VERSION ""

NS_ :

BS_:

BU_: DCM CCU C_ECU C_ECU_GW

BO_ 552 RDR228: 8 C_ECU_GW
 SG_ RDR228_7_0_EYE_TIMEOUT_ERROR_FLG : 56|1@1+ (1,0) [0|1] "" Vector__XXX
 SG_ RDR228_7_1_BLOCKAGE_FORMING_2 : 57|1@1+ (1,0) [0|1] "" Vector__XXX
 SG_ RDR228_7_2_WARN_LCA_R_1ST : 58|1@1+ (1,0) [0|1] "" Vector__XXX
 SG_ RDR228_7_3_WARN_LCA_L_1ST : 59|1@1+ (1,0) [0|1] "" Vector__XXX
 SG_ RDR228_7_4_WARN_LCA_R_2ND : 60|1@1+ (1,0) [0|1] "" Vector__XXX
 SG_ RDR228_7_5_WARN_LCA_L_2ND : 61|1@1+ (1,0) [0|1] "" Vector__XXX
 SG_ RDR228_7_6_WARN_RCTA_R : 62|1@1+ (1,0) [0|1] ""  CCU
 SG_ RDR228_7_7_WARN_RCTA_L : 63|1@1+ (1,0) [0|1] ""  CCU
 SG_ RDR228_6_0_WARN_BSD_R_1ST : 48|1@1+ (1,0) [0|1] "" Vector__XXX
 SG_ RDR228_6_1_WARN_BSD_L_1ST : 49|1@1+ (1,0) [0|1] "" Vector__XXX
 SG_ RDR228_6_2_WARN_BSD_R_2ND : 50|1@1+ (1,0) [0|1] "" Vector__XXX
 SG_ RDR228_6_3_WARN_BSD_L_2ND : 51|1@1+ (1,0) [0|1] "" Vector__XXX
 SG_ RDR228_6_5_BLOCKAGE_STS : 53|3@1+ (1,0) [0|5] "" Vector__XXX
 SG_ RDR228_5_0_BSD_R_E : 40|1@1+ (1,0) [0|1] "" Vector__XXX
 SG_ RDR228_5_1_BSD_L_E : 41|1@1+ (1,0) [0|1] "" Vector__XXX
 SG_ RDR228_5_2_LCA_R_E : 42|1@1+ (1,0) [0|1] "" Vector__XXX
 SG_ RDR228_5_3_LCA_L_E : 43|1@1+ (1,0) [0|1] "" Vector__XXX
 SG_ RDR228_5_4_BSD_R_A : 44|1@1+ (1,0) [0|1] "" Vector__XXX
 SG_ RDR228_5_5_BSD_L_A : 45|1@1+ (1,0) [0|1] "" Vector__XXX
 SG_ RDR228_5_6_LCA_R_A : 46|1@1+ (1,0) [0|1] "" Vector__XXX
 SG_ RDR228_5_7_LCA_L_A : 47|1@1+ (1,0) [0|1] "" Vector__XXX
 SG_ RDR228_4_0_DOW_ACTIVELAMP : 32|1@1+ (1,0) [0|1] "" Vector__XXX
 SG_ RDR228_4_1_WARN_DOW_1ST_R : 33|1@1+ (1,0) [0|1] "" Vector__XXX
 SG_ RDR228_4_2_WARN_DOW_1ST_L : 34|1@1+ (1,0) [0|1] "" Vector__XXX
 SG_ RDR228_4_3_WARN_DOW_2ST_R : 35|1@1+ (1,0) [0|1] "" Vector__XXX
 SG_ RDR228_4_4_WARN_DOW_2ST_L : 36|1@1+ (1,0) [0|1] "" Vector__XXX
 SG_ RDR228_4_5_CSTM_STS_SRVD : 37|1@1+ (1,0) [0|1] ""  CCU
 SG_ RDR228_4_6_CSTM_STS_BSD_LCA_2ND : 38|1@1+ (1,0) [0|1] ""  CCU
 SG_ RDR228_4_7_CSTM_STS_RCTA : 39|1@1+ (1,0) [0|1] ""  CCU
 SG_ RDR228_3_0_WARN_BSD_LCA_R_2ND : 24|1@1+ (1,0) [0|1] ""  CCU
 SG_ RDR228_3_1_WARN_BSD_LCA_L_2ND : 25|1@1+ (1,0) [0|1] ""  CCU
 SG_ RDR228_3_2_CSTM_STS_DOW : 26|1@1+ (1,0) [0|1] ""  CCU
 SG_ RDR228_3_3_CSTM_STS_DOW_SFT_POS : 27|1@1+ (1,0) [0|1] ""  CCU
 SG_ RDR228_3_5_CSTM_DSP_BSD_LCA : 29|1@1+ (1,0) [0|1] ""  CCU
 SG_ RDR228_3_6_CSTM_DSP_BSD_LCA_2ND : 30|1@1+ (1,0) [0|1] ""  CCU
 SG_ RDR228_3_7_CSTM_DSP_RCTA : 31|1@1+ (1,0) [0|1] ""  CCU
 SG_ RDR228_2_0_CSTM_DSP_DOW : 16|1@1+ (1,0) [0|1] ""  CCU
 SG_ RDR228_2_1_EYE_LOCAL_BUS1_FAIL : 17|1@1+ (1,0) [0|1] "" Vector__XXX
 SG_ RDR228_2_2_CSTM_DSP_DOW_SFT_POS : 18|1@1+ (1,0) [0|1] ""  CCU
 SG_ RDR228_2_3_ELK_STOP_REQ_FLG : 19|1@1+ (1,0) [0|1] "" Vector__XXX
 SG_ RDR228_2_4_FAIL_RDRSYS : 20|1@1+ (1,0) [0|1] "" Vector__XXX
 SG_ RDR228_2_5_STOP_RDRSYS : 21|1@1+ (1,0) [0|1] "" Vector__XXX
 SG_ RDR228_2_6_ON_OFF_RDRSYS : 22|1@1+ (1,0) [0|1] ""  CCU
 SG_ RDR228_2_7_BLOCKAGE_FORMING : 23|1@1+ (1,0) [0|1] "" Vector__XXX
 SG_ RDR228_1_0_MSG_COUNTER : 8|4@1+ (1,0) [0|15] ""  CCU
 SG_ RDR228_1_4_BATT_OFF_CAUSE : 12|1@1+ (1,0) [0|1] "" Vector__XXX
 SG_ RDR228_1_5_CSTM_GLO_1 : 13|1@1+ (1,0) [0|1] ""  CCU
 SG_ RDR228_1_6_CSTM_GLO_3 : 14|1@1+ (1,0) [0|1] ""  CCU
 SG_ RDR228_1_7_CSTM_GLO_2 : 15|1@1+ (1,0) [0|1] ""  CCU
 SG_ RDR228_0_0_CHECK_SUM : 0|8@1+ (1,0) [0|255] ""  CCU

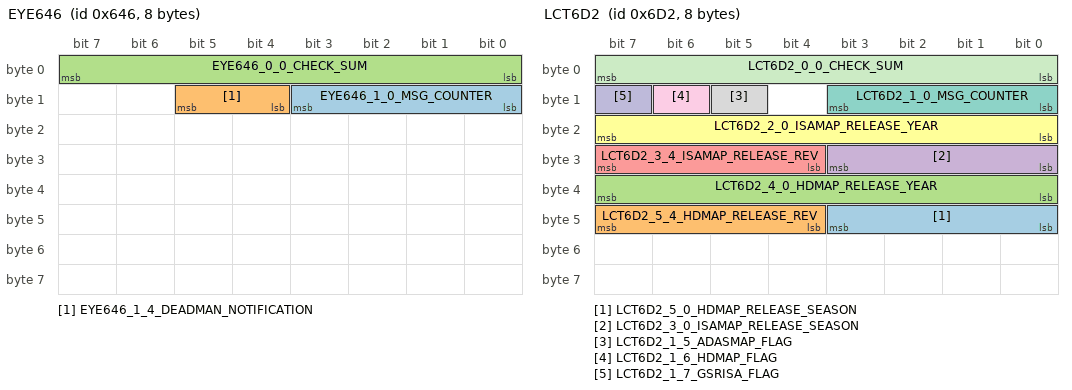
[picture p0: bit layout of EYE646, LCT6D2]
BO_ 1606 EYE646: 8 C_ECU_GW
 SG_ EYE646_1_0_MSG_COUNTER : 8|4@1+ (1,0) [0|15] ""  DCM
 SG_ EYE646_1_4_DEADMAN_NOTIFICATION : 12|2@1+ (1,0) [0|3] ""  DCM
 SG_ EYE646_0_0_CHECK_SUM : 0|8@1+ (1,0) [0|255] ""  DCM

BO_ 965 EYE3C5: 8 C_ECU_GW
 SG_ EYE3C5_7_0_GSR_AEBS_FUNC_INFO : 56|1@1+ (1,0) [0|1] ""  CCU
 SG_ EYE3C5_7_1_CSTM_CRV_ADJUST : 57|2@1+ (1,0) [0|3] ""  CCU
 SG_ EYE3C5_7_3_BRAKE_HAPTIC_CURR : 59|2@1+ (1,0) [0|3] ""  CCU
 SG_ EYE3C5_7_5_SAFETY_MODE_FUNC_INFO : 61|1@1+ (1,0) [0|1] ""  CCU
 SG_ EYE3C5_7_6_SAFETY_MODE_CURR : 62|1@1+ (1,0) [0|1] ""  CCU
 SG_ EYE3C5_7_7_GSR_DDAW_FUNC_INFO : 63|1@1+ (1,0) [0|1] ""  CCU
 SG_ EYE3C5_6_0_IND_SAFETY_MODE : 48|1@1+ (1,0) [0|1] "" Vector__XXX
 SG_ EYE3C5_6_1_ALC_ACTIVE_L : 49|1@1+ (1,0) [0|1] "" Vector__XXX
 SG_ EYE3C5_6_2_FLASHING_IND_SAFETY : 50|1@1+ (1,0) [0|1] "" Vector__XXX
 SG_ EYE3C5_6_3_OVERTAKE_FUNC_INFO : 51|1@1+ (1,0) [0|1] ""  CCU
 SG_ EYE3C5_6_4_CRV_ADJUST_FUNC_INFO : 52|1@1+ (1,0) [0|1] ""  CCU
 SG_ EYE3C5_6_5_STRG_TOUCHSENSOR_WRNG : 53|1@1+ (1,0) [0|1] "" Vector__XXX
 SG_ EYE3C5_6_6_ALC_ACTIVE_R : 54|1@1+ (1,0) [0|1] "" Vector__XXX
 SG_ EYE3C5_6_7_CSTM_GSR_ISA : 55|1@1+ (1,0) [0|1] ""  CCU
 SG_ EYE3C5_5_0_LANE_COLOR_R : 40|2@1+ (1,0) [0|3] "" Vector__XXX
 SG_ EYE3C5_5_2_LINE_LANE_R : 42|2@1+ (1,0) [0|3] "" Vector__XXX
 SG_ EYE3C5_5_4_LANE_COLOR_L : 44|2@1+ (1,0) [0|3] "" Vector__XXX
 SG_ EYE3C5_5_6_LINE_LANE_L : 46|2@1+ (1,0) [0|3] "" Vector__XXX
 SG_ EYE3C5_4_0_ROAD_SHAPE_CURVE : 32|4@1+ (1,0) [0|15] "" Vector__XXX
 SG_ EYE3C5_4_4_ROAD_SHAPE_DIRECTION : 36|1@1+ (1,0) [0|1] "" Vector__XXX
 SG_ EYE3C5_4_5_CSTM_GSR_ELKS : 37|1@1+ (1,0) [0|1] ""  CCU
 SG_ EYE3C5_4_6_MY_WAY_COLOR : 38|2@1+ (1,0) [0|3] "" Vector__XXX
 SG_ EYE3C5_3_0_AD_DRV_ICON : 24|2@1+ (1,0) [0|3] "" Vector__XXX
 SG_ EYE3C5_3_2_AUTO_HANDLE_ICON : 26|2@1+ (1,0) [0|3] "" Vector__XXX
 SG_ EYE3C5_3_4_WITH_HANDS_ICON : 28|1@1+ (1,0) [0|1] ""  CCU
 SG_ EYE3C5_3_5_STRG_HAPTIC_WRNG : 29|1@1+ (1,0) [0|1] "" Vector__XXX
 SG_ EYE3C5_3_6_BRK_HPTC_FUNC_INFO : 30|1@1+ (1,0) [0|1] ""  CCU
 SG_ EYE3C5_3_7_SPECIAL_DISP_INFO : 31|1@1+ (1,0) [0|1] ""  CCU
 SG_ EYE3C5_2_0_SLOWDWN_CURVE_ICON : 16|3@1+ (1,0) [0|7] "" Vector__XXX
 SG_ EYE3C5_2_3_FLASHING_IND : 19|1@1+ (1,0) [0|1] "" Vector__XXX
 SG_ EYE3C5_2_4_ATTENTION_TOLLGATE : 20|2@1+ (1,0) [0|3] "" Vector__XXX
 SG_ EYE3C5_2_6_MAPLOCATOR_IND : 22|2@1+ (1,0) [0|3] "" Vector__XXX
 SG_ EYE3C5_1_0_MSG_COUNTER : 8|4@1+ (1,0) [0|15] "" Vector__XXX
 SG_ EYE3C5_1_4_ISA_FAIL_IND : 12|1@1+ (1,0) [0|1] "" Vector__XXX
 SG_ EYE3C5_1_5_SLWF_OFF_IND : 13|1@1+ (1,0) [0|1] "" Vector__XXX
 SG_ EYE3C5_1_6_CSTM_SLWF_SET : 14|1@1+ (1,0) [0|1] ""  CCU
 SG_ EYE3C5_1_7_CSTM_TSR_SOUND_SET : 15|1@1+ (1,0) [0|1] ""  CCU
 SG_ EYE3C5_0_0_CHECK_SUM : 0|8@1+ (1,0) [0|255] "" Vector__XXX

BO_ 964 EYE3C4: 8 C_ECU_GW
 SG_ EYE3C4_7_0_PCR_FAIL_OFF_IND : 56|2@1+ (1,0) [0|3] "" Vector__XXX
 SG_ EYE3C4_7_2_AES_FAIL_OFF_IND : 58|2@1+ (1,0) [0|3] "" Vector__XXX
 SG_ EYE3C4_7_4_LDP_FAIL_OFF_IND : 60|2@1+ (1,0) [0|3] "" Vector__XXX
 SG_ EYE3C4_7_6_ELK_FAIL_OFF_IND : 62|2@1+ (1,0) [0|3] "" Vector__XXX
 SG_ EYE3C4_6_0_MCAM_SYS_FAIL_HALT : 48|2@1+ (1,0) [0|3] "" Vector__XXX
 SG_ EYE3C4_6_2_MCAM_FUNC_INFO : 50|1@1+ (1,0) [0|1] "" Vector__XXX
 SG_ EYE3C4_6_3_EYE_DRV_ACTION_REQ : 51|3@1+ (1,0) [0|7] "" Vector__XXX
 SG_ EYE3C4_6_6_LDW_SND_OFF_FAIL_IND : 54|2@1+ (1,0) [0|3] "" Vector__XXX
 SG_ EYE3C4_5_0_EAM_GREEN : 40|2@1+ (1,0) [0|3] "" Vector__XXX
 SG_ EYE3C4_5_2_EAM_BLUE : 42|2@1+ (1,0) [0|3] "" Vector__XXX
 SG_ EYE3C4_5_4_EAM_GREEN_2 : 44|2@1+ (1,0) [0|3] "" Vector__XXX
 SG_ EYE3C4_5_6_FCW_SND_OFF_FAIL_IND : 46|2@1+ (1,0) [0|3] "" Vector__XXX
 SG_ EYE3C4_4_0_EAM_YELLOW : 32|4@1+ (1,0) [0|15] "" Vector__XXX
 SG_ EYE3C4_4_4_EAM_RED : 36|4@1+ (1,0) [0|15] "" Vector__XXX
 SG_ EYE3C4_3_0_CODE_NO_BUZZER : 24|8@1+ (1,0) [0|255] "" Vector__XXX
 SG_ EYE3C4_2_0_CODE_WARN : 16|8@1+ (1,0) [0|255] ""  CCU
 SG_ EYE3C4_1_0_MSG_COUNTER : 8|4@1+ (1,0) [0|15] "" Vector__XXX
 SG_ EYE3C4_1_5_SNR_DRV_ACTION_REQ : 13|3@1+ (1,0) [0|7] "" Vector__XXX
 SG_ EYE3C4_0_0_CHECK_SUM : 0|8@1+ (1,0) [0|255] "" Vector__XXX

BO_ 805 EYE325: 8 C_ECU_GW
 SG_ EYE325_6_5_SONAR_DISP_INT : 53|1@1+ (1,0) [0|1] "" Vector__XXX
 SG_ EYE325_5_0_SONAR_R_L_CORNER_4LVL : 40|3@1+ (1,0) [0|7] ""  CCU
 SG_ EYE325_5_3_SONAR_R_R_CORNER_4LVL : 43|3@1+ (1,0) [0|7] ""  CCU
 SG_ EYE325_4_0_SONAR_R_CENTER : 32|3@1+ (1,0) [0|7] ""  CCU
 SG_ EYE325_4_3_SONAR_LEVEL : 35|3@1+ (1,0) [0|7] "" Vector__XXX
 SG_ EYE325_4_6_RAB_WARNING : 38|2@1+ (1,0) [0|3] ""  CCU
 SG_ EYE325_3_0_SONAR_R_L_CORNER : 24|2@1+ (1,0) [0|3] "" Vector__XXX
 SG_ EYE325_3_2_SONAR_R_R_CORNER : 26|2@1+ (1,0) [0|3] "" Vector__XXX
 SG_ EYE325_3_4_SONAR_R_L_SIDE : 28|2@1+ (1,0) [0|3] "" Vector__XXX
 SG_ EYE325_3_6_SONAR_R_R_SIDE : 30|2@1+ (1,0) [0|3] "" Vector__XXX
 SG_ EYE325_2_0_RAB_OFF : 16|1@1+ (1,0) [0|1] ""  CCU
 SG_ EYE325_2_1_SONAR_OFF : 17|1@1+ (1,0) [0|1] ""  CCU
 SG_ EYE325_2_2_SONAR_SYS_HALT : 18|2@1+ (1,0) [0|3] ""  CCU
 SG_ EYE325_2_4_SONAR_SYS_FAIL : 20|2@1+ (1,0) [0|3] ""  CCU
 SG_ EYE325_2_6_RAB_DISABLE : 22|1@1+ (1,0) [0|1] ""  CCU
 SG_ EYE325_2_7_SONAR_DISABLE : 23|1@1+ (1,0) [0|1] ""  CCU
 SG_ EYE325_1_0_MSG_COUNTER : 8|4@1+ (1,0) [0|15] ""  CCU
 SG_ EYE325_1_4_CSTM_RAB_SET : 12|1@1+ (1,0) [0|1] ""  CCU
 SG_ EYE325_1_5_CSTM_CLR_SNR_SET : 13|1@1+ (1,0) [0|1] ""  CCU
 SG_ EYE325_1_6_RAB : 14|1@1+ (1,0) [0|1] ""  CCU
 SG_ EYE325_1_7_SONAR_NO_DISP : 15|1@1+ (1,0) [0|1] "" Vector__XXX
 SG_ EYE325_0_0_CHECK_SUM : 0|8@1+ (1,0) [0|255] ""  CCU

BO_ 803 EYE323: 8 C_ECU_GW
 SG_ EYE323_7_0_ISA_OFFSET_CURR : 56|5@1+ (1,-10) [-10|10] ""  CCU
 SG_ EYE323_7_5_SLIF_FUNC_INFO : 61|1@1+ (1,0) [0|1] ""  CCU
 SG_ EYE323_7_6_ISA_FUNC_INFO : 62|1@1+ (1,0) [0|1] ""  CCU
 SG_ EYE323_7_7_ISA_CUSTOMIZE_CURR : 63|1@1+ (1,0) [0|1] ""  CCU
 SG_ EYE323_6_0_LDW_OFFSW_INFO : 48|1@1+ (1,0) [0|1] "" Vector__XXX
 SG_ EYE323_6_1_LDW_ON_OFF_SET : 49|1@1+ (1,0) [0|1] ""  CCU
 SG_ EYE323_6_2_CSTM_DDAW_WARN_SET : 50|1@1+ (1,0) [0|1] ""  CCU
 SG_ EYE323_6_3_IACC_FUNC_INFO : 51|1@1+ (1,0) [0|1] ""  CCU
 SG_ EYE323_6_5_CSTM_LDW_TIMING_SET : 53|1@1+ (1,0) [0|1] ""  CCU
 SG_ EYE323_6_6_CSTM_LDW_TIMING : 54|1@1+ (1,0) [0|1] ""  CCU
 SG_ EYE323_6_7_SLOWDOWNL_FUNC_INFO : 55|1@1+ (1,0) [0|1] ""  CCU
 SG_ EYE323_5_0_CNG_GRN_CONT_CURR : 40|1@1+ (1,0) [0|1] ""  CCU
 SG_ EYE323_5_1_TRAFFIC_FUNC_INFO : 41|1@1+ (1,0) [0|1] ""  CCU
 SG_ EYE323_5_2_FCW_OFFSW_INFO : 42|1@1+ (1,0) [0|1] "" Vector__XXX
 SG_ EYE323_5_3_FCW_ON_OFF_SET : 43|1@1+ (1,0) [0|1] ""  CCU
 SG_ EYE323_5_4_WARNING_SEL_CURR : 44|1@1+ (1,0) [0|1] ""  CCU
 SG_ EYE323_5_5_HAPT_FUNC_INFO : 45|1@1+ (1,0) [0|1] ""  CCU
 SG_ EYE323_5_6_TOLLGATE_CONT_CURR : 46|1@1+ (1,0) [0|1] ""  CCU
 SG_ EYE323_5_7_CURVE_CONT_CURR : 47|1@1+ (1,0) [0|1] ""  CCU
 SG_ EYE323_4_0_FCTB_ICON_L : 32|2@1+ (1,0) [0|3] "" Vector__XXX
 SG_ EYE323_4_2_FCTB_ICON_R : 34|2@1+ (1,0) [0|3] "" Vector__XXX
 SG_ EYE323_4_4_FCW_CONT_CURR : 36|2@1+ (1,0) [0|3] ""  CCU
 SG_ EYE323_4_6_FCW_DISPLAY_SEL : 38|2@1+ (1,0) [0|3] ""  CCU
 SG_ EYE323_3_0_AES_FUNC_INFO : 24|1@1+ (1,0) [0|1] "" Vector__XXX
 SG_ EYE323_3_1_CSTM_TSR_NO_ENTRY_SET : 25|1@1+ (1,0) [0|1] ""  CCU
 SG_ EYE323_3_2_CSTM_TSR_STOP_SET : 26|1@1+ (1,0) [0|1] ""  CCU
 SG_ EYE323_3_3_CSTM_TSR_GIVE_WAY_SET : 27|1@1+ (1,0) [0|1] ""  CCU
 SG_ EYE323_3_4_WILDERNESS : 28|1@1+ (1,0) [0|1] "" Vector__XXX
 SG_ EYE323_3_5_AES_OFF : 29|1@1+ (1,0) [0|1] "" Vector__XXX
 SG_ EYE323_3_6_FCTB_IND : 30|2@1+ (1,0) [0|3] "" Vector__XXX
 SG_ EYE323_2_0_CSTM_LDW_ALK_B : 16|2@1+ (1,0) [0|3] ""  CCU
 SG_ EYE323_2_2_CSTM_P_CR : 18|1@1+ (1,0) [0|1] ""  CCU
 SG_ EYE323_2_3_SLOWDOWN_FUNC_INFO2 : 19|1@1+ (1,0) [0|1] ""  CCU
 SG_ EYE323_2_4_CID_CODE_WARN : 20|4@1+ (1,0) [0|15] ""  CCU
 SG_ EYE323_1_0_MSG_COUNTER : 8|4@1+ (1,0) [0|15] ""  CCU
 SG_ EYE323_1_4_DISP_FOLLOW_FORWARD : 12|1@1+ (1,0) [0|1] "" Vector__XXX
 SG_ EYE323_1_5_KEEP_LINE_SENTER_ACT : 13|1@1+ (1,0) [0|1] ""  CCU
 SG_ EYE323_1_6_DDAW_FAIL_OFF : 14|2@1+ (1,0) [0|3] "" Vector__XXX
 SG_ EYE323_0_0_CHECK_SUM : 0|8@1+ (1,0) [0|255] ""  CCU

BO_ 802 EYE322: 8 C_ECU_GW
 SG_ EYE322_7_0_CSTM_ACC_CONT_SET : 56|2@1+ (1,0) [0|3] ""  CCU
 SG_ EYE322_7_2_ELK_OFF_IND : 58|1@1+ (1,0) [0|1] ""  CCU
 SG_ EYE322_7_3_LIGHT_EAM_YELLOW : 59|2@1+ (1,0) [0|3] "" Vector__XXX
 SG_ EYE322_7_5_BROKEN_LINE_L : 61|1@1+ (1,0) [0|1] "" Vector__XXX
 SG_ EYE322_7_6_TJA_ACTIVE : 62|1@1+ (1,0) [0|1] "" Vector__XXX
 SG_ EYE322_7_7_BROKEN_LINE_R : 63|1@1+ (1,0) [0|1] "" Vector__XXX
 SG_ EYE322_6_0_CSTM_MIS_AT_START : 48|2@1+ (1,0) [0|3] ""  CCU
 SG_ EYE322_6_2_CSTM_ALK_TJA_SET : 50|1@1+ (1,0) [0|1] ""  CCU
 SG_ EYE322_6_3_CSTM_LANE_SET : 51|1@1+ (1,0) [0|1] ""  CCU
 SG_ EYE322_6_4_LDP_OFF_IND : 52|1@1+ (1,0) [0|1] "" Vector__XXX
 SG_ EYE322_6_5_INDICATOR_MODE_L : 53|2@1+ (1,0) [0|3] "" Vector__XXX
 SG_ EYE322_6_7_CSTM_ELK_SET : 55|1@1+ (1,0) [0|1] ""  CCU
 SG_ EYE322_5_0_CSTM_MIS_AT_BACK : 40|1@1+ (1,0) [0|1] ""  CCU
 SG_ EYE322_5_1_CSTM_ALK_TJA : 41|1@1+ (1,0) [0|1] "" Vector__XXX
 SG_ EYE322_5_2_CSTM_SAS : 42|1@1+ (1,0) [0|1] ""  CCU
 SG_ EYE322_5_3_CSTM_HBA : 43|1@1+ (1,0) [0|1] "" Vector__XXX
 SG_ EYE322_5_4_CSTM_ACC_CONT : 44|1@1+ (1,0) [0|1] ""  CCU
 SG_ EYE322_5_5_CSTM_LANE : 45|1@1+ (1,0) [0|1] ""  CCU
 SG_ EYE322_5_6_LDW_SOUND_OFF_IND : 46|1@1+ (1,0) [0|1] "" Vector__XXX
 SG_ EYE322_5_7_CSTM_ELK_SET : 47|1@1+ (1,0) [0|1] ""  CCU
 SG_ EYE322_4_0_CODE_WARN : 32|5@1+ (1,0) [0|31] ""  CCU
 SG_ EYE322_4_5_CSTM_GSR : 37|1@1+ (1,0) [0|1] "" Vector__XXX
 SG_ EYE322_3_0_LANE_L : 24|2@1+ (1,0) [0|3] "" Vector__XXX
 SG_ EYE322_3_2_LANE_R : 26|2@1+ (1,0) [0|3] "" Vector__XXX
 SG_ EYE322_3_4_LANE_L_COLOR : 28|2@1+ (1,0) [0|3] "" Vector__XXX
 SG_ EYE322_3_6_LANE_R_COLOR : 30|2@1+ (1,0) [0|3] "" Vector__XXX
 SG_ EYE322_2_0_FCW_OFF_IND : 16|1@1+ (1,0) [0|1] ""  CCU
 SG_ EYE322_2_1_MOV_EYESIGHT_SCREEN : 17|1@1+ (1,0) [0|1] "" Vector__XXX
 SG_ EYE322_2_2_ALK_ICON : 18|2@1+ (1,0) [0|3] ""  CCU
 SG_ EYE322_2_4_INDICATOR_CTRL_REQ : 20|1@1+ (1,0) [0|1] "" Vector__XXX
 SG_ EYE322_2_5_INDICATOR_MODE_R : 21|2@1+ (1,0) [0|3] "" Vector__XXX
 SG_ EYE322_2_7_LIMITER_BACK_SPEED : 23|1@1+ (1,0) [0|1] "" Vector__XXX
 SG_ EYE322_1_0_MSG_COUNTER : 8|4@1+ (1,0) [0|15] ""  CCU
 SG_ EYE322_1_4_CODE_NO_BUZZER : 12|3@1+ (1,0) [0|7] ""  CCU
 SG_ EYE322_1_7_DISTWARN_DMS : 15|1@1+ (1,0) [0|1] "" Vector__XXX
 SG_ EYE322_0_0_CHECK_SUM : 0|8@1+ (1,0) [0|255] ""  CCU

BO_ 801 EYE321: 8 C_ECU_GW
 SG_ EYE321_7_0_INFO_DIST_FORWARD : 56|4@1+ (1,0) [0|15] ""  CCU
 SG_ EYE321_7_4_INFO_KEEP_STOP : 60|1@1+ (1,0) [0|1] "" Vector__XXX
 SG_ EYE321_7_5_INFO_READY : 61|1@1+ (1,0) [0|1] "" Vector__XXX
 SG_ EYE321_7_6_INFO_SET_CC : 62|1@1+ (1,0) [0|1] ""  CCU
 SG_ EYE321_7_7_INFO_OFF : 63|1@1+ (1,0) [0|1] "" Vector__XXX
 SG_ EYE321_6_0_FAIL_EYESIGHT : 48|1@1+ (1,0) [0|1] ""  DCM,CCU
 SG_ EYE321_6_1_MOV_EYESIGHT_SCREEN : 49|1@1+ (1,0) [0|1] "" Vector__XXX
 SG_ EYE321_6_2_IND_VEHICLE : 50|1@1+ (1,0) [0|1] "" Vector__XXX
 SG_ EYE321_6_3_BRAKELAMP_VEHICLE : 51|1@1+ (1,0) [0|1] "" Vector__XXX
 SG_ EYE321_6_4_IND_FORWARD_VECL : 52|1@1+ (1,0) [0|1] "" Vector__XXX
 SG_ EYE321_6_5_BRAKELAMP_FORWARD : 53|1@1+ (1,0) [0|1] "" Vector__XXX
 SG_ EYE321_6_6_CC_OR_LIM_SON : 54|1@1+ (1,0) [0|1] "" Vector__XXX
 SG_ EYE321_6_7_TEMP_OFF_STATE : 55|1@1+ (1,0) [0|1] "" Vector__XXX
 SG_ EYE321_5_0_INFO_SET_SPD : 40|8@1+ (1,0) [0|255] "km/h or MPH"  CCU
 SG_ EYE321_4_0_ACC_MODE : 32|2@1+ (1,0) [0|3] ""  CCU
 SG_ EYE321_4_2_SRVD_LASTMEM_ST_REQ : 34|1@1+ (1,0) [0|1] "" Vector__XXX
 SG_ EYE321_4_3_INFO_MAIN_CC : 35|2@1+ (1,0) [0|3] "" Vector__XXX
 SG_ EYE321_4_5_TRAFFIC_LIGHT : 37|3@1+ (1,0) [0|7] "" Vector__XXX
 SG_ EYE321_3_0_CODE_HALT : 24|3@1+ (1,0) [0|7] ""  CCU
 SG_ EYE321_3_3_ELK_EQUIP : 27|1@1+ (1,0) [0|1] ""  CCU
 SG_ EYE321_3_4_SET_DIST : 28|3@1+ (1,0) [0|7] "" Vector__XXX
 SG_ EYE321_3_7_TJA : 31|1@1+ (1,0) [0|1] ""  CCU
 SG_ EYE321_2_0_ACC_CANCEL_OR_CSTM : 16|4@1+ (1,0) [0|15] "" Vector__XXX
 SG_ EYE321_2_4_ALK_CANCEL_OR_CSTM : 20|3@1+ (1,0) [0|7] "" Vector__XXX
 SG_ EYE321_2_7_ALK_CANCEL_DISP_TYPE : 23|1@1+ (1,0) [0|1] "" Vector__XXX
 SG_ EYE321_1_0_MSG_COUNTER : 8|4@1+ (1,0) [0|15] ""  DCM,CCU
 SG_ EYE321_1_4_PRECRASH_BRAKE_OFF : 12|1@1+ (1,0) [0|1] ""  CCU
 SG_ EYE321_1_5_LANE_DEPARTURE_OFF : 13|1@1+ (1,0) [0|1] ""  CCU
 SG_ EYE321_1_6_MET_AD_DRV_ASS : 14|1@1+ (1,0) [0|1] "" Vector__XXX
 SG_ EYE321_1_7_ALC_EQUIP : 15|1@1+ (1,0) [0|1] "" Vector__XXX
 SG_ EYE321_0_0_CHECK_SUM : 0|8@1+ (1,0) [0|255] ""  DCM,CCU

BO_ 1746 LCT6D2: 8 C_ECU_GW
 SG_ LCT6D2_5_0_HDMAP_RELEASE_SEASON : 40|4@1+ (1,0) [0|4] ""  CCU
 SG_ LCT6D2_5_4_HDMAP_RELEASE_REV : 44|4@1+ (1,0) [1|14] ""  CCU
 SG_ LCT6D2_4_0_HDMAP_RELEASE_YEAR : 32|8@1+ (1,2000) [2000|2099] "年"  CCU
 SG_ LCT6D2_3_0_ISAMAP_RELEASE_SEASON : 24|4@1+ (1,0) [1|4] ""  CCU
 SG_ LCT6D2_3_4_ISAMAP_RELEASE_REV : 28|4@1+ (1,0) [1|14] ""  CCU
 SG_ LCT6D2_2_0_ISAMAP_RELEASE_YEAR : 16|8@1+ (1,2000) [0|99] "年"  CCU
 SG_ LCT6D2_1_0_MSG_COUNTER : 8|4@1+ (1,0) [0|15] ""  CCU
 SG_ LCT6D2_1_5_ADASMAP_FLAG : 13|1@1+ (1,0) [0|1] ""  CCU
 SG_ LCT6D2_1_6_HDMAP_FLAG : 14|1@1+ (1,0) [0|1] ""  CCU
 SG_ LCT6D2_1_7_GSRISA_FLAG : 15|1@1+ (1,0) [0|1] ""  CCU
 SG_ LCT6D2_0_0_CHECK_SUM : 0|8@1+ (1,0) [0|255] ""  CCU

BO_ 845 ADAS34D: 32 C_ECU_GW
 SG_ ADAS34D_16_0_CSTM_SNR_DSPREEQ : 128|2@1+ (1,0) [0|3] ""  CCU
 SG_ ADAS34D_16_2_CSTM_RAB_DSPREQ : 130|2@1+ (1,0) [0|3] ""  CCU
 SG_ ADAS34D_16_4_CSTM_PED_DSPREQ : 132|2@1+ (1,0) [0|3] ""  CCU
 SG_ ADAS34D_16_6_CSTM_PEDTIM_DSPREQ : 134|2@1+ (1,0) [0|3] ""  CCU
 SG_ ADAS34D_15_0_CSTM_SNR_CLEAR : 120|1@1+ (1,0) [0|1] ""  CCU
 SG_ ADAS34D_15_1_CSTM_RAB : 121|1@1+ (1,0) [0|1] ""  CCU
 SG_ ADAS34D_15_2_CSTM_RAB_PED : 122|1@1+ (1,0) [0|1] ""  CCU
 SG_ ADAS34D_15_3_CSTM_RAB_PED_TIMING : 123|2@1+ (1,0) [0|3] ""  CCU
 SG_ ADAS34D_15_5_CSTM_TEMP_OFF : 125|2@1+ (1,0) [0|3] ""  CCU
 SG_ ADAS34D_15_7_TEMP_OFF_STATE : 127|1@1+ (1,0) [0|1] "" Vector__XXX
 SG_ ADAS34D_14_0_RAB_WARNING : 112|3@1+ (1,0) [0|7] ""  CCU
 SG_ ADAS34D_14_3_SONAR_LEVEL : 115|5@1+ (1,0) [0|8] "" Vector__XXX
 SG_ ADAS34D_13_0_PED_WARN_CENTER : 104|1@1+ (1,0) [0|1] "" Vector__XXX
 SG_ ADAS34D_13_1_PED_WARN_LEFT : 105|1@1+ (1,0) [0|1] "" Vector__XXX
 SG_ ADAS34D_13_2_PED_WARN_RIGHT : 106|1@1+ (1,0) [0|1] "" Vector__XXX
 SG_ ADAS34D_13_3_RAB_TRIG_TYPE : 107|2@1+ (1,0) [0|3] "" Vector__XXX
 SG_ ADAS34D_9_0_SONAR_R_R_CORNER_4LV : 72|3@1+ (1,0) [0|7] ""  CCU
 SG_ ADAS34D_8_0_SONAR_DISP_INT : 64|1@1+ (1,0) [0|1] "" Vector__XXX
 SG_ ADAS34D_8_1_SONAR_R_CENTER : 65|3@1+ (1,0) [0|7] ""  CCU
 SG_ ADAS34D_8_4_SONAR_R_L_CORNER_4LV : 68|3@1+ (1,0) [0|7] ""  CCU
 SG_ ADAS34D_7_0_SONAR_SYS_FAIL : 56|2@1+ (1,0) [0|3] "" Vector__XXX
 SG_ ADAS34D_7_2_RAB_HALT : 58|2@1+ (1,0) [0|3] "" Vector__XXX
 SG_ ADAS34D_7_4_CAMERA_FAIL : 60|2@1+ (1,0) [0|3] "" Vector__XXX
 SG_ ADAS34D_7_6_RAB_PED_HALT : 62|2@1+ (1,0) [0|3] "" Vector__XXX
 SG_ ADAS34D_6_0_REQ_ACT_EPB : 48|1@1+ (1,0) [0|1] "" Vector__XXX
 SG_ ADAS34D_6_1_STOP_HOJI_BUZ_ACT : 49|1@1+ (1,0) [0|1] "" Vector__XXX
 SG_ ADAS34D_6_2_RAB_OFF : 50|1@1+ (1,0) [0|1] "" Vector__XXX
 SG_ ADAS34D_6_3_SONAR_OFF : 51|1@1+ (1,0) [0|1] "" Vector__XXX
 SG_ ADAS34D_6_4_RAB_PED_OFF : 52|1@1+ (1,0) [0|1] "" Vector__XXX
 SG_ ADAS34D_6_5_SONAR_HALT : 53|2@1+ (1,0) [0|3] "" Vector__XXX
 SG_ ADAS34D_5_0_YOATSU_ACT : 40|1@1+ (1,0) [0|1] "" Vector__XXX
 SG_ ADAS34D_5_1_TORQUE_LIM_ACT : 41|1@1+ (1,0) [0|1] "" Vector__XXX
 SG_ ADAS34D_5_2_TORQUE_LIM_VAL : 42|6@1+ (0.01,0) [0|0.63] "G" Vector__XXX
 SG_ ADAS34D_4_0_RAB_ACT : 32|1@1+ (1,0) [0|1] "" Vector__XXX
 SG_ ADAS34D_4_1_RAB_VAL : 33|7@1+ (0.01,0) [0|1.27] "G" Vector__XXX
 SG_ ADAS34D_3_0_RAB : 24|1@1+ (1,0) [0|1] ""  CCU
 SG_ ADAS34D_3_1_RAB_PED : 25|1@1+ (1,0) [0|1] "" Vector__XXX
 SG_ ADAS34D_2_0_E2E_COUNTER : 16|8@1+ (1,0) [0|255] ""  CCU
 SG_ ADAS34D_0_0_E2E_CRC : 0|16@1+ (1,0) [0|65535] ""  CCU

BO_ 844 ADAS34C: 32 C_ECU_GW
 SG_ ADAS34C_25_0_CSTM_ADDON_DISP_CNT : 200|1@1+ (1,0) [0|1] ""  CCU
 SG_ ADAS34C_25_1_CSTM_LANE_SET_CONT : 201|1@1+ (1,0) [0|1] ""  CCU
 SG_ ADAS34C_24_0_CSTM_LSW : 192|1@1+ (1,0) [0|1] ""  CCU
 SG_ ADAS34C_24_1_CSTM_GREEN_LIGHT : 193|1@1+ (1,0) [0|1] ""  CCU
 SG_ ADAS34C_24_2_CSTM_LANE_SET : 194|1@1+ (1,0) [0|1] ""  CCU
 SG_ ADAS34C_24_3_CSTM_PROPOSAL_HMI : 195|1@1+ (1,0) [0|1] ""  CCU
 SG_ ADAS34C_24_4_CSTM_V2N : 196|1@1+ (1,0) [0|1] ""  CCU
 SG_ ADAS34C_24_5_CSTM_DATA_COLLECT : 197|1@1+ (1,0) [0|1] ""  CCU
 SG_ ADAS34C_24_6_CSTM_COLLECT_IMAGE : 198|1@1+ (1,0) [0|1] ""  CCU
 SG_ ADAS34C_24_7_CSTM_COLLECT_LOC : 199|1@1+ (1,0) [0|1] ""  CCU
 SG_ ADAS34C_22_0_DATA_COLLECT_DISP : 176|2@1+ (1,0) [0|3] ""  CCU
 SG_ ADAS34C_22_2_COLLECT_IMAGE_DISP : 178|2@1+ (1,0) [0|3] ""  CCU
 SG_ ADAS34C_22_4_COLLECT_LOC_DISP : 180|2@1+ (1,0) [0|3] ""  CCU
 SG_ ADAS34C_21_0_LSW_DISP_CONT : 168|2@1+ (1,0) [0|3] ""  CCU
 SG_ ADAS34C_21_2_GREEN_LIGHT_DISP : 170|2@1+ (1,0) [0|3] ""  CCU
 SG_ ADAS34C_21_4_LANE_SET_DISP_CONT : 172|2@1+ (1,0) [0|3] ""  CCU
 SG_ ADAS34C_21_6_PROPOSAL_HMI_DISP : 174|2@1+ (1,0) [0|3] ""  CCU
 SG_ ADAS34C_20_0_ADD_ON_DISP_CONT : 160|2@1+ (1,0) [0|3] ""  CCU
 SG_ ADAS34C_20_2_V2N_DISP_CONT : 162|2@1+ (1,0) [0|3] ""  CCU
 SG_ ADAS34C_20_4_LANE_SET_PTN_DISP : 164|2@1+ (1,0) [0|3] ""  CCU
 SG_ ADAS34C_18_0_CSTM_SUPPRESS_SPEED : 144|1@1+ (1,0) [0|1] ""  CCU
 SG_ ADAS34C_18_1_SUPPRESS_SPD_LEVEL : 145|2@1+ (1,0) [0|3] ""  CCU
 SG_ ADAS34C_18_3_ACTIVE_AVOIDANCE : 147|1@1+ (1,0) [0|1] ""  CCU
 SG_ ADAS34C_18_4_ACTIVE_AVOIDANCE_LV : 148|2@1+ (1,0) [0|3] ""  CCU
 SG_ ADAS34C_17_0_CSTM_PDA_CURR : 136|1@1+ (1,0) [0|1] ""  CCU
 SG_ ADAS34C_17_1_TARGET_VEHICLE : 137|1@1+ (1,0) [0|1] ""  CCU
 SG_ ADAS34C_17_2_TARGET_SURROUNDING : 138|1@1+ (1,0) [0|1] ""  CCU
 SG_ ADAS34C_17_3_TARGET_SLOPE_DOWN : 139|1@1+ (1,0) [0|1] ""  CCU
 SG_ ADAS34C_17_4_CUS_SUPPRESS_SPDTGT : 140|1@1+ (1,0) [0|1] ""  CCU
 SG_ ADAS34C_15_0_A_AVOIDANCE_DISP : 120|2@1+ (1,0) [0|3] ""  CCU
 SG_ ADAS34C_15_2_A_AVOIDANCE_LV_DISP : 122|2@1+ (1,0) [0|3] ""  CCU
 SG_ ADAS34C_15_4_A_AVOIDANCE_LV_PTN : 124|2@1+ (1,0) [0|3] ""  CCU
 SG_ ADAS34C_14_0_SUPPRESS_SPDTGT_DSP : 112|2@1+ (1,0) [0|3] ""  CCU
 SG_ ADAS34C_14_2_TARGET_VEHICLE_DISP : 114|2@1+ (1,0) [0|3] ""  CCU
 SG_ ADAS34C_14_4_TARGET_SURROUND_DSP : 116|2@1+ (1,0) [0|3] ""  CCU
 SG_ ADAS34C_14_6_TGT_SLOPE_DOWN_DSP : 118|2@1+ (1,0) [0|3] ""  CCU
 SG_ ADAS34C_13_0_PDA_DISP_CONT : 104|2@1+ (1,0) [0|3] ""  CCU
 SG_ ADAS34C_13_2_SUPPRESS_SPD_DISP : 106|2@1+ (1,0) [0|3] ""  CCU
 SG_ ADAS34C_13_4_SUPPRESS_SPDLV_DISP : 108|2@1+ (1,0) [0|3] ""  CCU
 SG_ ADAS34C_13_6_SUPPRESS_SPD_LV_PTN : 110|2@1+ (1,0) [0|3] ""  CCU
 SG_ ADAS34C_11_0_ISA_OFS_U50_DISP : 88|2@1+ (1,0) [0|3] ""  CCU
 SG_ ADAS34C_11_2_ISA_OFS_OV50_DISP : 90|2@1+ (1,0) [0|3] ""  CCU
 SG_ ADAS34C_10_0_SLWF_OFFSET_OV50 : 80|5@1+ (1,0) [0|31] ""  CCU
 SG_ ADAS34C_9_0_SLWF_OFFSET_U50 : 72|5@1+ (1,0) [0|31] ""  CCU
 SG_ ADAS34C_9_5_CSTM_SLWF : 77|1@1+ (1,0) [0|1] ""  CCU
 SG_ ADAS34C_9_6_CSTM_SLWF_OFS_CONT : 78|1@1+ (1,0) [0|1] ""  CCU
 SG_ ADAS34C_9_7_ISA_IACC_OFS_CONT : 79|1@1+ (1,0) [0|1] ""  CCU
 SG_ ADAS34C_8_0_ISA_IACC_OFFSET_OV50 : 64|5@1+ (1,0) [0|31] ""  CCU
 SG_ ADAS34C_8_5_SIGN_SWITCH_SOUND : 69|1@1+ (1,0) [0|1] ""  CCU
 SG_ ADAS34C_8_6_CSTM_LOADSIGNS_SYS : 70|1@1+ (1,0) [0|1] ""  CCU
 SG_ ADAS34C_8_7_CSTM_ISA_IACC_CONT : 71|1@1+ (1,0) [0|1] ""  CCU
 SG_ ADAS34C_7_0_ISA_IACC_OFFSET_U50 : 56|5@1+ (1,0) [0|31] ""  CCU
 SG_ ADAS34C_7_5_CSTM_LOADSIGNS_ADD : 61|1@1+ (1,0) [0|1] ""  CCU
 SG_ ADAS34C_7_6_CSTM_ISA_IACC_ACCEPT : 62|2@1+ (1,0) [0|3] ""  CCU
 SG_ ADAS34C_6_0_ISA_IACC_PTN_DISP : 48|2@1+ (1,0) [0|3] ""  CCU
 SG_ ADAS34C_6_2_SLWF_OFS_U50_DISP : 50|2@1+ (1,0) [0|3] ""  CCU
 SG_ ADAS34C_6_4_SLWF_OFS_OV50_DISP : 52|2@1+ (1,0) [0|3] ""  CCU
 SG_ ADAS34C_5_0_SLWF_DISP_CONT : 40|2@1+ (1,0) [0|3] ""  CCU
 SG_ ADAS34C_5_2_ISA_IACC_OFSET_DISP : 42|2@1+ (1,0) [0|3] ""  CCU
 SG_ ADAS34C_5_4_SLWF_OFSET_DISP : 44|2@1+ (1,0) [0|3] ""  CCU
 SG_ ADAS34C_5_6_SIGNSWITCH_SND_DISP : 46|2@1+ (1,0) [0|3] ""  CCU
 SG_ ADAS34C_4_0_LOADSIGN_DISP_CONT : 32|2@1+ (1,0) [0|3] ""  CCU
 SG_ ADAS34C_4_2_LOADSIGN_ADD_DISP : 34|2@1+ (1,0) [0|3] ""  CCU
 SG_ ADAS34C_4_4_ISA_IACC_ACCEPT_DISP : 36|2@1+ (1,0) [0|3] ""  CCU
 SG_ ADAS34C_4_6_ISA_IACC_ACCEPT_PTN : 38|2@1+ (1,0) [0|3] ""  CCU
 SG_ ADAS34C_3_0_EYE_VALID : 24|1@1+ (1,0) [0|1] ""  CCU
 SG_ ADAS34C_2_0_E2E_COUNTER : 16|8@1+ (1,0) [0|255] ""  CCU
 SG_ ADAS34C_0_0_E2E_CRC : 0|16@1+ (1,0) [0|65535] ""  CCU

BO_ 843 ADAS34B: 32 C_ECU_GW
 SG_ ADAS34B_31_0_CSTM_ACC_FUNC_CONT : 248|1@1+ (1,0) [0|1] ""  CCU
 SG_ ADAS34B_30_0_CSTM_ACC_CONT_SET : 240|2@1+ (1,0) [0|3] ""  CCU
 SG_ ADAS34B_30_2_CSTM_ACC_OVERTAKE : 242|1@1+ (1,0) [0|1] ""  CCU
 SG_ ADAS34B_30_3_CSTM_ACC_TARGET_OPT : 243|1@1+ (1,0) [0|1] ""  CCU
 SG_ ADAS34B_30_4_CSTM_ACC_STOP_CONT : 244|1@1+ (1,0) [0|1] ""  CCU
 SG_ ADAS34B_30_5_CSTM_ACC_SLOWDOWN : 245|1@1+ (1,0) [0|1] ""  CCU
 SG_ ADAS34B_30_6_CSTM_ACC_HIGHWAY : 246|1@1+ (1,0) [0|1] ""  CCU
 SG_ ADAS34B_30_7_CSTM_ACC_SYS : 247|1@1+ (1,0) [0|1] ""  CCU
 SG_ ADAS34B_28_0_ACC_TARGET_OPT_DISP : 224|2@1+ (1,0) [0|3] ""  CCU
 SG_ ADAS34B_28_2_ACC_STOP_DISP : 226|2@1+ (1,0) [0|3] ""  CCU
 SG_ ADAS34B_28_4_ACC_SLOWDOWN_DISP : 228|2@1+ (1,0) [0|3] ""  CCU
 SG_ ADAS34B_28_6_ACC_HIGHWAY_DISP : 230|2@1+ (1,0) [0|3] ""  CCU
 SG_ ADAS34B_27_0_ACC_DISP_CONT : 216|2@1+ (1,0) [0|3] ""  CCU
 SG_ ADAS34B_27_2_ACC_LEVEL_DISP_CONT : 218|2@1+ (1,0) [0|3] ""  CCU
 SG_ ADAS34B_27_4_ACC_OVERTAKE_DISP : 220|2@1+ (1,0) [0|3] ""  CCU
 SG_ ADAS34B_27_6_ACC_LEVEL_PTN_DISP : 222|2@1+ (1,0) [0|3] ""  CCU
 SG_ ADAS34B_25_0_CSTM_ACTIVE_LKS : 200|1@1+ (1,0) [0|1] ""  CCU
 SG_ ADAS34B_25_1_CSTM_A_LKS_AUTOPASS : 201|1@1+ (1,0) [0|1] ""  CCU
 SG_ ADAS34B_25_2_CSTM_A_LKS_NAVI : 202|1@1+ (1,0) [0|1] ""  CCU
 SG_ ADAS34B_25_3_CSTM_A_LKS_OFFSET : 203|1@1+ (1,0) [0|1] ""  CCU
 SG_ ADAS34B_25_4_CSTM_A_LKS_OPT_CONT : 204|1@1+ (1,0) [0|1] ""  CCU
 SG_ ADAS34B_23_0_A_LKS_OPTION_DISP : 184|2@1+ (1,0) [0|3] ""  CCU
 SG_ ADAS34B_23_2_A_LKS_AUTOPASS_DISP : 186|2@1+ (1,0) [0|3] ""  CCU
 SG_ ADAS34B_23_4_A_LKS_NAVI_DISP : 188|2@1+ (1,0) [0|3] ""  CCU
 SG_ ADAS34B_23_6_A_LKS_OFFSET_DISP : 190|2@1+ (1,0) [0|3] ""  CCU
 SG_ ADAS34B_22_0_ACTIVE_LKS_DISP : 176|2@1+ (1,0) [0|3] ""  CCU
 SG_ ADAS34B_21_0_CSTM_LDW_TMG_CNT : 168|1@1+ (1,0) [0|1] ""  CCU
 SG_ ADAS34B_21_1_CSTM_LDPTARGET_CONT : 169|1@1+ (1,0) [0|1] ""  CCU
 SG_ ADAS34B_21_2_ELK_ASSISTTYPE_CONT : 170|1@1+ (1,0) [0|1] ""  CCU
 SG_ ADAS34B_20_0_CSTM_ELK : 160|1@1+ (1,0) [0|1] ""  CCU
 SG_ ADAS34B_20_1_CSTM_ELK_SOUND : 161|1@1+ (1,0) [0|1] ""  CCU
 SG_ ADAS34B_20_2_CSTM_ELK_VIB : 162|1@1+ (1,0) [0|1] ""  CCU
 SG_ ADAS34B_20_3_CSTM_ELK_CTRL : 163|1@1+ (1,0) [0|1] ""  CCU
 SG_ ADAS34B_20_4_CSTM_LDW_TIMING : 164|2@1+ (1,0) [0|3] ""  CCU
 SG_ ADAS34B_20_6_LDW_SOUND_ON_OFF_SW : 166|1@1+ (1,0) [0|1] ""  CCU
 SG_ ADAS34B_20_7_CSTM_LD_ASSISTTYPE : 167|1@1+ (1,0) [0|1] ""  CCU
 SG_ ADAS34B_19_0_CSTM_LANE_DEPARTURE : 152|1@1+ (1,0) [0|1] ""  CCU
 SG_ ADAS34B_19_1_CSTM_LDW_SOUND : 153|1@1+ (1,0) [0|1] ""  CCU
 SG_ ADAS34B_19_2_CSTM_LDW_VIB : 154|1@1+ (1,0) [0|1] ""  CCU
 SG_ ADAS34B_19_3_CSTM_LDP : 155|1@1+ (1,0) [0|1] ""  CCU
 SG_ ADAS34B_19_4_LDP_TGT_SOLIDLINE : 156|1@1+ (1,0) [0|1] ""  CCU
 SG_ ADAS34B_19_5_LDP_TGT_DASHLINE : 157|1@1+ (1,0) [0|1] ""  CCU
 SG_ ADAS34B_19_6_LDP_TGT_SIDE_OBJ : 158|1@1+ (1,0) [0|1] ""  CCU
 SG_ ADAS34B_19_7_LDP_TGT_SIDE_VHCL : 159|1@1+ (1,0) [0|1] ""  CCU
 SG_ ADAS34B_17_0_ELK_ASSISTTYPE_DISP : 136|2@1+ (1,0) [0|3] ""  CCU
 SG_ ADAS34B_17_2_ELK_SOUND_DISP_CONT : 138|2@1+ (1,0) [0|3] ""  CCU
 SG_ ADAS34B_17_4_ELK_VIB_DISP_CONT : 140|2@1+ (1,0) [0|3] ""  CCU
 SG_ ADAS34B_17_6_ELK_CTRL_DISP_CONT : 142|2@1+ (1,0) [0|3] ""  CCU
 SG_ ADAS34B_16_0_LDW_TIMING_DISP : 128|2@1+ (1,0) [0|3] ""  CCU
 SG_ ADAS34B_16_2_LDW_TIMING_PTN : 130|3@1+ (1,0) [0|7] ""  CCU
 SG_ ADAS34B_16_6_LDW_TIMING_PTN_DISP : 134|2@1+ (1,0) [0|3] ""  CCU
 SG_ ADAS34B_15_0_TGT_SOLIDLINE_DISP : 120|2@1+ (1,0) [0|3] ""  CCU
 SG_ ADAS34B_15_2_TGT_DASHLINE_DISP : 122|2@1+ (1,0) [0|3] ""  CCU
 SG_ ADAS34B_15_4_TGT_SIDE_OBJ_DISP : 124|2@1+ (1,0) [0|3] ""  CCU
 SG_ ADAS34B_15_6_TGT_SIDE_VHCL_DISP : 126|2@1+ (1,0) [0|3] ""  CCU
 SG_ ADAS34B_14_0_LD_ASSISTTYPE_DISP : 112|2@1+ (1,0) [0|3] ""  CCU
 SG_ ADAS34B_14_2_LDW_SOUND_DISP_CONT : 114|2@1+ (1,0) [0|3] ""  CCU
 SG_ ADAS34B_14_4_LDW_VIB_DISP_CONT : 116|2@1+ (1,0) [0|3] ""  CCU
 SG_ ADAS34B_14_6_LDP_DISP_CONT : 118|2@1+ (1,0) [0|3] ""  CCU
 SG_ ADAS34B_13_0_LANE_DEPARTURE_DISP : 104|2@1+ (1,0) [0|3] ""  CCU
 SG_ ADAS34B_13_2_LDPTARGET_DISP_CONT : 106|2@1+ (1,0) [0|3] ""  CCU
 SG_ ADAS34B_13_4_LDW_SOUND_SW_DISP : 108|2@1+ (1,0) [0|3] ""  CCU
 SG_ ADAS34B_13_6_ELK_DISP_CONT : 110|2@1+ (1,0) [0|3] ""  CCU
 SG_ ADAS34B_11_0_CSTM_MIS_AT_BACK : 88|1@1+ (1,0) [0|1] ""  CCU
 SG_ ADAS34B_11_1_MIS_AT_BACK_SPD_LIM : 89|2@1+ (1,0) [0|3] ""  CCU
 SG_ ADAS34B_11_3_CSTM_FCW_TYPE_CONT : 91|1@1+ (1,0) [0|1] ""  CCU
 SG_ ADAS34B_11_4_FCTI_NOTICE_CONT : 92|1@1+ (1,0) [0|1] ""  CCU
 SG_ ADAS34B_11_5_CSTM_SAFTY_MOD_SENS : 93|1@1+ (1,0) [0|1] ""  CCU
 SG_ ADAS34B_11_6_MIS_AT_BACK_CONT : 94|1@1+ (1,0) [0|1] ""  CCU
 SG_ ADAS34B_10_0_CSTM_FCTI_CONT : 80|1@1+ (1,0) [0|1] ""  CCU
 SG_ ADAS34B_10_1_CSTM_FCTI_SOUND : 81|1@1+ (1,0) [0|1] ""  CCU
 SG_ ADAS34B_10_2_CSTM_FCTI_PULSE : 82|1@1+ (1,0) [0|1] ""  CCU
 SG_ ADAS34B_10_3_CSTM_SAFTY_MODE : 83|1@1+ (1,0) [0|1] ""  CCU
 SG_ ADAS34B_10_4_CSTM_SAFTY_MODE_LV : 84|2@1+ (1,0) [0|3] ""  CCU
 SG_ ADAS34B_10_6_CSTM_BRK_TIMING_CUR : 86|1@1+ (1,0) [0|1] ""  CCU
 SG_ ADAS34B_10_7_CSTM_FCW_CONT_CUR : 87|1@1+ (1,0) [0|1] ""  CCU
 SG_ ADAS34B_9_0_CSTM_P_CR : 72|1@1+ (1,0) [0|1] ""  CCU
 SG_ ADAS34B_9_1_FCW_SOUND_ON_OFF_SW : 73|1@1+ (1,0) [0|1] ""  CCU
 SG_ ADAS34B_9_2_CSTM_FCW_TIMING : 74|2@1+ (1,0) [0|3] ""  CCU
 SG_ ADAS34B_9_4_CSTM_FCW_TYPE_SOUND : 76|1@1+ (1,0) [0|1] ""  CCU
 SG_ ADAS34B_9_5_CSTM_FCW_TYPE_PULSE : 77|1@1+ (1,0) [0|1] ""  CCU
 SG_ ADAS34B_9_6_CSTM_BRAKE_TIMING : 78|2@1+ (1,0) [0|3] ""  CCU
 SG_ ADAS34B_8_0_SAFTY_MODE_SENS_DISP : 64|2@1+ (1,0) [0|3] ""  CCU
 SG_ ADAS34B_8_2_MIS_AT_BACK_PTN_DISP : 66|2@1+ (1,0) [0|3] ""  CCU
 SG_ ADAS34B_7_0_MIS_AT_BACK_DISP : 56|2@1+ (1,0) [0|3] ""  CCU
 SG_ ADAS34B_7_2_MIS_AT_BACK_LIM_DISP : 58|2@1+ (1,0) [0|3] ""  CCU
 SG_ ADAS34B_7_4_BRK_TIMING_PTN_DISP : 60|2@1+ (1,0) [0|3] ""  CCU
 SG_ ADAS34B_7_6_FCW_TIMING_PTN_DISP : 62|2@1+ (1,0) [0|3] ""  CCU
 SG_ ADAS34B_6_0_SAFTY_MODE_DISP_CONT : 48|2@1+ (1,0) [0|3] ""  CCU
 SG_ ADAS34B_6_2_SAFTY_MODE_LV_DISP : 50|2@1+ (1,0) [0|3] ""  CCU
 SG_ ADAS34B_6_4_SAFTY_MODE_LV_PTN : 52|3@1+ (1,0) [0|7] ""  CCU
 SG_ ADAS34B_5_0_FCTI_DISP_CONT : 40|2@1+ (1,0) [0|3] ""  CCU
 SG_ ADAS34B_5_2_FCTI_NOTICE_DISP : 42|2@1+ (1,0) [0|3] ""  CCU
 SG_ ADAS34B_5_4_FCTI_SOUND_DISP_CONT : 44|2@1+ (1,0) [0|3] ""  CCU
 SG_ ADAS34B_5_6_FCTI_PULSE_DISP_CONT : 46|2@1+ (1,0) [0|3] ""  CCU
 SG_ ADAS34B_4_0_FCW_TYPE_DISP_CONT : 32|2@1+ (1,0) [0|3] ""  CCU
 SG_ ADAS34B_4_2_FCW_TYPE_SOUND_DISP : 34|2@1+ (1,0) [0|3] ""  CCU
 SG_ ADAS34B_4_4_FCW_TYPE_PULSE_DISP : 36|2@1+ (1,0) [0|3] ""  CCU
 SG_ ADAS34B_4_6_FCW_SOUND_SW_DISP : 38|2@1+ (1,0) [0|3] ""  CCU
 SG_ ADAS34B_3_0_P_CR_DISP_CONT : 24|2@1+ (1,0) [0|3] ""  CCU
 SG_ ADAS34B_3_2_BRAKE_TIMING_DISP : 26|2@1+ (1,0) [0|3] ""  CCU
 SG_ ADAS34B_3_4_FCW_DISP_CONT : 28|2@1+ (1,0) [0|3] ""  CCU
 SG_ ADAS34B_3_6_FCW_TIMING_DISP_PTN : 30|2@1+ (1,0) [0|3] ""  CCU
 SG_ ADAS34B_2_0_E2E_COUNTER : 16|8@1+ (1,0) [0|255] ""  CCU
 SG_ ADAS34B_0_0_E2E_CRC : 0|16@1+ (1,0) [0|65535] ""  CCU

BO_ 841 ADAS349: 32 C_ECU_GW
 SG_ ADAS349_4_0_AAOS_AEB_STATE : 32|2@1+ (1,0) [0|4] ""  CCU
 SG_ ADAS349_3_0_CID_MRM_DISP : 24|4@1+ (1,0) [0|9] ""  CCU
 SG_ ADAS349_2_0_E2E_COUNTER : 16|8@1+ (1,0) [0|255] ""  CCU
 SG_ ADAS349_0_0_E2E_CRC : 0|16@1+ (1,0) [0|65535] ""  CCU

BO_ 1100 EVCC44C: 8 C_ECU_GW
 SG_ EVCC44C_2_0_E2E_COUNTER : 16|8@1+ (1,0) [0|255] ""  CCU
 SG_ EVCC44C_0_0_E2E_CRC : 0|16@1+ (1,0) [0|65535] ""  CCU

BO_ 1099 EVCC44B: 32 C_ECU_GW
 SG_ EVCC44B_27_0_EVSE_ID_7_EVCC : 216|32@1+ (1,0) [0|31] ""  CCU
 SG_ EVCC44B_23_0_EVSE_ID_6_EVCC : 184|32@1+ (1,0) [0|31] ""  CCU
 SG_ EVCC44B_19_0_EVSE_ID_5_EVCC : 152|32@1+ (1,0) [0|31] ""  CCU
 SG_ EVCC44B_15_0_EVSE_ID_4_EVCC : 120|32@1+ (1,0) [0|31] ""  CCU
 SG_ EVCC44B_11_0_EVSE_ID_3_EVCC : 88|32@1+ (1,0) [0|31] ""  CCU
 SG_ EVCC44B_7_0_EVSE_ID_2_EVCC : 56|32@1+ (1,0) [0|31] ""  CCU
 SG_ EVCC44B_3_0_EVSE_ID_1_EVCC : 24|32@1+ (1,0) [0|31] ""  CCU
 SG_ EVCC44B_2_0_E2E_COUNTER : 16|8@1+ (1,0) [0|255] ""  CCU
 SG_ EVCC44B_0_0_E2E_CRC : 0|16@1+ (1,0) [0|65535] ""  CCU

BO_ 1098 EVCC44A: 32 C_ECU_GW
 SG_ EVCC44A_3_0_PNC_CC_SAVE_RES_RSLT : 24|8@1+ (1,0) [0|5] "" Vector__XXX
 SG_ EVCC44A_2_0_E2E_COUNTER : 16|8@1+ (1,0) [0|255] ""  CCU
 SG_ EVCC44A_0_0_E2E_CRC : 0|16@1+ (1,0) [0|65535] ""  CCU

BO_ 1097 EVCC449: 8 C_ECU_GW
 SG_ EVCC449_2_0_E2E_COUNTER : 16|8@1+ (1,0) [0|255] ""  CCU
 SG_ EVCC449_0_0_E2E_CRC : 0|16@1+ (1,0) [0|65535] ""  CCU

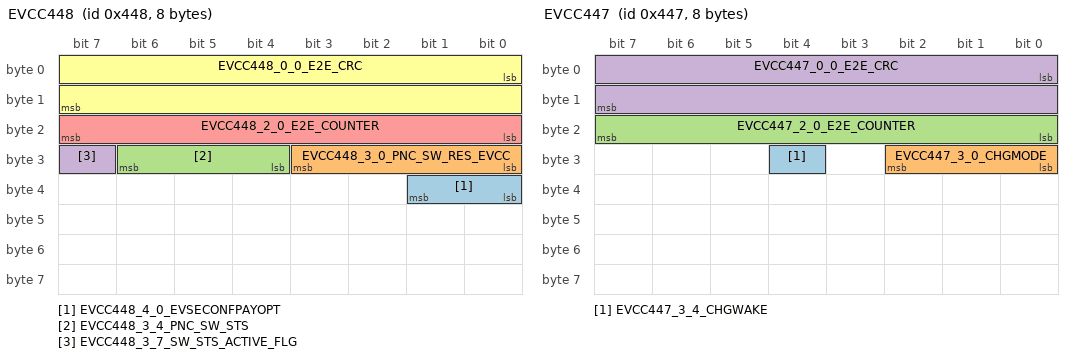
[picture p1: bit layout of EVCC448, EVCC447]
BO_ 1096 EVCC448: 8 C_ECU_GW
 SG_ EVCC448_4_0_EVSECONFPAYOPT : 32|2@1+ (1,0) [0|2] ""  DCM,CCU
 SG_ EVCC448_3_0_PNC_SW_RES_EVCC : 24|4@1+ (1,0) [0|8] ""  DCM,CCU
 SG_ EVCC448_3_4_PNC_SW_STS : 28|3@1+ (1,0) [0|7] ""  DCM,CCU
 SG_ EVCC448_3_7_SW_STS_ACTIVE_FLG : 31|1@1+ (1,0) [0|1] ""  DCM,CCU
 SG_ EVCC448_2_0_E2E_COUNTER : 16|8@1+ (1,0) [0|255] ""  DCM,CCU
 SG_ EVCC448_0_0_E2E_CRC : 0|16@1+ (1,0) [0|65535] ""  DCM,CCU

BO_ 1095 EVCC447: 8 C_ECU_GW
 SG_ EVCC447_3_4_CHGWAKE : 28|1@1+ (1,0) [0|1] "" Vector__XXX
 SG_ EVCC447_3_0_CHGMODE : 24|3@1+ (1,0) [0|7] ""  CCU
 SG_ EVCC447_2_0_E2E_COUNTER : 16|8@1+ (1,0) [0|255] ""  CCU
 SG_ EVCC447_0_0_E2E_CRC : 0|16@1+ (1,0) [0|65535] ""  CCU

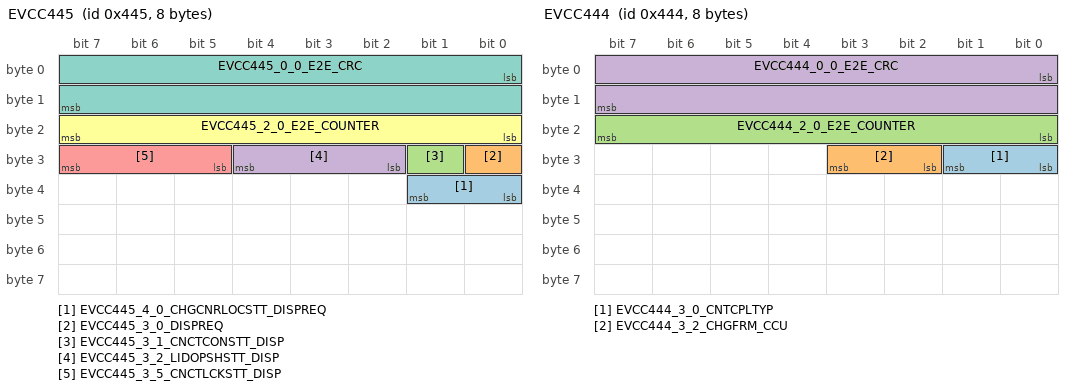
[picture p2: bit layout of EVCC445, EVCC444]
BO_ 1093 EVCC445: 8 C_ECU_GW
 SG_ EVCC445_4_0_CHGCNRLOCSTT_DISPREQ : 32|2@1+ (1,0) [0|2] ""  DCM,CCU
 SG_ EVCC445_3_0_DISPREQ : 24|1@1+ (1,0) [0|1] ""  DCM,CCU
 SG_ EVCC445_3_1_CNCTCONSTT_DISP : 25|1@1+ (1,0) [0|1] ""  DCM,CCU
 SG_ EVCC445_3_2_LIDOPSHSTT_DISP : 26|3@1+ (1,0) [0|2] ""  DCM,CCU
 SG_ EVCC445_3_5_CNCTLCKSTT_DISP : 29|3@1+ (1,0) [0|2] ""  DCM,CCU
 SG_ EVCC445_2_0_E2E_COUNTER : 16|8@1+ (1,0) [0|255] ""  DCM,CCU
 SG_ EVCC445_0_0_E2E_CRC : 0|16@1+ (1,0) [0|65535] ""  DCM,CCU

BO_ 1092 EVCC444: 8 C_ECU_GW
 SG_ EVCC444_3_0_CNTCPLTYP : 24|2@1+ (1,0) [0|1] ""  CCU
 SG_ EVCC444_3_2_CHGFRM_CCU : 26|2@1+ (1,0) [0|2] ""  CCU
 SG_ EVCC444_2_0_E2E_COUNTER : 16|8@1+ (1,0) [0|255] ""  CCU
 SG_ EVCC444_0_0_E2E_CRC : 0|16@1+ (1,0) [0|65535] ""  CCU

BO_ 1551 ENM60F: 32 C_ECU_GW
 SG_ ENM60F_26_0_ACCMHVPWR_LC : 208|17@1+ (1,0) [0|101060] "kWh"  CCU
 SG_ ENM60F_23_7_ACCMHVPWR_TRIPB : 191|17@1+ (1,0) [0|131060] "kWh"  CCU
 SG_ ENM60F_21_6_ACCMHVPWR_TRIPA : 174|17@1+ (1,0) [0|131060] "kWh"  CCU
 SG_ ENM60F_20_4_OTRACCMHVRATE_LC : 164|10@1+ (0.1,0) [0|100] "％"  CCU
 SG_ ENM60F_19_2_ACOUTACCMRATE_LC : 154|10@1+ (0.1,0) [0|100] "％"  CCU
 SG_ ENM60F_18_0_BADJACCMHVRATE_LC : 144|10@1+ (0.1,0) [0|100] "％"  CCU
 SG_ ENM60F_16_6_ACNACCMHVRATE_LC : 134|10@1+ (0.1,0) [0|100] "％"  CCU
 SG_ ENM60F_15_4_MOTACCMHVRATE_LC : 124|10@1+ (0.1,0) [0|100] "％"  CCU
 SG_ ENM60F_14_2_OTRACCMHVRATE_TRIPB : 114|10@1+ (0.1,0) [0|100] "％"  CCU
 SG_ ENM60F_13_0_ACOUTACCMRATE_TRIPB : 104|10@1+ (0.1,0) [0|100] "％"  CCU
 SG_ ENM60F_11_6_BADJACCMHVRATE_TRIPB : 94|10@1+ (0.1,0) [0|100] "％"  CCU
 SG_ ENM60F_10_4_ACNACCMHVRATE_TRIPB : 84|10@1+ (0.1,0) [0|100] "％"  CCU
 SG_ ENM60F_9_2_MOTACCMHVRATE_TRIPB : 74|10@1+ (0.1,0) [0|100] "％"  CCU
 SG_ ENM60F_8_0_OTRACCMHVRATE_TRIPA : 64|10@1+ (0.1,0) [0|100] "％"  CCU
 SG_ ENM60F_6_6_ACOUTACCMRATE_TRIPA : 54|10@1+ (0.1,0) [0|100] "％"  CCU
 SG_ ENM60F_5_4_BADJACCMHVRATE_TRIPA : 44|10@1+ (0.1,0) [0|100] "％"  CCU
 SG_ ENM60F_4_2_ACNACCMHVRATE_TRIPA : 34|10@1+ (0.1,0) [0|100] "％"  CCU
 SG_ ENM60F_3_0_MOTACCMHVRATE_TRIPA : 24|10@1+ (0.1,0) [0|100] "％"  CCU
 SG_ ENM60F_2_0_E2E_COUNTER : 16|8@1+ (1,0) [0|255] ""  CCU
 SG_ ENM60F_0_0_E2E_CRC : 0|16@1+ (1,0) [0|65535] ""  CCU

BO_ 1550 ENM60E: 32 C_ECU_GW
 SG_ ENM60E_28_0_DRNDISPREQ : 224|5@1+ (1,0) [0|31] ""  CCU
 SG_ ENM60E_27_0_INJDISPREQ : 216|5@1+ (1,0) [0|31] ""  CCU
 SG_ ENM60E_26_0_HVBTHMADJSTT : 208|1@1+ (1,0) [0|1] ""  CCU
 SG_ ENM60E_26_1_ACNOFFCMD : 209|2@1+ (1,0) [0|3] ""  CCU
 SG_ ENM60E_26_3_IJDRMDONOFF : 211|1@1+ (1,0) [0|1] ""  CCU
 SG_ ENM60E_26_4_ACNHVDDRVADM : 212|1@1+ (1,0) [0|1] "" Vector__XXX
 SG_ ENM60E_26_5_ACNINHSIG : 213|1@1+ (1,0) [0|1] "" Vector__XXX
 SG_ ENM60E_25_0_CNSPPWR_RATE : 200|8@1+ (1,0) [0|100] "%"  CCU
 SG_ ENM60E_24_0_V2LPWR_RATE : 192|8@1+ (1,0) [0|100] "%"  CCU
 SG_ ENM60E_23_0_HVBCNSPPWR_RATE : 184|8@1+ (1,0) [0|100] "%"  CCU
 SG_ ENM60E_22_0_ACNPWR_RATE : 176|8@1+ (1,0) [0|100] "%"  CCU
 SG_ ENM60E_21_0_DRVPWR_RATE : 168|8@1+ (1,0) [0|100] "%"  CCU
 SG_ ENM60E_20_0_AVECNSPPWR15 : 160|8@1+ (0.1,0) [0|25.5] "km/kWh"  CCU
 SG_ ENM60E_19_0_AVECNSPPWR14 : 152|8@1+ (0.1,0) [0|25.5] "km/kWh"  CCU
 SG_ ENM60E_18_0_AVECNSPPWR13 : 144|8@1+ (0.1,0) [0|25.5] "km/kWh"  CCU
 SG_ ENM60E_17_0_AVECNSPPWR12 : 136|8@1+ (0.1,0) [0|25.5] "km/kWh"  CCU
 SG_ ENM60E_16_0_AVECNSPPWR11 : 128|8@1+ (0.1,0) [0|25.5] "km/kWh"  CCU
 SG_ ENM60E_15_0_AVECNSPPWR10 : 120|8@1+ (0.1,0) [0|25.5] "km/kWh"  CCU
 SG_ ENM60E_14_0_AVECNSPPWR9 : 112|8@1+ (0.1,0) [0|25.5] "km/kWh"  CCU
 SG_ ENM60E_13_0_AVECNSPPWR8 : 104|8@1+ (0.1,0) [0|25.5] "km/kWh"  CCU
 SG_ ENM60E_12_0_AVECNSPPWR7 : 96|8@1+ (0.1,0) [0|25.5] "km/kWh"  CCU
 SG_ ENM60E_11_0_AVECNSPPWR6 : 88|8@1+ (0.1,0) [0|25.5] "km/kWh"  CCU
 SG_ ENM60E_10_0_AVECNSPPWR5 : 80|8@1+ (0.1,0) [0|25.5] "km/kWh"  CCU
 SG_ ENM60E_9_0_AVECNSPPWR4 : 72|8@1+ (0.1,0) [0|25.5] "km/kWh"  CCU
 SG_ ENM60E_8_0_AVECNSPPWR3 : 64|8@1+ (0.1,0) [0|25.5] "km/kWh"  CCU
 SG_ ENM60E_7_0_AVECNSPPWR2 : 56|8@1+ (0.1,0) [0|25.5] "km/kWh"  CCU
 SG_ ENM60E_6_0_AVECNSPPWR1 : 48|8@1+ (0.1,0) [0|25.5] "km/kWh"  CCU
 SG_ ENM60E_5_0_HVBAVETEMP : 40|8@1+ (0.5,-40) [-40|87.5] "℃"  CCU
 SG_ ENM60E_4_0_AUXCNSPPWR : 32|8@1+ (20,0) [0|5100] "W"  CCU
 SG_ ENM60E_3_0_ACNCNSPPWR : 24|8@1+ (100,0) [0|25500] "W"  CCU
 SG_ ENM60E_2_0_E2E_COUNTER : 16|8@1+ (1,0) [0|255] ""  CCU
 SG_ ENM60E_0_0_E2E_CRC : 0|16@1+ (1,0) [0|65535] ""  CCU

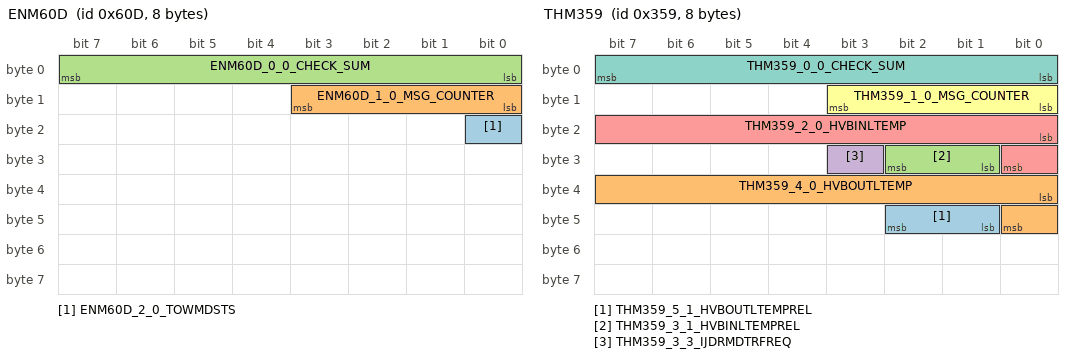
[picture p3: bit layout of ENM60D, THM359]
BO_ 1549 ENM60D: 8 C_ECU_GW
 SG_ ENM60D_2_0_TOWMDSTS : 16|1@1+ (1,0) [0|1] ""  CCU
 SG_ ENM60D_1_0_MSG_COUNTER : 8|4@1+ (1,0) [0|15] ""  CCU
 SG_ ENM60D_0_0_CHECK_SUM : 0|8@1+ (1,0) [0|255] ""  CCU

BO_ 1548 ENM60C: 32 C_ECU_GW
 SG_ ENM60C_27_2_VEHPWRTRIPLOG : 218|27@1+ (0.01,0) [0|999999.99] "kWh"  DCM
 SG_ ENM60C_26_0_HVBWIN : 208|10@1+ (1,0) [0|999] "kW"  CCU
 SG_ ENM60C_24_6_THMADJPRDWIN : 198|10@1+ (1,0) [0|100] "%"  CCU
 SG_ ENM60C_23_3_ACNOFF_DRVRANG : 187|11@1+ (1,0) [0|1999] "km"  DCM,CCU
 SG_ ENM60C_22_0_ACNON_DRVRANG : 176|11@1+ (1,0) [0|1999] "km"  DCM,CCU
 SG_ ENM60C_21_2_HVBTEMPSTT : 170|3@1+ (1,0) [0|7] ""  CCU
 SG_ ENM60C_20_4_OUTLMTDISREQ : 164|3@1+ (1,0) [0|7] ""  CCU
 SG_ ENM60C_20_7_CHGLMTDISREQ : 167|3@1+ (1,0) [0|7] ""  CCU
 SG_ ENM60C_19_1_VEHPWREFF_TRIPB : 153|11@1+ (0.1,0) [0|19.9] "km/kWh"  DCM
 SG_ ENM60C_17_6_VEHPWREFF_TRIPA : 142|11@1+ (0.1,0) [0|19.9] "km/kWh"  DCM
 SG_ ENM60C_16_3_VEHPWREFF_ODO : 131|11@1+ (0.1,0) [0|19.9] "km/kWh"  DCM
 SG_ ENM60C_15_0_VEHPWREFF : 120|11@1+ (0.1,0) [0|19.9] "km/kWh" Vector__XXX
 SG_ ENM60C_14_0_PRCNSTT : 112|2@1+ (1,0) [0|3] ""  CCU
 SG_ ENM60C_14_2_PRCNSTTFBK : 114|2@1+ (1,0) [0|3] ""  CCU
 SG_ ENM60C_14_4_ACNLMTDISREQ : 116|3@1+ (1,0) [0|7] ""  CCU
 SG_ ENM60C_13_0_STCTDISPREQ : 104|3@1+ (1,0) [0|7] ""  CCU
 SG_ ENM60C_13_3_VEHPRDDIS_JDG : 107|3@1+ (1,0) [0|7] ""  DCM,CCU
 SG_ ENM60C_13_6_PFOMDJDG : 110|2@1+ (1,0) [0|3] ""  CCU
 SG_ ENM60C_12_0_HVBTEMP : 96|8@1+ (0.5,-40) [-40|87.5] "℃"  CCU
 SG_ ENM60C_11_0_HVBTGTTEMP : 88|8@1+ (0.5,-40) [-40|87.5] "℃"  CCU
 SG_ ENM60C_10_0_PFOMDSTP : 80|3@1+ (1,0) [0|7] ""  CCU
 SG_ ENM60C_10_3_HVBTHMADJSTT : 83|3@1+ (1,0) [0|7] ""  CCU
 SG_ ENM60C_10_6_PFOMDCNTN : 86|1@1+ (1,0) [0|1] ""  CCU
 SG_ THM60C_10_7_PWRMDJDG : 87|1@1+ (1,0) [0|1] "" Vector__XXX
 SG_ ENM60C_9_0_ENHCHGTIM : 72|8@1+ (1,0) [0|240] "min"  CCU
 SG_ ENM60C_8_0_THMADJTIM_PRCNSW : 64|8@1+ (1,0) [0|240] "min"  CCU
 SG_ ENM60C_7_0_THMADJPRDSOC : 56|8@1+ (1,0) [0|100] "%"  CCU
 SG_ ENM60C_6_0_HVBTHMADJPWR : 48|8@1+ (0.1,0) [0|25] "kW"  CCU
 SG_ ENM60C_5_0_THMADJTIM_PFOMD : 40|8@1+ (1,0) [0|255] "min"  CCU
 SG_ ENM60C_4_0_HVBTHMADJTIM : 32|8@1+ (1,0) [0|240] "min"  CCU
 SG_ ENM60C_3_1_TRLSTSDISREQ : 25|2@1+ (1,0) [0|3] ""  CCU
 SG_ ENM60C_3_3_TOWMDFAILDISREQ : 27|1@1+ (1,0) [0|1] ""  CCU
 SG_ ENM60C_3_6_CHGTIPDISPREQ : 30|2@1+ (1,0) [0|3] ""  CCU
 SG_ ENM60C_2_0_E2E_COUNTER : 16|8@1+ (1,0) [0|255] ""  DCM,CCU
 SG_ ENM60C_0_0_E2E_CRC : 0|16@1+ (1,0) [0|65535] ""  DCM,CCU

BO_ 857 THM359: 8 C_ECU_GW
 SG_ THM359_5_1_HVBOUTLTEMPREL : 41|2@1+ (1,0) [0|3] "" Vector__XXX
 SG_ THM359_4_0_HVBOUTLTEMP : 32|9@1+ (0.5,-40) [-40|215.5] "℃"  CCU
 SG_ THM359_3_1_HVBINLTEMPREL : 25|2@1+ (1,0) [0|3] "" Vector__XXX
 SG_ THM359_3_3_IJDRMDTRFREQ : 27|1@1+ (1,0) [0|1] ""  CCU
 SG_ THM359_2_0_HVBINLTEMP : 16|9@1+ (0.5,-40) [-40|215.5] "℃" Vector__XXX
 SG_ THM359_1_0_MSG_COUNTER : 8|4@1+ (1,0) [0|15] "" Vector__XXX
 SG_ THM359_0_0_CHECK_SUM : 0|8@1+ (1,0) [0|255] "" Vector__XXX

BO_ 1485 CHR5CD: 32 C_ECU_GW
 SG_ CHR5CD_27_0_EVSE_ID_7_CHR : 216|32@1+ (1,0) [0|31] ""  CCU
 SG_ CHR5CD_23_0_EVSE_ID_6_CHR : 184|32@1+ (1,0) [0|31] ""  CCU
 SG_ CHR5CD_19_0_EVSE_ID_5_CHR : 152|32@1+ (1,0) [0|31] ""  CCU
 SG_ CHR5CD_15_0_EVSE_ID_4_CHR : 120|32@1+ (1,0) [0|31] ""  CCU
 SG_ CHR5CD_11_0_EVSE_ID_3_CHR : 88|32@1+ (1,0) [0|31] ""  CCU
 SG_ CHR5CD_7_0_EVSE_ID_2_CHR : 56|32@1+ (1,0) [0|31] ""  CCU
 SG_ CHR5CD_3_0_EVSE_ID_1_CHR : 24|32@1+ (1,0) [0|31] ""  CCU
 SG_ CHR5CD_2_0_E2E_COUNTER : 16|8@1+ (1,0) [0|255] ""  CCU
 SG_ CHR5CD_0_0_E2E_CRC : 0|16@1+ (1,0) [0|65535] ""  CCU

BO_ 1116 CHR45C: 32 C_ECU_GW
 SG_ CHR45C_29_0_BYTE21 : 232|8@1+ (1,0) [0|255] "" Vector__XXX
 SG_ CHR45C_28_0_BYTE20 : 224|8@1+ (1,0) [0|255] "" Vector__XXX
 SG_ CHR45C_27_0_BYTE19 : 216|8@1+ (1,0) [0|255] "" Vector__XXX
 SG_ CHR45C_26_0_BYTE18 : 208|8@1+ (1,0) [0|255] "" Vector__XXX
 SG_ CHR45C_25_0_BYTE17 : 200|8@1+ (1,0) [0|255] "" Vector__XXX
 SG_ CHR45C_24_0_BYTE16 : 192|8@1+ (1,0) [0|255] "" Vector__XXX
 SG_ CHR45C_23_0_BYTE15 : 184|8@1+ (1,0) [0|255] "" Vector__XXX
 SG_ CHR45C_22_0_BYTE14 : 176|8@1+ (1,0) [0|255] "" Vector__XXX
 SG_ CHR45C_21_0_BYTE13 : 168|8@1+ (1,0) [0|255] "" Vector__XXX
 SG_ CHR45C_20_0_BYTE12 : 160|8@1+ (1,0) [0|255] "" Vector__XXX
 SG_ CHR45C_19_0_BYTE11 : 152|8@1+ (1,0) [0|255] "" Vector__XXX
 SG_ CHR45C_18_0_BYTE10 : 144|8@1+ (1,0) [0|255] "" Vector__XXX
 SG_ CHR45C_17_0_BYTE9 : 136|8@1+ (1,0) [0|255] "" Vector__XXX
 SG_ CHR45C_16_0_BYTE8 : 128|8@1+ (1,0) [0|255] "" Vector__XXX
 SG_ CHR45C_15_0_BYTE7 : 120|8@1+ (1,0) [0|255] "" Vector__XXX
 SG_ CHR45C_14_0_BYTE6 : 112|8@1+ (1,0) [0|255] "" Vector__XXX
 SG_ CHR45C_13_0_BYTE5 : 104|8@1+ (1,0) [0|255] "" Vector__XXX
 SG_ CHR45C_12_0_BYTE4 : 96|8@1+ (1,0) [0|255] "" Vector__XXX
 SG_ CHR45C_11_0_BYTE3 : 88|8@1+ (1,0) [0|255] "" Vector__XXX
 SG_ CHR45C_10_0_BYTE2 : 80|8@1+ (1,0) [0|255] "" Vector__XXX
 SG_ CHR45C_9_0_LIDLOCK_DISC_DT : 72|2@1+ (1,0) [0|3] "" Vector__XXX
 SG_ CHR45C_9_2_LIDOP : 74|2@1+ (1,0) [0|3] "" Vector__XXX
 SG_ CHR45C_8_3_CHGSTARTSTOP : 67|4@1+ (1,0) [0|15] "" Vector__XXX
 SG_ CHR45C_8_2_LIDOP_BUZ_REQ : 66|1@1+ (1,0) [0|1] "" Vector__XXX
 SG_ CHR45C_8_1_LIDOP_WARDISP_REQ : 65|1@1+ (1,0) [0|1] ""  DCM
 SG_ CHR45C_8_0_CHG_CNRCNTSTT : 64|1@1+ (1,0) [0|1] "" Vector__XXX
 SG_ CHR45C_6_0_FEDPWR_DISP : 48|16@1+ (1,0) [0|65535] "kW" Vector__XXX
 SG_ CHR45C_4_0_CHGPWR_DISP : 32|16@1+ (1,0) [0|65535] "kW" Vector__XXX
 SG_ CHR45C_3_0_CHGFEDSTT : 24|8@1+ (1,0) [0|6] "" Vector__XXX
 SG_ CHR45C_2_0_E2E_COUNTER : 16|8@1+ (1,0) [0|255] ""  DCM
 SG_ CHR45C_0_0_E2E_CRC : 0|16@1+ (1,0) [0|65535] ""  DCM

BO_ 1111 CHR457: 32 C_ECU_GW
 SG_ CHR457_31_0_BYTE29 : 248|8@1+ (1,0) [0|255] ""  DCM
 SG_ CHR457_30_0_BYTE28 : 240|8@1+ (1,0) [0|255] ""  DCM
 SG_ CHR457_29_0_BYTE27 : 232|8@1+ (1,0) [0|255] ""  DCM
 SG_ CHR457_28_0_BYTE26 : 224|8@1+ (1,0) [0|255] ""  DCM
 SG_ CHR457_27_0_BYTE25 : 216|8@1+ (1,0) [0|255] ""  DCM
 SG_ CHR457_26_0_BYTE24 : 208|8@1+ (1,0) [0|255] ""  DCM
 SG_ CHR457_25_0_BYTE23 : 200|8@1+ (1,0) [0|255] ""  DCM
 SG_ CHR457_24_0_BYTE22 : 192|8@1+ (1,0) [0|255] ""  DCM
 SG_ CHR457_23_0_BYTE21 : 184|8@1+ (1,0) [0|255] ""  DCM
 SG_ CHR457_22_0_BYTE20 : 176|8@1+ (1,0) [0|255] ""  DCM
 SG_ CHR457_21_0_BYTE19 : 168|8@1+ (1,0) [0|255] ""  DCM
 SG_ CHR457_20_0_BYTE18 : 160|8@1+ (1,0) [0|255] ""  DCM
 SG_ CHR457_19_0_BYTE17 : 152|8@1+ (1,0) [0|255] ""  DCM
 SG_ CHR457_18_0_BYTE16 : 144|8@1+ (1,0) [0|255] ""  DCM
 SG_ CHR457_17_0_BYTE15 : 136|8@1+ (1,0) [0|255] ""  DCM
 SG_ CHR457_16_0_BYTE14 : 128|8@1+ (1,0) [0|255] ""  DCM
 SG_ CHR457_15_0_BYTE13 : 120|8@1+ (1,0) [0|255] ""  DCM
 SG_ CHR457_14_0_BYTE12 : 112|8@1+ (1,0) [0|255] ""  DCM
 SG_ CHR457_13_0_BYTE11 : 104|8@1+ (1,0) [0|255] ""  DCM
 SG_ CHR457_12_6_ENERGY_CHARGED_DISP : 102|16@1+ (1,0) [0|65535] "kWh"  CCU
 SG_ CHR457_11_7_DLTSOCCALC_FIN : 95|7@1+ (1,0) [0|127] "%"  CCU
 SG_ CHR457_11_0_DLTSOCCALC_STRT : 88|7@1+ (1,0) [0|127] "%"  CCU
 SG_ CHR457_10_6_STLMT_TYPE : 86|2@1+ (1,0) [0|2] ""  CCU
 SG_ CHR457_10_4_ACDC_INFO : 84|2@1+ (1,0) [0|2] ""  CCU
 SG_ CHR457_9_0_CHGTIM : 72|12@1+ (1,0) [0|63] "min"  CCU
 SG_ CHR457_8_0_BYTE6 : 64|8@1+ (1,0) [0|255] ""  DCM
 SG_ CHR457_7_0_BYTE5 : 56|8@1+ (1,0) [0|255] ""  DCM
 SG_ CHR457_6_4_DCPWRSUPSTOP_DISP : 52|4@1+ (1,0) [0|1] ""  DCM
 SG_ CHR457_6_0_DCPWRSUPSTRT_DISP : 48|4@1+ (1,0) [0|1] ""  DCM
 SG_ CHR457_5_0_CHGSTRTNTCE_DISP : 40|4@1+ (1,0) [0|1] ""  DCM
 SG_ CHR457_5_4_CHGENDNTCE_DISP : 44|4@1+ (1,0) [0|1] ""  DCM
 SG_ CHR457_4_0_FEDSTPRSN_DISP : 32|8@1+ (1,0) [0|255] ""  DCM,CCU
 SG_ CHR457_3_0_CHGSTPRSN_DISP : 24|8@1+ (1,0) [0|255] ""  DCM,CCU
 SG_ CHR457_2_0_E2E_COUNTER : 16|8@1+ (1,0) [0|255] ""  DCM
 SG_ CHR457_0_0_E2E_CRC : 0|16@1+ (1,0) [0|65535] ""  DCM

BO_ 1109 CHR455: 32 C_ECU_GW
 SG_ CHR455_31_3_CHGCNRLOCSTT_DISPREQ : 251|2@1+ (1,0) [0|2] ""  DCM,CCU
 SG_ CHR455_28_4_VEH_CHGPWRUPLMT : 228|17@1+ (1,0) [0|131071] "kW"  DCM,CCU
 SG_ CHR455_27_4_V2H_MODE : 220|8@1+ (1,0) [0|1] ""  DCM,CCU
 SG_ CHR455_26_4_DCPWRSUPSTT : 212|8@1+ (1,0) [0|255] ""  DCM,CCU
 SG_ CHR455_26_3_CHGMNTDISP_REQ : 211|1@1+ (1,0) [0|1] ""  CCU
 SG_ CHR455_26_2_MNTLIT_REQ : 210|1@1+ (1,0) [0|1] ""  CCU
 SG_ CHR455_25_0_CHGVLT_DISP : 200|10@1+ (1,0) [0|1023] "V"  DCM,CCU
 SG_ CHR455_23_0_CHGCUR_DISP : 184|16@1+ (1,0) [0|65535] "A"  DCM,CCU
 SG_ CHR455_22_1_CHGSTPCOMP : 177|1@1+ (1,0) [0|1] ""  CCU
 SG_ CHR455_20_1_ENERGY_CHARGED_DISP : 161|16@1+ (1,0) [0|65535] "kWh"  DCM,CCU
 SG_ CHR455_19_2_DLTSOCCALC_FIN : 154|7@1+ (1,0) [0|127] "%"  DCM,CCU
 SG_ CHR455_18_3_DLTSOCCALC_STRT : 147|7@1+ (1,0) [0|127] "%"  DCM,CCU
 SG_ CHR455_18_2_STLMT_TYPE : 146|1@1+ (1,0) [0|1] ""  DCM,CCU
 SG_ CHR455_18_1_ACDC_INFO : 145|1@1+ (1,0) [0|1] ""  DCM,CCU
 SG_ CHR455_16_6_EVSEOUTPWR : 134|10@1+ (1,0) [0|1023] "kW"  CCU
 SG_ CHR455_13_3_CHG_FINTIM : 107|27@1+ (1,0) [0|134217727] ""  CCU
 SG_ CHR455_12_0_CHGTIM : 96|12@1+ (1,0) [0|63] "min"  DCM,CCU
 SG_ CHR455_10_7_DCPWRSUP_PWR_DISP : 87|8@1+ (1,0) [0|255] "kW"  DCM,CCU
 SG_ CHR455_8_7_CHGPWR_DISP : 71|16@1+ (1,0) [0|65535] "kW"  CCU
 SG_ CHR455_7_1_DCPWRSUP_ADMTIM : 57|14@1+ (1,0) [0|16383] "min"  DCM,CCU
 SG_ CHR455_6_1_CHGSTT : 49|8@1+ (1,0) [0|255] ""  DCM,CCU
 SG_ CHR455_5_2_FED_LOLMT : 42|7@1+ (1,0) [0|100] "%"  CCU
 SG_ CHR455_4_6_DCCHG_PWRUPLMT : 38|4@1+ (1,0) [0|15] ""  DCM,CCU
 SG_ CHR455_4_2_ACCHG_CURUPLMT : 34|4@1+ (1,0) [0|15] ""  DCM,CCU
 SG_ CHR455_3_3_CHG_HILMT : 27|7@1+ (1,0) [0|127] "%"  DCM,CCU
 SG_ CHR455_3_1_CHG_CNRLOCSTT : 25|2@1+ (1,0) [0|3] ""  DCM,CCU
 SG_ CHR455_3_0_CHG_CNRCNTSTT : 24|1@1+ (1,0) [0|1] ""  DCM,CCU
 SG_ CHR455_2_0_E2E_COUNTER : 16|8@1+ (1,0) [0|255] ""  DCM,CCU
 SG_ CHR455_0_0_E2E_CRC : 0|16@1+ (1,0) [0|65535] ""  DCM,CCU

CM_ SG_ 552 RDR228_7_0_EYE_TIMEOUT_ERROR_FLG "後側方ﾚｰﾀﾞ ｱｲｻｲﾄﾃﾞｰﾀ未着・異常検知ﾌﾗｸﾞ
";
CM_ SG_ 552 RDR228_7_1_BLOCKAGE_FORMING_2 "ﾌﾞﾛｯｹｰｼﾞ2条件成立ﾌﾗｸﾞ
";
CM_ SG_ 552 RDR228_7_2_WARN_LCA_R_1ST "右側LCA警報1次ﾌﾗｸﾞ（注意喚起）
";
CM_ SG_ 552 RDR228_7_3_WARN_LCA_L_1ST "左側LCA警報1次ﾌﾗｸﾞ（注意喚起）
";
CM_ SG_ 552 RDR228_7_4_WARN_LCA_R_2ND "右側LCA警報2次ﾌﾗｸﾞ（ｳｨﾝｶｰON）
";
CM_ SG_ 552 RDR228_7_5_WARN_LCA_L_2ND "左側LCA警報2次ﾌﾗｸﾞ（ｳｨﾝｶｰON）
";
CM_ SG_ 552 RDR228_7_6_WARN_RCTA_R "右RCTA警報ﾌﾗｸﾞ
";
CM_ SG_ 552 RDR228_7_7_WARN_RCTA_L "左RCTA警報ﾌﾗｸﾞ
";
CM_ SG_ 552 RDR228_6_0_WARN_BSD_R_1ST "右側BSD警報ﾌﾗｸﾞ(注意喚起)
";
CM_ SG_ 552 RDR228_6_1_WARN_BSD_L_1ST "左側BSD警報ﾌﾗｸﾞ(注意喚起)
";
CM_ SG_ 552 RDR228_6_2_WARN_BSD_R_2ND "右側BSD警報2次ﾌﾗｸﾞ(ｳｨﾝｶｰON)
";
CM_ SG_ 552 RDR228_6_3_WARN_BSD_L_2ND "左側BSD警報2次ﾌﾗｸﾞ(ｳｨﾝｶｰON)
";
CM_ SG_ 552 RDR228_6_5_BLOCKAGE_STS "ﾌﾞﾛｯｹｰｼﾞｽﾃｰﾀｽ
";
CM_ SG_ 552 RDR228_5_0_BSD_R_E "右側BSDﾌﾗｸﾞ(EYE-ELK用)
";
CM_ SG_ 552 RDR228_5_1_BSD_L_E "左側BSDﾌﾗｸﾞ(EYE-ELK用)
";
CM_ SG_ 552 RDR228_5_2_LCA_R_E "右側LCAﾌﾗｸﾞ(EYE-ELK用)
";
CM_ SG_ 552 RDR228_5_3_LCA_L_E "左側LCAﾌﾗｸﾞ(EYE-ELK用)
";
CM_ SG_ 552 RDR228_5_4_BSD_R_A "右側BSDﾌﾗｸﾞ(EYE-AES用)
";
CM_ SG_ 552 RDR228_5_5_BSD_L_A "左側BSDﾌﾗｸﾞ(EYE-AES用)
";
CM_ SG_ 552 RDR228_5_6_LCA_R_A "右側LCAﾌﾗｸﾞ(EYE-AES用)
";
CM_ SG_ 552 RDR228_5_7_LCA_L_A "左側LCAﾌﾗｸﾞ(EYE-AES用)
";
CM_ SG_ 552 RDR228_4_0_DOW_ACTIVELAMP "DOW Active灯表示ﾌﾗｸﾞ
";
CM_ SG_ 552 RDR228_4_1_WARN_DOW_1ST_R "右側DOW警報1次ﾌﾗｸﾞ
";
CM_ SG_ 552 RDR228_4_2_WARN_DOW_1ST_L "左側DOW警報1次ﾌﾗｸﾞ
";
CM_ SG_ 552 RDR228_4_3_WARN_DOW_2ST_R "右側DOW警報2次ﾌﾗｸﾞ
";
CM_ SG_ 552 RDR228_4_4_WARN_DOW_2ST_L "左側DOW警報2次ﾌﾗｸﾞ
";
CM_ SG_ 552 RDR228_4_5_CSTM_STS_SRVD "ｶｽﾀﾏｲｽﾞ状態－BSD/LCA警報ON-OFF
";
CM_ SG_ 552 RDR228_4_6_CSTM_STS_BSD_LCA_2ND "ｶｽﾀﾏｲｽﾞ状態－BSD/LCA2次ﾌﾞｻﾞｰON-OFF
";
CM_ SG_ 552 RDR228_4_7_CSTM_STS_RCTA "ｶｽﾀﾏｲｽﾞ状態－RCTA　ON-OFF
";
CM_ SG_ 552 RDR228_3_0_WARN_BSD_LCA_R_2ND "右側BSD/LCA2次ﾌﾞｻﾞｰﾌﾗｸﾞ
";
CM_ SG_ 552 RDR228_3_1_WARN_BSD_LCA_L_2ND "左側BSD/LCA2次ﾌﾞｻﾞｰﾌﾗｸﾞ
";
CM_ SG_ 552 RDR228_3_2_CSTM_STS_DOW "ｶｽﾀﾏｲｽﾞ状態－DOW　ON-OFF
";
CM_ SG_ 552 RDR228_3_3_CSTM_STS_DOW_SFT_POS "ｶｽﾀﾏｲｽﾞ状態－DOW有効ｼﾌﾄﾎﾟｼﾞｼｮﾝ
";
CM_ SG_ 552 RDR228_3_5_CSTM_DSP_BSD_LCA "ｶｽﾀﾏｲｽﾞ表示有効－BSD/LCA警報
";
CM_ SG_ 552 RDR228_3_6_CSTM_DSP_BSD_LCA_2ND "ｶｽﾀﾏｲｽﾞ表示有効－BSD/LCA2次ﾌﾞｻﾞｰ
";
CM_ SG_ 552 RDR228_3_7_CSTM_DSP_RCTA "ｶｽﾀﾏｲｽﾞ表示有効－RCTA
";
CM_ SG_ 552 RDR228_2_0_CSTM_DSP_DOW "ｶｽﾀﾏｲｽﾞ表示有効－DOW
";
CM_ SG_ 552 RDR228_2_1_EYE_LOCAL_BUS1_FAIL "後側方ﾚｰﾀﾞ ｱｲｻｲﾄﾛｰｶﾙBUS1異常検知ﾌﾗｸﾞ
";
CM_ SG_ 552 RDR228_2_2_CSTM_DSP_DOW_SFT_POS "ｶｽﾀﾏｲｽﾞ表示有効－DOW有効ｼﾌﾄﾎﾟｼﾞｼｮﾝ
";
CM_ SG_ 552 RDR228_2_3_ELK_STOP_REQ_FLG "後側方ﾚｰﾀﾞELK停止要求ﾌﾗｸﾞ
";
CM_ SG_ 552 RDR228_2_4_FAIL_RDRSYS "後側方ﾚｰﾀﾞｼｽﾃﾑﾌｪｰﾙﾌﾗｸﾞ
";
CM_ SG_ 552 RDR228_2_5_STOP_RDRSYS "後側方ﾚｰﾀﾞｼｽﾃﾑ一時停止ﾌﾗｸﾞ
";
CM_ SG_ 552 RDR228_2_6_ON_OFF_RDRSYS "後側方ﾚｰﾀﾞｼｽﾃﾑON-OFFﾌﾗｸﾞ
";
CM_ SG_ 552 RDR228_2_7_BLOCKAGE_FORMING "ﾌﾞﾛｯｹｰｼﾞ条件成立ﾌﾗｸﾞ
";
CM_ SG_ 552 RDR228_1_0_MSG_COUNTER "ﾒｯｾｰｼﾞｶｳﾝﾀ
";
CM_ SG_ 552 RDR228_1_4_BATT_OFF_CAUSE "DOW電源OFF要求ﾌﾗｸﾞ
";
CM_ SG_ 552 RDR228_1_5_CSTM_GLO_1 "ｶｽﾀﾏｲｽﾞ表示ｸﾞﾚｰｱｳﾄ－1
";
CM_ SG_ 552 RDR228_1_6_CSTM_GLO_3 "ｶｽﾀﾏｲｽﾞ表示ｸﾞﾚｰｱｳﾄ－3
";
CM_ SG_ 552 RDR228_1_7_CSTM_GLO_2 "ｶｽﾀﾏｲｽﾞ表示ｸﾞﾚｰｱｳﾄ－2
";
CM_ SG_ 552 RDR228_0_0_CHECK_SUM "ﾁｪｯｸｻﾑ
";
CM_ SG_ 1606 EYE646_1_0_MSG_COUNTER "ﾒｯｾｰｼﾞｶｳﾝﾀ
";
CM_ SG_ 1606 EYE646_1_4_DEADMAN_NOTIFICATION "DN要求
";
CM_ SG_ 1606 EYE646_0_0_CHECK_SUM "ﾁｪｯｸｻﾑ
";
CM_ SG_ 965 EYE3C5_7_0_GSR_AEBS_FUNC_INFO "GSR-AEBS機能有無フラグ
";
CM_ SG_ 965 EYE3C5_7_1_CSTM_CRV_ADJUST "カスタマイズ現在値(カーブ前減速度調整機能)
";
CM_ SG_ 965 EYE3C5_7_3_BRAKE_HAPTIC_CURR "カスタマイズ現在値設定(ブレーキハプティック)
";
CM_ SG_ 965 EYE3C5_7_5_SAFETY_MODE_FUNC_INFO "障害物なし加速抑制機能有無フラグ
";
CM_ SG_ 965 EYE3C5_7_6_SAFETY_MODE_CURR "カスタマイズ現在値設定(障害物なし加速抑制)
";
CM_ SG_ 965 EYE3C5_7_7_GSR_DDAW_FUNC_INFO "GSR-DDAW機能有無フラグ
";
CM_ SG_ 965 EYE3C5_6_0_IND_SAFETY_MODE "アクセル急踏み加速抑制機能ON灯
";
CM_ SG_ 965 EYE3C5_6_1_ALC_ACTIVE_L "ALC制御中表示_左
";
CM_ SG_ 965 EYE3C5_6_2_FLASHING_IND_SAFETY "安全重視モード点滅表示指示
";
CM_ SG_ 965 EYE3C5_6_3_OVERTAKE_FUNC_INFO "追い抜き抑制制御有無フラグ
";
CM_ SG_ 965 EYE3C5_6_4_CRV_ADJUST_FUNC_INFO "カーブ前減速度調整機能有無フラグ
";
CM_ SG_ 965 EYE3C5_6_5_STRG_TOUCHSENSOR_WRNG "ステアリングタッチセンサ故障灯
";
CM_ SG_ 965 EYE3C5_6_6_ALC_ACTIVE_R "ALC制御中表示_右
";
CM_ SG_ 965 EYE3C5_6_7_CSTM_GSR_ISA "GSR-ISA有無フラグ
";
CM_ SG_ 965 EYE3C5_5_0_LANE_COLOR_R "隣レーン色_右
";
CM_ SG_ 965 EYE3C5_5_2_LINE_LANE_R "隣外側車線表示_右
";
CM_ SG_ 965 EYE3C5_5_4_LANE_COLOR_L "隣レーン色_左
";
CM_ SG_ 965 EYE3C5_5_6_LINE_LANE_L "隣外側車線表示_左
";
CM_ SG_ 965 EYE3C5_4_0_ROAD_SHAPE_CURVE "道路形状_湾曲
";
CM_ SG_ 965 EYE3C5_4_4_ROAD_SHAPE_DIRECTION "道路形状_方向
";
CM_ SG_ 965 EYE3C5_4_5_CSTM_GSR_ELKS "GSR-ELKS有無フラグ
";
CM_ SG_ 965 EYE3C5_4_6_MY_WAY_COLOR "自レーンの色
";
CM_ SG_ 965 EYE3C5_3_0_AD_DRV_ICON "高度運転支援アイコン
";
CM_ SG_ 965 EYE3C5_3_2_AUTO_HANDLE_ICON "AUTOハンドルアイコン
";
CM_ SG_ 965 EYE3C5_3_4_WITH_HANDS_ICON "ハンズオン/ハンズオフ表示
";
CM_ SG_ 965 EYE3C5_3_5_STRG_HAPTIC_WRNG "ステアリングハプティック故障灯
";
CM_ SG_ 965 EYE3C5_3_6_BRK_HPTC_FUNC_INFO "ブレーキハプティック機能有無フラグ
";
CM_ SG_ 965 EYE3C5_3_7_SPECIAL_DISP_INFO "特殊標識表示機能有無フラグ
";
CM_ SG_ 965 EYE3C5_2_0_SLOWDWN_CURVE_ICON "カーブ前減速アイコン
";
CM_ SG_ 965 EYE3C5_2_3_FLASHING_IND "自車点滅指示
";
CM_ SG_ 965 EYE3C5_2_4_ATTENTION_TOLLGATE "料金所注意アイコン
";
CM_ SG_ 965 EYE3C5_2_6_MAPLOCATOR_IND "ロケータインジケータ
";
CM_ SG_ 965 EYE3C5_1_0_MSG_COUNTER "ﾒｯｾｰｼﾞｶｳﾝﾀ
";
CM_ SG_ 965 EYE3C5_1_4_ISA_FAIL_IND "ISA故障灯
";
CM_ SG_ 965 EYE3C5_1_5_SLWF_OFF_IND "SLWFOFF灯
";
CM_ SG_ 965 EYE3C5_1_6_CSTM_SLWF_SET "カスタマイズ現在値(SLWF)
";
CM_ SG_ 965 EYE3C5_1_7_CSTM_TSR_SOUND_SET "カスタマイズ現在値(標識切り替わり警報音)
";
CM_ SG_ 965 EYE3C5_0_0_CHECK_SUM "ﾁｪｯｸｻﾑ
";
CM_ SG_ 964 EYE3C4_7_0_PCR_FAIL_OFF_IND "プリクラ故障/OFF灯指示
";
CM_ SG_ 964 EYE3C4_7_2_AES_FAIL_OFF_IND "AES故障/OFF灯指示
";
CM_ SG_ 964 EYE3C4_7_4_LDP_FAIL_OFF_IND "LDP故障/OFF灯指示
";
CM_ SG_ 964 EYE3C4_7_6_ELK_FAIL_OFF_IND "ELK故障/OFF灯指示
";
CM_ SG_ 964 EYE3C4_6_0_MCAM_SYS_FAIL_HALT "単眼故障状態通知(HALT/FAIL)
";
CM_ SG_ 964 EYE3C4_6_2_MCAM_FUNC_INFO "単眼機能有無フラグ
";
CM_ SG_ 964 EYE3C4_6_3_EYE_DRV_ACTION_REQ "アイサイトドライバアクション要求
";
CM_ SG_ 964 EYE3C4_6_6_LDW_SND_OFF_FAIL_IND "LDW音OFF灯/SW故障警告表示
";
CM_ SG_ 964 EYE3C4_5_0_EAM_GREEN "EAM点灯指示　緑
";
CM_ SG_ 964 EYE3C4_5_2_EAM_BLUE "EAM点灯指示　青
";
CM_ SG_ 964 EYE3C4_5_4_EAM_GREEN_2 "EAM点灯指示_緑2
";
CM_ SG_ 964 EYE3C4_5_6_FCW_SND_OFF_FAIL_IND "FCW音OFF灯/SW故障警告表示
";
CM_ SG_ 964 EYE3C4_4_0_EAM_YELLOW "EAM点灯指示　黄
";
CM_ SG_ 964 EYE3C4_4_4_EAM_RED "EAM点灯指示　赤
";
CM_ SG_ 964 EYE3C4_3_0_CODE_NO_BUZZER "警報コード（表示のみ）
";
CM_ SG_ 964 EYE3C4_2_0_CODE_WARN "警報コード（音有）
";
CM_ SG_ 964 EYE3C4_1_0_MSG_COUNTER "ﾒｯｾｰｼﾞｶｳﾝﾀ
";
CM_ SG_ 964 EYE3C4_1_5_SNR_DRV_ACTION_REQ "ソナードライバアクション要求
";
CM_ SG_ 964 EYE3C4_0_0_CHECK_SUM "ﾁｪｯｸｻﾑ
";
CM_ SG_ 805 EYE325_6_5_SONAR_DISP_INT "ｸﾘｿﾅ割り込み表示ﾌﾗｸﾞ
";
CM_ SG_ 805 EYE325_5_0_SONAR_R_L_CORNER_4LVL "リアソナー距離警報情報(左コーナー4段階)
";
CM_ SG_ 805 EYE325_5_3_SONAR_R_R_CORNER_4LVL "リアソナー距離警報情報(右コーナー4段階)
";
CM_ SG_ 805 EYE325_4_0_SONAR_R_CENTER "ﾘｱｿﾅｰ距離警報情報：Rcenter（中央4段階）
";
CM_ SG_ 805 EYE325_4_3_SONAR_LEVEL "RAB/ｸﾘｿﾅ警報音ﾚﾍﾞﾙ
";
CM_ SG_ 805 EYE325_4_6_RAB_WARNING "RAB警報割込み表示指示
";
CM_ SG_ 805 EYE325_3_0_SONAR_R_L_CORNER "ﾘｱｿﾅｰ距離警報情報：RLConner（左ｺｰﾅ3段階）
";
CM_ SG_ 805 EYE325_3_2_SONAR_R_R_CORNER "ﾘｱｿﾅｰ距離警報情報：RRConner（右ｺｰﾅ3段階）
";
CM_ SG_ 805 EYE325_3_4_SONAR_R_L_SIDE "ﾘｱｿﾅｰ距離警報情報：RLSide（左ｻｲﾄﾞ3段階：予約）
";
CM_ SG_ 805 EYE325_3_6_SONAR_R_R_SIDE "ﾘｱｿﾅｰ距離警報情報：RRSide（右ｻｲﾄﾞ3段階：予約）
";
CM_ SG_ 805 EYE325_2_0_RAB_OFF "RAB 機能OFF状態通知
";
CM_ SG_ 805 EYE325_2_1_SONAR_OFF "警報音機能OFF状態通知
";
CM_ SG_ 805 EYE325_2_2_SONAR_SYS_HALT "ｿﾅｰｼｽﾃﾑ一時停止状態通知 (Fault)
";
CM_ SG_ 805 EYE325_2_4_SONAR_SYS_FAIL "ｿﾅｰｼｽﾃﾑ故障状態通知 (Fail)
";
CM_ SG_ 805 EYE325_2_6_RAB_DISABLE "RAB機能一時OFF操作不可
";
CM_ SG_ 805 EYE325_2_7_SONAR_DISABLE "警報音一時OFF操作不可
";
CM_ SG_ 805 EYE325_1_0_MSG_COUNTER "ﾒｯｾｰｼﾞｶｳﾝﾀ
";
CM_ SG_ 805 EYE325_1_4_CSTM_RAB_SET "SNRｶｽﾀﾏｲｽﾞ現在値設定(RAB機能)
";
CM_ SG_ 805 EYE325_1_5_CSTM_CLR_SNR_SET "SNRｶｽﾀﾏｲｽﾞ現在値設定(ｸﾘｱﾗﾝｽｿﾅｰ機能)
";
CM_ SG_ 805 EYE325_1_6_RAB "RAB機能設定ﾌﾗｸﾞ
";
CM_ SG_ 805 EYE325_1_7_SONAR_NO_DISP "ｿﾅｰｼｽﾃﾑ画面非表示ﾌﾗｸﾞ
";
CM_ SG_ 805 EYE325_0_0_CHECK_SUM "ﾁｪｯｸｻﾑ
";
CM_ SG_ 803 EYE323_7_0_ISA_OFFSET_CURR "ISA制限車速オフセット値
";
CM_ SG_ 803 EYE323_7_5_SLIF_FUNC_INFO "標識認識機能有無情報
";
CM_ SG_ 803 EYE323_7_6_ISA_FUNC_INFO "ISA機能有無情報
";
CM_ SG_ 803 EYE323_7_7_ISA_CUSTOMIZE_CURR "ｱｲｻｲﾄｶｽﾀﾏｲｽﾞ現在設定値(ISA)
";
CM_ SG_ 803 EYE323_6_0_LDW_OFFSW_INFO "LDW音　OFFスイッチ有無
";
CM_ SG_ 803 EYE323_6_1_LDW_ON_OFF_SET "LDW音 ON/OFF現在設定値
";
CM_ SG_ 803 EYE323_6_2_CSTM_DDAW_WARN_SET "カスタマイズ現在値(DDAW警報)
";
CM_ SG_ 803 EYE323_6_3_IACC_FUNC_INFO "iACC機能有無フラグ
";
CM_ SG_ 803 EYE323_6_5_CSTM_LDW_TIMING_SET "LDWタイミングカスタマイズ現在設定値
";
CM_ SG_ 803 EYE323_6_6_CSTM_LDW_TIMING "LDWタイミングカスタマイズ有無
";
CM_ SG_ 803 EYE323_6_7_SLOWDOWNL_FUNC_INFO "カーブ前減速機能有無
";
CM_ SG_ 803 EYE323_5_0_CNG_GRN_CONT_CURR "カスタマイズ現在値（青信号切り替わりお知らせ）
";
CM_ SG_ 803 EYE323_5_1_TRAFFIC_FUNC_INFO "信号制御機能有無
";
CM_ SG_ 803 EYE323_5_2_FCW_OFFSW_INFO "FCW OFFスイッチ有無
";
CM_ SG_ 803 EYE323_5_3_FCW_ON_OFF_SET "FCW ON/OFF現在設定値
";
CM_ SG_ 803 EYE323_5_4_WARNING_SEL_CURR "カスタマイズ現在値（警報方法）
";
CM_ SG_ 803 EYE323_5_5_HAPT_FUNC_INFO "ステア振動（警報方法）機能有無
";
CM_ SG_ 803 EYE323_5_6_TOLLGATE_CONT_CURR "カスタマイズ現在値（料金所減速 ）
";
CM_ SG_ 803 EYE323_5_7_CURVE_CONT_CURR "カスタマイズ現在値（カーブ減速 ）
";
CM_ SG_ 803 EYE323_4_0_FCTB_ICON_L "FCTBお知らせアイコン_左
";
CM_ SG_ 803 EYE323_4_2_FCTB_ICON_R "FCTBお知らせアイコン_右
";
CM_ SG_ 803 EYE323_4_4_FCW_CONT_CURR "カスタマイズ現在値（FCW)
";
CM_ SG_ 803 EYE323_4_6_FCW_DISPLAY_SEL "FCWカスタマイズ項目表示指示
";
CM_ SG_ 803 EYE323_3_0_AES_FUNC_INFO "AES機能有無
";
CM_ SG_ 803 EYE323_3_1_CSTM_TSR_NO_ENTRY_SET "カスタマイズ現在値(進入禁止標識)
";
CM_ SG_ 803 EYE323_3_2_CSTM_TSR_STOP_SET "カスタマイズ現在値(一時停止標識)
";
CM_ SG_ 803 EYE323_3_3_CSTM_TSR_GIVE_WAY_SET "カスタマイズ現在値(前方優先道路標識)
";
CM_ SG_ 803 EYE323_3_4_WILDERNESS "Wilderness識別情報
";
CM_ SG_ 803 EYE323_3_5_AES_OFF "AES  OFFｲﾝｼﾞｹｰﾀ信号
";
CM_ SG_ 803 EYE323_3_6_FCTB_IND "FCTBインジケータ
";
CM_ SG_ 803 EYE323_2_0_CSTM_LDW_ALK_B "ｱｲｻｲﾄｶｽﾀﾏｲｽﾞ現在値設定（LDW/ALK-B）
";
CM_ SG_ 803 EYE323_2_2_CSTM_P_CR "ｱｲｻｲﾄｶｽﾀﾏｲｽﾞ現在値設定（P-CR）
";
CM_ SG_ 803 EYE323_2_3_SLOWDOWN_FUNC_INFO2 "料金所前減速機能有無
";
CM_ SG_ 803 EYE323_2_4_CID_CODE_WARN "CID警報ｺｰﾄﾞ
";
CM_ SG_ 803 EYE323_1_0_MSG_COUNTER "ﾒｯｾｰｼﾞｶｳﾝﾀ
";
CM_ SG_ 803 EYE323_1_4_DISP_FOLLOW_FORWARD "先行車追従表示フラグ
";
CM_ SG_ 803 EYE323_1_5_KEEP_LINE_SENTER_ACT "白線中央維持制御中フラグ
";
CM_ SG_ 803 EYE323_1_6_DDAW_FAIL_OFF "DDAW故障/OFF灯
";
CM_ SG_ 803 EYE323_0_0_CHECK_SUM "ﾁｪｯｸｻﾑ
";
CM_ SG_ 802 EYE322_7_0_CSTM_ACC_CONT_SET "ｱｲｻｲﾄｶｽﾀﾏｲｽﾞ現在値設定（ACC加速特性）
";
CM_ SG_ 802 EYE322_7_2_ELK_OFF_IND "ELK OFF灯表示
";
CM_ SG_ 802 EYE322_7_3_LIGHT_EAM_YELLOW "EAM(黄)点灯指示
";
CM_ SG_ 802 EYE322_7_5_BROKEN_LINE_L "車線表示切替_左
";
CM_ SG_ 802 EYE322_7_6_TJA_ACTIVE "TJA作動中フラグ
";
CM_ SG_ 802 EYE322_7_7_BROKEN_LINE_R "車線表示切替_右
";
CM_ SG_ 802 EYE322_6_0_CSTM_MIS_AT_START "ｱｲｻｲﾄｶｽﾀﾏｲｽﾞ現在設定値(AT誤後進抑制制御)
";
CM_ SG_ 802 EYE322_6_2_CSTM_ALK_TJA_SET "ｱｲｻｲﾄｶｽﾀﾏｲｽﾞ現在値設定(車線中央維持・TJA)
";
CM_ SG_ 802 EYE322_6_3_CSTM_LANE_SET "ｱｲｻｲﾄｶｽﾀﾏｲｽﾞ現在設定値（通行車線）
";
CM_ SG_ 802 EYE322_6_4_LDP_OFF_IND "LDP OFF灯表示
";
CM_ SG_ 802 EYE322_6_5_INDICATOR_MODE_L "左側ミラーインジケータ制御指示フラグ
";
CM_ SG_ 802 EYE322_6_7_CSTM_ELK_SET "ｱｲｻｲﾄｶｽﾀﾏｲｽﾞ現在設定値（ELK)
";
CM_ SG_ 802 EYE322_5_0_CSTM_MIS_AT_BACK "ｱｲｻｲﾄ機能有無情報(AT誤後進抑制制御)
";
CM_ SG_ 802 EYE322_5_1_CSTM_ALK_TJA "ｱｲｻｲﾄ機能有無情報(車線中央維持・TJA)
";
CM_ SG_ 802 EYE322_5_2_CSTM_SAS "ｱｲｻｲﾄ機能有無情報(SAS)
";
CM_ SG_ 802 EYE322_5_3_CSTM_HBA "ｱｲｻｲﾄ機能有無情報(HBA)
";
CM_ SG_ 802 EYE322_5_4_CSTM_ACC_CONT "ｱｲｻｲﾄ機能有無情報(ACC加速特性)
";
CM_ SG_ 802 EYE322_5_5_CSTM_LANE "ｱｲｻｲﾄ機能有無情報（通行車線）
";
CM_ SG_ 802 EYE322_5_6_LDW_SOUND_OFF_IND "LDW音 OFF灯表示
";
CM_ SG_ 802 EYE322_5_7_CSTM_ELK_SET "ｱｲｻｲﾄ機能有無情報（ELK）
";
CM_ SG_ 802 EYE322_4_0_CODE_WARN "警報ｺｰﾄﾞ（音有り）
";
CM_ SG_ 802 EYE322_4_5_CSTM_GSR "GSR対応有無フラグ
";
CM_ SG_ 802 EYE322_3_0_LANE_L "車線左表示
";
CM_ SG_ 802 EYE322_3_2_LANE_R "車線右表示
";
CM_ SG_ 802 EYE322_3_4_LANE_L_COLOR "車線左色
";
CM_ SG_ 802 EYE322_3_6_LANE_R_COLOR "車線右色
";
CM_ SG_ 802 EYE322_2_0_FCW_OFF_IND "FCW OFF灯表示
";
CM_ SG_ 802 EYE322_2_1_MOV_EYESIGHT_SCREEN "ｱｲｻｲﾄ画面移行ﾌﾗｸﾞ(ID322)
";
CM_ SG_ 802 EYE322_2_2_ALK_ICON "ALK表示
";
CM_ SG_ 802 EYE322_2_4_INDICATOR_CTRL_REQ "ミラーインジケータ制御フラグ
";
CM_ SG_ 802 EYE322_2_5_INDICATOR_MODE_R "右側ミラーインジケータ制御指示フラグ
";
CM_ SG_ 802 EYE322_2_7_LIMITER_BACK_SPEED "後退速度ﾘﾐｯﾀｰ設定値表示
";
CM_ SG_ 802 EYE322_1_0_MSG_COUNTER "ﾒｯｾｰｼﾞｶｳﾝﾀ
";
CM_ SG_ 802 EYE322_1_4_CODE_NO_BUZZER "警報ｺｰﾄﾞ（表示のみ）
";
CM_ SG_ 802 EYE322_1_7_DISTWARN_DMS "車間距離警報早鳴りﾌﾗｸﾞ
";
CM_ SG_ 802 EYE322_0_0_CHECK_SUM "ﾁｪｯｸｻﾑ
";
CM_ SG_ 801 EYE321_7_0_INFO_DIST_FORWARD "先行車距離
";
CM_ SG_ 801 EYE321_7_4_INFO_KEEP_STOP "停止保持中(HOLD)表示
";
CM_ SG_ 801 EYE321_7_5_INFO_READY "READY表示
";
CM_ SG_ 801 EYE321_7_6_INFO_SET_CC "ｸﾙｺﾝSET表示
";
CM_ SG_ 801 EYE321_7_7_INFO_OFF "OFF表示
";
CM_ SG_ 801 EYE321_6_0_FAIL_EYESIGHT "ｱｲｻｲﾄﾌｪｰﾙﾌﾗｸﾞ
";
CM_ SG_ 801 EYE321_6_1_MOV_EYESIGHT_SCREEN "ｱｲｻｲﾄ画面移行ﾌﾗｸﾞ(ID321)
";
CM_ SG_ 801 EYE321_6_2_IND_VEHICLE "自車表示
";
CM_ SG_ 801 EYE321_6_3_BRAKELAMP_VEHICLE "自車ﾌﾞﾚｰｷﾗﾝﾌﾟ点灯状態
";
CM_ SG_ 801 EYE321_6_4_IND_FORWARD_VECL "先行車表示
";
CM_ SG_ 801 EYE321_6_5_BRAKELAMP_FORWARD "先行車ﾌﾞﾚｰｷﾗﾝﾌﾟ点灯状態
";
CM_ SG_ 801 EYE321_6_6_CC_OR_LIM_SON "ｸﾙｺﾝ・ﾘﾐｯﾀｾｯﾄ状態
";
CM_ SG_ 801 EYE321_6_7_TEMP_OFF_STATE "一括一時OFF状態
";
CM_ SG_ 801 EYE321_5_0_INFO_SET_SPD "ｾｯﾄ車速表示
";
CM_ SG_ 801 EYE321_4_0_ACC_MODE "ACC/CC/SASﾓｰﾄﾞﾌﾗｸﾞ
";
CM_ SG_ 801 EYE321_4_2_SRVD_LASTMEM_ST_REQ "SRVDラストメモリ起動要求フラグ
";
CM_ SG_ 801 EYE321_4_3_INFO_MAIN_CC "ｸﾙｺﾝﾒｲﾝ表示
";
CM_ SG_ 801 EYE321_4_5_TRAFFIC_LIGHT "信号表示
";
CM_ SG_ 801 EYE321_3_0_CODE_HALT "ＨＡＬＴｺｰﾄﾞ
";
CM_ SG_ 801 EYE321_3_3_ELK_EQUIP "ELK機能有無
";
CM_ SG_ 801 EYE321_3_4_SET_DIST "車間距離設定表示
";
CM_ SG_ 801 EYE321_3_7_TJA "TJA機能有無
";
CM_ SG_ 801 EYE321_2_0_ACC_CANCEL_OR_CSTM "ｸﾙｺﾝｷｬﾝｾﾙ理由表示
";
CM_ SG_ 801 EYE321_2_4_ALK_CANCEL_OR_CSTM "ALKｷｬﾝｾﾙ理由表示
";
CM_ SG_ 801 EYE321_2_7_ALK_CANCEL_DISP_TYPE "ALKｷｬﾝｾﾙ表示種別
";
CM_ SG_ 801 EYE321_1_0_MSG_COUNTER "ﾒｯｾｰｼﾞｶｳﾝﾀ
";
CM_ SG_ 801 EYE321_1_4_PRECRASH_BRAKE_OFF "ﾌﾟﾘｸﾗｯｼｭﾌﾞﾚｰｷOFFｲﾝｼﾞｹｰﾀON flg
";
CM_ SG_ 801 EYE321_1_5_LANE_DEPARTURE_OFF "車線逸脱警報OFFｲﾝｼﾞｹｰﾀON flg
";
CM_ SG_ 801 EYE321_1_6_MET_AD_DRV_ASS "MET用高度運転支援有無ﾌﾗｸﾞ
";
CM_ SG_ 801 EYE321_1_7_ALC_EQUIP "ALC機能有無フラグ
";
CM_ SG_ 801 EYE321_0_0_CHECK_SUM "ﾁｪｯｸｻﾑ
";
CM_ SG_ 1746 LCT6D2_5_0_HDMAP_RELEASE_SEASON "3D高精度地図データリリース時期_季節
";
CM_ SG_ 1746 LCT6D2_5_4_HDMAP_RELEASE_REV "3D高精度地図データ改訂番号
";
CM_ SG_ 1746 LCT6D2_4_0_HDMAP_RELEASE_YEAR "3D高精度地図データリリース時期_西暦
";
CM_ SG_ 1746 LCT6D2_3_0_ISAMAP_RELEASE_SEASON "ISA地図データリリース時期（季節）
";
CM_ SG_ 1746 LCT6D2_3_4_ISAMAP_RELEASE_REV "ISA地図データリリース改定番号
";
CM_ SG_ 1746 LCT6D2_2_0_ISAMAP_RELEASE_YEAR "ISA地図データリリース時期（西暦）
";
CM_ SG_ 1746 LCT6D2_1_0_MSG_COUNTER "ﾒｯｾｰｼﾞｶｳﾝﾀ
";
CM_ SG_ 1746 LCT6D2_1_5_ADASMAP_FLAG "ADAS地図装備対象判定フラグ
";
CM_ SG_ 1746 LCT6D2_1_6_HDMAP_FLAG "3D高精度地図装備対象判定フラグ
";
CM_ SG_ 1746 LCT6D2_1_7_GSRISA_FLAG "GSRISA適用対象判定フラグ
";
CM_ SG_ 1746 LCT6D2_0_0_CHECK_SUM "ﾁｪｯｸｻﾑ
";
CM_ SG_ 845 ADAS34D_16_0_CSTM_SNR_DSPREEQ "カスタマイズ表示要求(クリソナON/OFF)
";
CM_ SG_ 845 ADAS34D_16_2_CSTM_RAB_DSPREQ "カスタマイズ表示要求(RAB ON/OFF)
";
CM_ SG_ 845 ADAS34D_16_4_CSTM_PED_DSPREQ "カスタマイズ表示要求(歩行者RAB ON/OFF)
";
CM_ SG_ 845 ADAS34D_16_6_CSTM_PEDTIM_DSPREQ "カスタマイズ表示要求(歩行者RABタイミング)
";
CM_ SG_ 845 ADAS34D_15_0_CSTM_SNR_CLEAR "SNRｶｽﾀﾏｲｽﾞ現在値設定(ｸﾘｱﾗﾝｽｿﾅｰ機能)
";
CM_ SG_ 845 ADAS34D_15_1_CSTM_RAB "SNRｶｽﾀﾏｲｽﾞ現在値設定(RAB機能)
";
CM_ SG_ 845 ADAS34D_15_2_CSTM_RAB_PED "SNRｶｽﾀﾏｲｽﾞ現在値設定(歩行者RAB機能)
";
CM_ SG_ 845 ADAS34D_15_3_CSTM_RAB_PED_TIMING "SNRｶｽﾀﾏｲｽﾞ現在値設定(歩行者RABタイミング)
";
CM_ SG_ 845 ADAS34D_15_5_CSTM_TEMP_OFF "ｶｽﾀﾏｲｽﾞ現在設定値(一括一時OFF)
";
CM_ SG_ 845 ADAS34D_15_7_TEMP_OFF_STATE "一括一時OFF状態
";
CM_ SG_ 845 ADAS34D_14_0_RAB_WARNING "割り込み表示要求
";
CM_ SG_ 845 ADAS34D_14_3_SONAR_LEVEL "警報音指示
";
CM_ SG_ 845 ADAS34D_13_0_PED_WARN_CENTER "歩行者お知らせ中央表示
";
CM_ SG_ 845 ADAS34D_13_1_PED_WARN_LEFT "歩行者お知らせ左表示
";
CM_ SG_ 845 ADAS34D_13_2_PED_WARN_RIGHT "歩行者お知らせ右表示
";
CM_ SG_ 845 ADAS34D_13_3_RAB_TRIG_TYPE "RAB作動トリガ種類
";
CM_ SG_ 845 ADAS34D_9_0_SONAR_R_R_CORNER_4LV "リアソナー距離警報情報(右コーナー4段階)
";
CM_ SG_ 845 ADAS34D_8_0_SONAR_DISP_INT "クリソナ割り込み表示要求
";
CM_ SG_ 845 ADAS34D_8_1_SONAR_R_CENTER "ﾘｱｿﾅｰ距離警報情報：Rcenter（中央4段階）
";
CM_ SG_ 845 ADAS34D_8_4_SONAR_R_L_CORNER_4LV "リアソナー距離警報情報(左コーナー4段階)
";
CM_ SG_ 845 ADAS34D_7_0_SONAR_SYS_FAIL "ｿﾅｰｼｽﾃﾑ故障状態通知 (FAIL)
";
CM_ SG_ 845 ADAS34D_7_2_RAB_HALT "RAB一時停止状態通知 (HALT)
";
CM_ SG_ 845 ADAS34D_7_4_CAMERA_FAIL "ｶﾒﾗｼｽﾃﾑ故障状態通知(FAIL)
";
CM_ SG_ 845 ADAS34D_7_6_RAB_PED_HALT "歩行者RAB一時停止状態通知(HALT)
";
CM_ SG_ 845 ADAS34D_6_0_REQ_ACT_EPB "EPB作動要求
";
CM_ SG_ 845 ADAS34D_6_1_STOP_HOJI_BUZ_ACT "停止保持解除音フラグ
";
CM_ SG_ 845 ADAS34D_6_2_RAB_OFF "RAB OFF灯　点灯要求
";
CM_ SG_ 845 ADAS34D_6_3_SONAR_OFF "警報音機能OFF灯 点灯要求
";
CM_ SG_ 845 ADAS34D_6_4_RAB_PED_OFF "歩行者RAB OFF灯 点灯要求
";
CM_ SG_ 845 ADAS34D_6_5_SONAR_HALT "警報音一時停止状態通知(HALT)
";
CM_ SG_ 845 ADAS34D_5_0_YOATSU_ACT "ﾌﾞﾚｰｷ予圧ﾌﾗｸﾞ
";
CM_ SG_ 845 ADAS34D_5_1_TORQUE_LIM_ACT "加速抑制実施フラグ
";
CM_ SG_ 845 ADAS34D_5_2_TORQUE_LIM_VAL "加速抑制値
";
CM_ SG_ 845 ADAS34D_4_0_RAB_ACT "RAB実施フラグ
";
CM_ SG_ 845 ADAS34D_4_1_RAB_VAL "減速度制動指示
";
CM_ SG_ 845 ADAS34D_3_0_RAB "RAB機能有無
";
CM_ SG_ 845 ADAS34D_3_1_RAB_PED "歩行者RAB機能有無
";
CM_ SG_ 845 ADAS34D_2_0_E2E_COUNTER "E2Eｶｳﾝﾀ
";
CM_ SG_ 845 ADAS34D_0_0_E2E_CRC "CRC
";
CM_ SG_ 844 ADAS34C_25_0_CSTM_ADDON_DISP_CNT "EYEカスタマイズ現在値（その他項目）
";
CM_ SG_ 844 ADAS34C_25_1_CSTM_LANE_SET_CONT "EYEカスタマイズ現在値（通行区分設定-制御）
";
CM_ SG_ 844 ADAS34C_24_0_CSTM_LSW "EYEカスタマイズ現在値（ふらつき警報）
";
CM_ SG_ 844 ADAS34C_24_1_CSTM_GREEN_LIGHT "EYEカスタマイズ現在値（青信号お知らせ）
";
CM_ SG_ 844 ADAS34C_24_2_CSTM_LANE_SET "EYEカスタマイズ現在値（通行区分設定）
";
CM_ SG_ 844 ADAS34C_24_3_CSTM_PROPOSAL_HMI "EYEカスタマイズ現在値（アイサイト使用提案）
";
CM_ SG_ 844 ADAS34C_24_4_CSTM_V2N "EYEカスタマイズ現在値（V2N）
";
CM_ SG_ 844 ADAS34C_24_5_CSTM_DATA_COLLECT "EYEカスタマイズ現在値（データ収集・解析）
";
CM_ SG_ 844 ADAS34C_24_6_CSTM_COLLECT_IMAGE "EYEカスタマイズ現在値（データ収集・解析(画像データ)）
";
CM_ SG_ 844 ADAS34C_24_7_CSTM_COLLECT_LOC "EYEカスタマイズ現在値（データ収集・解析(位置データ)）
";
CM_ SG_ 844 ADAS34C_22_0_DATA_COLLECT_DISP "EYEカスタマイズ表示制御信号（データ収集・解析）
";
CM_ SG_ 844 ADAS34C_22_2_COLLECT_IMAGE_DISP "EYEカスタマイズ表示制御信号（データ収集・解析(画像データ)）
";
CM_ SG_ 844 ADAS34C_22_4_COLLECT_LOC_DISP "EYEカスタマイズ表示制御信号（データ収集・解析(位置データ)）
";
CM_ SG_ 844 ADAS34C_21_0_LSW_DISP_CONT "EYEカスタマイズ表示制御信号（ふらつき警報）
";
CM_ SG_ 844 ADAS34C_21_2_GREEN_LIGHT_DISP "EYEカスタマイズ表示制御信号（青信号お知らせ）
";
CM_ SG_ 844 ADAS34C_21_4_LANE_SET_DISP_CONT "EYEカスタマイズ表示制御信号（通行区分設定-制御）
";
CM_ SG_ 844 ADAS34C_21_6_PROPOSAL_HMI_DISP "EYEカスタマイズ表示制御信号（アイサイト使用提案）
";
CM_ SG_ 844 ADAS34C_20_0_ADD_ON_DISP_CONT "EYEカスタマイズ表示制御信号（その他項目）
";
CM_ SG_ 844 ADAS34C_20_2_V2N_DISP_CONT "EYEカスタマイズ表示制御信号（V2N）
";
CM_ SG_ 844 ADAS34C_20_4_LANE_SET_PTN_DISP "EYEカスタマイズ表示制御信号（通行区分設定）
";
CM_ SG_ 844 ADAS34C_18_0_CSTM_SUPPRESS_SPEED "EYEカスタマイズ現在値（抑制/減速制御-感度-制御）
";
CM_ SG_ 844 ADAS34C_18_1_SUPPRESS_SPD_LEVEL "EYEカスタマイズ現在値（抑制/減速制御-感度）
";
CM_ SG_ 844 ADAS34C_18_3_ACTIVE_AVOIDANCE "EYEカスタマイズ現在値（先読み操舵減速アシスト-制御）
";
CM_ SG_ 844 ADAS34C_18_4_ACTIVE_AVOIDANCE_LV "EYEカスタマイズ現在値（先読み操舵減速アシスト）
";
CM_ SG_ 844 ADAS34C_17_0_CSTM_PDA_CURR "EYEカスタマイズ現在値（安全重視モード）
";
CM_ SG_ 844 ADAS34C_17_1_TARGET_VEHICLE "EYEカスタマイズ現在値（抑制/減速制御-ターゲット(車両)）
";
CM_ SG_ 844 ADAS34C_17_2_TARGET_SURROUNDING "EYEカスタマイズ現在値（抑制/減速制御-ターゲット(周辺環境)）
";
CM_ SG_ 844 ADAS34C_17_3_TARGET_SLOPE_DOWN "EYEカスタマイズ現在値（抑制/減速制御-ターゲット(下り坂)）
";
CM_ SG_ 844 ADAS34C_17_4_CUS_SUPPRESS_SPDTGT "EYEカスタマイズ現在値（抑制/減速制御-ターゲット-制御）
";
CM_ SG_ 844 ADAS34C_15_0_A_AVOIDANCE_DISP "EYEカスタマイズ表示制御信号（先読み操舵減速アシスト-制御）
";
CM_ SG_ 844 ADAS34C_15_2_A_AVOIDANCE_LV_DISP "EYEカスタマイズ表示制御信号（先読み操舵減速アシスト）
";
CM_ SG_ 844 ADAS34C_15_4_A_AVOIDANCE_LV_PTN "EYEカスタマイズパターン指示信号（先読み操舵減速アシスト）
";
CM_ SG_ 844 ADAS34C_14_0_SUPPRESS_SPDTGT_DSP "EYEカスタマイズ表示制御信号（抑制/減速制御-ターゲット-制御）
";
CM_ SG_ 844 ADAS34C_14_2_TARGET_VEHICLE_DISP "EYEカスタマイズ表示制御信号（抑制/減速制御-ターゲット(車両)）
";
CM_ SG_ 844 ADAS34C_14_4_TARGET_SURROUND_DSP "EYEカスタマイズ表示制御信号（抑制/減速制御-ターゲット(周辺環境)）
";
CM_ SG_ 844 ADAS34C_14_6_TGT_SLOPE_DOWN_DSP "EYEカスタマイズ表示制御信号（抑制/減速制御-ターゲット(下り坂)）
";
CM_ SG_ 844 ADAS34C_13_0_PDA_DISP_CONT "EYEカスタマイズ表示制御信号（安全重視モード）
";
CM_ SG_ 844 ADAS34C_13_2_SUPPRESS_SPD_DISP "EYEカスタマイズ表示制御信号（抑制/減速制御-感度-制御）
";
CM_ SG_ 844 ADAS34C_13_4_SUPPRESS_SPDLV_DISP "EYEカスタマイズ表示制御信号（抑制/減速制御-感度）
";
CM_ SG_ 844 ADAS34C_13_6_SUPPRESS_SPD_LV_PTN "EYEカスタマイズパターン指示信号（抑制/減速制御-感度）
";
CM_ SG_ 844 ADAS34C_11_0_ISA_OFS_U50_DISP "EYEカスタマイズ表示制御信号（標識連動オフセット値～50 km）
";
CM_ SG_ 844 ADAS34C_11_2_ISA_OFS_OV50_DISP "EYEカスタマイズ表示制御信号（標識連動オフセット値50 km～）
";
CM_ SG_ 844 ADAS34C_10_0_SLWF_OFFSET_OV50 "EYEカスタマイズ現在値（SLWFオフセット値50 km～）
";
CM_ SG_ 844 ADAS34C_9_0_SLWF_OFFSET_U50 "EYEカスタマイズ現在値（SLWFオフセット値～50 km）
";
CM_ SG_ 844 ADAS34C_9_5_CSTM_SLWF "EYEカスタマイズ現在値（SLWF-制御）
";
CM_ SG_ 844 ADAS34C_9_6_CSTM_SLWF_OFS_CONT "EYEカスタマイズ現在値（SLWFオフセット値-制御）
";
CM_ SG_ 844 ADAS34C_9_7_ISA_IACC_OFS_CONT "EYEカスタマイズ現在値（標識連動オフセット値-制御）
";
CM_ SG_ 844 ADAS34C_8_0_ISA_IACC_OFFSET_OV50 "EYEカスタマイズ現在値（標識連動オフセット値50 km～）
";
CM_ SG_ 844 ADAS34C_8_5_SIGN_SWITCH_SOUND "EYEカスタマイズ現在値（標識切替え音-制御）
";
CM_ SG_ 844 ADAS34C_8_6_CSTM_LOADSIGNS_SYS "EYEカスタマイズ現在値（標識関連機能）
";
CM_ SG_ 844 ADAS34C_8_7_CSTM_ISA_IACC_CONT "EYEカスタマイズ現在値（標識連動-制御）
";
CM_ SG_ 844 ADAS34C_7_0_ISA_IACC_OFFSET_U50 "EYEカスタマイズ現在値（標識連動オフセット値～50 km）
";
CM_ SG_ 844 ADAS34C_7_5_CSTM_LOADSIGNS_ADD "EYEカスタマイズ現在値（標識表示お知らせ-制御）
";
CM_ SG_ 844 ADAS34C_7_6_CSTM_ISA_IACC_ACCEPT "EYEカスタマイズ現在値（標識連動）
";
CM_ SG_ 844 ADAS34C_6_0_ISA_IACC_PTN_DISP "EYEカスタマイズ表示制御信号（標識連動）
";
CM_ SG_ 844 ADAS34C_6_2_SLWF_OFS_U50_DISP "EYEカスタマイズ表示制御信号（SLWFオフセット値～50 km）
";
CM_ SG_ 844 ADAS34C_6_4_SLWF_OFS_OV50_DISP "EYEカスタマイズ表示制御信号（SLWFオフセット値50 km～）
";
CM_ SG_ 844 ADAS34C_5_0_SLWF_DISP_CONT "EYEカスタマイズ表示制御信号（SLWF-制御）
";
CM_ SG_ 844 ADAS34C_5_2_ISA_IACC_OFSET_DISP "EYEカスタマイズ表示制御信号（標識連動オフセット値-制御）
";
CM_ SG_ 844 ADAS34C_5_4_SLWF_OFSET_DISP "EYEカスタマイズ表示制御信号（SLWFオフセット値-制御）
";
CM_ SG_ 844 ADAS34C_5_6_SIGNSWITCH_SND_DISP "EYEカスタマイズ表示制御信号（標識切替え音-制御）
";
CM_ SG_ 844 ADAS34C_4_0_LOADSIGN_DISP_CONT "EYEカスタマイズ表示制御信号（標識関連機能）
";
CM_ SG_ 844 ADAS34C_4_2_LOADSIGN_ADD_DISP "EYEカスタマイズ表示制御信号（標識表示お知らせ-制御）
";
CM_ SG_ 844 ADAS34C_4_4_ISA_IACC_ACCEPT_DISP "EYEカスタマイズ表示制御信号（標識連動-制御）
";
CM_ SG_ 844 ADAS34C_4_6_ISA_IACC_ACCEPT_PTN "EYEカスタマイズパターン指示信号（標識連動）
";
CM_ SG_ 844 ADAS34C_3_0_EYE_VALID "EYEカスタマイズValidフラグ
";
CM_ SG_ 844 ADAS34C_2_0_E2E_COUNTER "E2Eｶｳﾝﾀ
";
CM_ SG_ 844 ADAS34C_0_0_E2E_CRC "CRC
";
CM_ SG_ 843 ADAS34B_31_0_CSTM_ACC_FUNC_CONT "EYEカスタマイズ現在値（ACC加速特性-制御）
";
CM_ SG_ 843 ADAS34B_30_0_CSTM_ACC_CONT_SET "EYEカスタマイズ現在値（ACC加速特性）
";
CM_ SG_ 843 ADAS34B_30_2_CSTM_ACC_OVERTAKE "EYEカスタマイズ現在値（追い越し抑制-制御）
";
CM_ SG_ 843 ADAS34B_30_3_CSTM_ACC_TARGET_OPT "EYEカスタマイズ現在値（ACC-ターゲット-制御）
";
CM_ SG_ 843 ADAS34B_30_4_CSTM_ACC_STOP_CONT "EYEカスタマイズ現在値（ACC-ターゲット(停止制御)）
";
CM_ SG_ 843 ADAS34B_30_5_CSTM_ACC_SLOWDOWN "EYEカスタマイズ現在値（ACC-ターゲット(減速制御)）
";
CM_ SG_ 843 ADAS34B_30_6_CSTM_ACC_HIGHWAY "EYEカスタマイズ現在値（ACC-ターゲット(高速道路)）
";
CM_ SG_ 843 ADAS34B_30_7_CSTM_ACC_SYS "EYEカスタマイズ現在値（クルーズコントロールシステム)
";
CM_ SG_ 843 ADAS34B_28_0_ACC_TARGET_OPT_DISP "EYEカスタマイズ表示制御信号（ACC-ターゲット-制御）
";
CM_ SG_ 843 ADAS34B_28_2_ACC_STOP_DISP "EYEカスタマイズ表示制御信号（ACC-ターゲット(停止制御)）
";
CM_ SG_ 843 ADAS34B_28_4_ACC_SLOWDOWN_DISP "EYEカスタマイズ表示制御信号（ACC-ターゲット(減速制御)）
";
CM_ SG_ 843 ADAS34B_28_6_ACC_HIGHWAY_DISP "EYEカスタマイズ表示制御信号（ACC-ターゲット(高速道路)）
";
CM_ SG_ 843 ADAS34B_27_0_ACC_DISP_CONT "EYEカスタマイズ表示制御信号（クルーズコントロールシステム）
";
CM_ SG_ 843 ADAS34B_27_2_ACC_LEVEL_DISP_CONT "EYEカスタマイズ表示制御信号（ACC加速特性-制御）
";
CM_ SG_ 843 ADAS34B_27_4_ACC_OVERTAKE_DISP "EYEカスタマイズ表示制御信号（追い越し抑制-制御）
";
CM_ SG_ 843 ADAS34B_27_6_ACC_LEVEL_PTN_DISP "EYEカスタマイズ表示制御信号（ACC加速特性）
";
CM_ SG_ 843 ADAS34B_25_0_CSTM_ACTIVE_LKS "EYEカスタマイズ現在値（車線中央維持）
";
CM_ SG_ 843 ADAS34B_25_1_CSTM_A_LKS_AUTOPASS "EYEカスタマイズ現在値（LKS-付加機能(自動追い越し)）
";
CM_ SG_ 843 ADAS34B_25_2_CSTM_A_LKS_NAVI "EYEカスタマイズ現在値（LKS-付加機能(ナビルート連携)）
";
CM_ SG_ 843 ADAS34B_25_3_CSTM_A_LKS_OFFSET "EYEカスタマイズ現在値（LKS-付加機能(走行位置オフセット)）
";
CM_ SG_ 843 ADAS34B_25_4_CSTM_A_LKS_OPT_CONT "EYEカスタマイズ現在値（LKS-付加機能-制御）
";
CM_ SG_ 843 ADAS34B_23_0_A_LKS_OPTION_DISP "EYEカスタマイズ表示制御信号（LKS-付加機能-制御）
";
CM_ SG_ 843 ADAS34B_23_2_A_LKS_AUTOPASS_DISP "EYEカスタマイズ表示制御信号（LKS-付加機能(自動追い越し)）
";
CM_ SG_ 843 ADAS34B_23_4_A_LKS_NAVI_DISP "EYEカスタマイズ表示制御信号（LKS-付加機能(ナビルート連携)）
";
CM_ SG_ 843 ADAS34B_23_6_A_LKS_OFFSET_DISP "EYEカスタマイズ表示制御信号（LKS-付加機能(走行位置オフセット)）
";
CM_ SG_ 843 ADAS34B_22_0_ACTIVE_LKS_DISP "EYEカスタマイズ表示制御信号（車線中央維持）
";
CM_ SG_ 843 ADAS34B_21_0_CSTM_LDW_TMG_CNT "EYEカスタマイズ現在値（LD-警報タイミング-制御）
";
CM_ SG_ 843 ADAS34B_21_1_CSTM_LDPTARGET_CONT "EYEカスタマイズ現在値（LD-制御対象-制御）
";
CM_ SG_ 843 ADAS34B_21_2_ELK_ASSISTTYPE_CONT "EYEカスタマイズ現在値（ELK-アシストタイプ-制御）
";
CM_ SG_ 843 ADAS34B_20_0_CSTM_ELK "EYEカスタマイズ現在値（ELK）
";
CM_ SG_ 843 ADAS34B_20_1_CSTM_ELK_SOUND "EYEカスタマイズ現在値（ELK-アシストタイプ(音)）
";
CM_ SG_ 843 ADAS34B_20_2_CSTM_ELK_VIB "EYEカスタマイズ現在値（ELK-アシストタイプ(振動)）
";
CM_ SG_ 843 ADAS34B_20_3_CSTM_ELK_CTRL "EYEカスタマイズ現在値（ELK-アシストタイプ(制御)）
";
CM_ SG_ 843 ADAS34B_20_4_CSTM_LDW_TIMING "EYEカスタマイズ現在値（LD-警報タイミング）
";
CM_ SG_ 843 ADAS34B_20_6_LDW_SOUND_ON_OFF_SW "EYEカスタマイズ現在値（LDW音OFF）
";
CM_ SG_ 843 ADAS34B_20_7_CSTM_LD_ASSISTTYPE "EYEカスタマイズ現在値（LD-アシストタイプ-制御）
";
CM_ SG_ 843 ADAS34B_19_0_CSTM_LANE_DEPARTURE "EYEカスタマイズ現在値（車線逸脱抑制機能）
";
CM_ SG_ 843 ADAS34B_19_1_CSTM_LDW_SOUND "EYEカスタマイズ現在値（LD-アシストタイプ(音)）
";
CM_ SG_ 843 ADAS34B_19_2_CSTM_LDW_VIB "EYEカスタマイズ現在値（LD-アシストタイプ(振動)）
";
CM_ SG_ 843 ADAS34B_19_3_CSTM_LDP "EYEカスタマイズ現在値（LD-アシストタイプ(制御)）
";
CM_ SG_ 843 ADAS34B_19_4_LDP_TGT_SOLIDLINE "EYEカスタマイズ現在値（LD-制御対象(実線)）
";
CM_ SG_ 843 ADAS34B_19_5_LDP_TGT_DASHLINE "EYEカスタマイズ現在値（LD-制御対象(破線)）
";
CM_ SG_ 843 ADAS34B_19_6_LDP_TGT_SIDE_OBJ "EYEカスタマイズ現在値（LD-制御対象(側方構造物)）
";
CM_ SG_ 843 ADAS34B_19_7_LDP_TGT_SIDE_VHCL "EYEカスタマイズ現在値（LD-制御対象(側方車両)）
";
CM_ SG_ 843 ADAS34B_17_0_ELK_ASSISTTYPE_DISP "EYEカスタマイズ表示制御信号（ELK-アシストタイプ-制御）
";
CM_ SG_ 843 ADAS34B_17_2_ELK_SOUND_DISP_CONT "EYEカスタマイズ表示制御信号（ELK-アシストタイプ(音)）
";
CM_ SG_ 843 ADAS34B_17_4_ELK_VIB_DISP_CONT "EYEカスタマイズ表示制御信号（ELK-アシストタイプ(振動)）
";
CM_ SG_ 843 ADAS34B_17_6_ELK_CTRL_DISP_CONT "EYEカスタマイズ表示制御信号（ELK-アシストタイプ(制御)）
";
CM_ SG_ 843 ADAS34B_16_0_LDW_TIMING_DISP "EYEカスタマイズ表示制御信号（LD-警報タイミング-制御）
";
CM_ SG_ 843 ADAS34B_16_2_LDW_TIMING_PTN "EYEカスタマイズパターン指示信号（LD-警報タイミング）
";
CM_ SG_ 843 ADAS34B_16_6_LDW_TIMING_PTN_DISP "EYEカスタマイズ表示制御信号（LD-警報タイミング）
";
CM_ SG_ 843 ADAS34B_15_0_TGT_SOLIDLINE_DISP "EYEカスタマイズ表示制御信号（LD-制御対象(実線)）
";
CM_ SG_ 843 ADAS34B_15_2_TGT_DASHLINE_DISP "EYEカスタマイズ表示制御信号（LD-制御対象(破線)）
";
CM_ SG_ 843 ADAS34B_15_4_TGT_SIDE_OBJ_DISP "EYEカスタマイズ表示制御信号（LD-制御対象(側方構造物)）
";
CM_ SG_ 843 ADAS34B_15_6_TGT_SIDE_VHCL_DISP "EYEカスタマイズ表示制御信号（LD-制御対象(側方車両)）
";
CM_ SG_ 843 ADAS34B_14_0_LD_ASSISTTYPE_DISP "EYEカスタマイズ表示制御信号（LD-アシストタイプ-制御）
";
CM_ SG_ 843 ADAS34B_14_2_LDW_SOUND_DISP_CONT "EYEカスタマイズ表示制御信号（LD-アシストタイプ(音)）
";
CM_ SG_ 843 ADAS34B_14_4_LDW_VIB_DISP_CONT "EYEカスタマイズ表示制御信号（LD-アシストタイプ(振動)）
";
CM_ SG_ 843 ADAS34B_14_6_LDP_DISP_CONT "EYEカスタマイズ表示制御信号（LD-アシストタイプ(制御)）
";
CM_ SG_ 843 ADAS34B_13_0_LANE_DEPARTURE_DISP "EYEカスタマイズ表示制御信号（車線逸脱抑制機能）
";
CM_ SG_ 843 ADAS34B_13_2_LDPTARGET_DISP_CONT "EYEカスタマイズ表示制御信号（LD-制御対象-制御）
";
CM_ SG_ 843 ADAS34B_13_4_LDW_SOUND_SW_DISP "EYEカスタマイズ表示制御信号（LDW音OFF）
";
CM_ SG_ 843 ADAS34B_13_6_ELK_DISP_CONT "EYEカスタマイズ表示制御信号（ELK）
";
CM_ SG_ 843 ADAS34B_11_0_CSTM_MIS_AT_BACK "EYEカスタマイズ現在値（後退速リミッター）
";
CM_ SG_ 843 ADAS34B_11_1_MIS_AT_BACK_SPD_LIM "EYEカスタマイズ現在値（リミット速度）
";
CM_ SG_ 843 ADAS34B_11_3_CSTM_FCW_TYPE_CONT "EYEカスタマイズ現在値（FCW警報方法-制御）
";
CM_ SG_ 843 ADAS34B_11_4_FCTI_NOTICE_CONT "EYEカスタマイズ現在値（前側方警戒アシスト通知方法-制御）
";
CM_ SG_ 843 ADAS34B_11_5_CSTM_SAFTY_MOD_SENS "EYEカスタマイズ現在値（踏み間違い加速抑制-感度-制御）
";
CM_ SG_ 843 ADAS34B_11_6_MIS_AT_BACK_CONT "EYEカスタマイズ現在値（リミット速度-制御）
";
CM_ SG_ 843 ADAS34B_10_0_CSTM_FCTI_CONT "EYEカスタマイズ現在値（前側方警戒アシスト）
";
CM_ SG_ 843 ADAS34B_10_1_CSTM_FCTI_SOUND "EYEカスタマイズ現在値（前側方警戒アシスト通知方法(音)）
";
CM_ SG_ 843 ADAS34B_10_2_CSTM_FCTI_PULSE "EYEカスタマイズ現在値（前側方警戒アシスト通知方法(振動)）
";
CM_ SG_ 843 ADAS34B_10_3_CSTM_SAFTY_MODE "EYEカスタマイズ現在値（踏み間違い加速抑制）
";
CM_ SG_ 843 ADAS34B_10_4_CSTM_SAFTY_MODE_LV "EYEカスタマイズ現在値（踏み間違い加速抑制-感度）
";
CM_ SG_ 843 ADAS34B_10_6_CSTM_BRK_TIMING_CUR "EYEカスタマイズ現在値（ブレーキタイミング-制御）
";
CM_ SG_ 843 ADAS34B_10_7_CSTM_FCW_CONT_CUR "EYEカスタマイズ現在値（FCW警報タイミング-制御）
";
CM_ SG_ 843 ADAS34B_9_0_CSTM_P_CR "EYEカスタマイズ現在値（プリクラッシュブレーキ）
";
CM_ SG_ 843 ADAS34B_9_1_FCW_SOUND_ON_OFF_SW "EYEカスタマイズ現在値（FCW音OFF）
";
CM_ SG_ 843 ADAS34B_9_2_CSTM_FCW_TIMING "EYEカスタマイズ現在値（FCW警報タイミング）
";
CM_ SG_ 843 ADAS34B_9_4_CSTM_FCW_TYPE_SOUND "EYEカスタマイズ現在値（FCW警報方法(音)）
";
CM_ SG_ 843 ADAS34B_9_5_CSTM_FCW_TYPE_PULSE "EYEカスタマイズ現在値（FCW警報方法(振動)）
";
CM_ SG_ 843 ADAS34B_9_6_CSTM_BRAKE_TIMING "EYEカスタマイズ現在値（ブレーキタイミング）
";
CM_ SG_ 843 ADAS34B_8_0_SAFTY_MODE_SENS_DISP "EYEカスタマイズ表示制御信号（踏み間違い加速抑制-感度-制御）
";
CM_ SG_ 843 ADAS34B_8_2_MIS_AT_BACK_PTN_DISP "EYEカスタマイズ表示制御信号（リミット速度）
";
CM_ SG_ 843 ADAS34B_7_0_MIS_AT_BACK_DISP "EYEカスタマイズ表示制御信号（後退速度リミッター）
";
CM_ SG_ 843 ADAS34B_7_2_MIS_AT_BACK_LIM_DISP "EYEカスタマイズ表示制御信号（リミット速度-制御）
";
CM_ SG_ 843 ADAS34B_7_4_BRK_TIMING_PTN_DISP "EYEカスタマイズ表示制御信号（ブレーキタイミング）
";
CM_ SG_ 843 ADAS34B_7_6_FCW_TIMING_PTN_DISP "EYEカスタマイズ表示制御信号（FCW警報タイミング）
";
CM_ SG_ 843 ADAS34B_6_0_SAFTY_MODE_DISP_CONT "EYEカスタマイズ表示制御信号（踏み間違い加速抑制）
";
CM_ SG_ 843 ADAS34B_6_2_SAFTY_MODE_LV_DISP "EYEカスタマイズ表示制御信号（踏み間違い加速抑制-感度）
";
CM_ SG_ 843 ADAS34B_6_4_SAFTY_MODE_LV_PTN "EYEカスタマイズパターン指示信号（踏み間違い加速抑制-感度）
";
CM_ SG_ 843 ADAS34B_5_0_FCTI_DISP_CONT "EYEカスタマイズ表示制御信号（前側方警戒アシスト）
";
CM_ SG_ 843 ADAS34B_5_2_FCTI_NOTICE_DISP "EYEカスタマイズ表示制御信号（前側方警戒アシスト通知方法-制御）
";
CM_ SG_ 843 ADAS34B_5_4_FCTI_SOUND_DISP_CONT "EYEカスタマイズ表示制御信号（前側方警戒アシスト通知方法(音)）
";
CM_ SG_ 843 ADAS34B_5_6_FCTI_PULSE_DISP_CONT "EYEカスタマイズ表示制御信号（前側方警戒アシスト通知方法(振動)）
";
CM_ SG_ 843 ADAS34B_4_0_FCW_TYPE_DISP_CONT "EYEカスタマイズ表示制御信号（FCW警報方法-制御）
";
CM_ SG_ 843 ADAS34B_4_2_FCW_TYPE_SOUND_DISP "EYEカスタマイズ表示制御信号（FCW警報方法(音)）
";
CM_ SG_ 843 ADAS34B_4_4_FCW_TYPE_PULSE_DISP "EYEカスタマイズ表示制御信号（FCW警報方法(振動)）
";
CM_ SG_ 843 ADAS34B_4_6_FCW_SOUND_SW_DISP "EYEカスタマイズ表示制御信号（FCW音OFF）
";
CM_ SG_ 843 ADAS34B_3_0_P_CR_DISP_CONT "EYEカスタマイズ表示制御信号（プリクラッシュブレーキ）
";
CM_ SG_ 843 ADAS34B_3_2_BRAKE_TIMING_DISP "EYEカスタマイズ表示制御信号（ブレーキタイミング-制御）
";
CM_ SG_ 843 ADAS34B_3_4_FCW_DISP_CONT "EYEカスタマイズ表示制御信号（FCW警報タイミング-制御）
";
CM_ SG_ 843 ADAS34B_3_6_FCW_TIMING_DISP_PTN "EYEカスタマイズパターン指示信号（FCW警報タイミング）
";
CM_ SG_ 843 ADAS34B_2_0_E2E_COUNTER "E2Eｶｳﾝﾀ
";
CM_ SG_ 843 ADAS34B_0_0_E2E_CRC "CRC
";
CM_ SG_ 841 ADAS349_4_0_AAOS_AEB_STATE "AAOS用AEB状態
";
CM_ SG_ 841 ADAS349_3_0_CID_MRM_DISP "CID表示用MRM表示指示
";
CM_ SG_ 841 ADAS349_2_0_E2E_COUNTER "E2Eカウンタ
";
CM_ SG_ 841 ADAS349_0_0_E2E_CRC "CRC
";
CM_ SG_ 1100 EVCC44C_2_0_E2E_COUNTER "E2Eカウンタ
";
CM_ SG_ 1100 EVCC44C_0_0_E2E_CRC "CRC
";
CM_ SG_ 1099 EVCC44B_27_0_EVSE_ID_7_EVCC "EVSE ID_7_EVCC
";
CM_ SG_ 1099 EVCC44B_23_0_EVSE_ID_6_EVCC "EVSE ID_6_EVCC
";
CM_ SG_ 1099 EVCC44B_19_0_EVSE_ID_5_EVCC "EVSE ID_5_EVCC
";
CM_ SG_ 1099 EVCC44B_15_0_EVSE_ID_4_EVCC "EVSE ID_4_EVCC
";
CM_ SG_ 1099 EVCC44B_11_0_EVSE_ID_3_EVCC "EVSE ID_3_EVCC
";
CM_ SG_ 1099 EVCC44B_7_0_EVSE_ID_2_EVCC "EVSE ID_2_EVCC
";
CM_ SG_ 1099 EVCC44B_3_0_EVSE_ID_1_EVCC "EVSE ID_1_EVCC
";
CM_ SG_ 1099 EVCC44B_2_0_E2E_COUNTER "E2Eカウンタ
";
CM_ SG_ 1099 EVCC44B_0_0_E2E_CRC "CRC
";
CM_ SG_ 1098 EVCC44A_3_0_PNC_CC_SAVE_RES_RSLT "PnC契約関連証明書保存応答
";
CM_ SG_ 1098 EVCC44A_2_0_E2E_COUNTER "E2Eカウンタ
";
CM_ SG_ 1098 EVCC44A_0_0_E2E_CRC "CRC
";
CM_ SG_ 1097 EVCC449_2_0_E2E_COUNTER "E2Eカウンタ
";
CM_ SG_ 1097 EVCC449_0_0_E2E_CRC "CRC
";
CM_ SG_ 1096 EVCC448_4_0_EVSECONFPAYOPT "支払い方式
";
CM_ SG_ 1096 EVCC448_3_0_PNC_SW_RES_EVCC "PnCサービスONOFF切替応答_EVCC
";
CM_ SG_ 1096 EVCC448_3_4_PNC_SW_STS "PnC_ONOFFLOCK状態表示
";
CM_ SG_ 1096 EVCC448_3_7_SW_STS_ACTIVE_FLG "PnC状態表示_変化有無フラグ_EVCC
";
CM_ SG_ 1096 EVCC448_2_0_E2E_COUNTER "E2Eカウンタ
";
CM_ SG_ 1096 EVCC448_0_0_E2E_CRC "CRC
";
CM_ SG_ 1095 EVCC447_3_4_CHGWAKE "車両システム起動要求
";
CM_ SG_ 1095 EVCC447_3_0_CHGMODE "充放電モード
";
CM_ SG_ 1095 EVCC447_2_0_E2E_COUNTER "E2Eカウンタ
";
CM_ SG_ 1095 EVCC447_0_0_E2E_CRC "CRC
";
CM_ SG_ 1093 EVCC445_4_0_CHGCNRLOCSTT_DISPREQ "充電コネクタロック状態表示要求
";
CM_ SG_ 1093 EVCC445_3_0_DISPREQ "App表示要求ステータス
";
CM_ SG_ 1093 EVCC445_3_1_CNCTCONSTT_DISP "充電コネクタ接続状態
";
CM_ SG_ 1093 EVCC445_3_2_LIDOPSHSTT_DISP "リッド開閉状態
";
CM_ SG_ 1093 EVCC445_3_5_CNCTLCKSTT_DISP "充電コネクタロック状態
";
CM_ SG_ 1093 EVCC445_2_0_E2E_COUNTER "E2Eカウンタ
";
CM_ SG_ 1093 EVCC445_0_0_E2E_CRC "CRC
";
CM_ SG_ 1092 EVCC444_3_0_CNTCPLTYP "接続カプラータイプ
";
CM_ SG_ 1092 EVCC444_3_2_CHGFRM_CCU "充電方式
";
CM_ SG_ 1092 EVCC444_2_0_E2E_COUNTER "E2Eカウンタ
";
CM_ SG_ 1092 EVCC444_0_0_E2E_CRC "CRC
";
CM_ SG_ 1551 ENM60F_26_0_ACCMHVPWR_LC "総エネルギー消費_Last Charge
";
CM_ SG_ 1551 ENM60F_23_7_ACCMHVPWR_TRIPB "総エネルギー消費_TripB
";
CM_ SG_ 1551 ENM60F_21_6_ACCMHVPWR_TRIPA "総エネルギー消費_TripA
";
CM_ SG_ 1551 ENM60F_20_4_OTRACCMHVRATE_LC "その他消費電力割合_Last Charge
";
CM_ SG_ 1551 ENM60F_19_2_ACOUTACCMRATE_LC "車内コンセント使用量割合_Last Charge
";
CM_ SG_ 1551 ENM60F_18_0_BADJACCMHVRATE_LC "バッテリー温調消費電力割合_Last Charge
";
CM_ SG_ 1551 ENM60F_16_6_ACNACCMHVRATE_LC "空調消費電力割合_Last Charge
";
CM_ SG_ 1551 ENM60F_15_4_MOTACCMHVRATE_LC "運転消費電力割合_Last Charge
";
CM_ SG_ 1551 ENM60F_14_2_OTRACCMHVRATE_TRIPB "その他消費電力割合_TripB
";
CM_ SG_ 1551 ENM60F_13_0_ACOUTACCMRATE_TRIPB "車内コンセント使用量割合_TripB
";
CM_ SG_ 1551 ENM60F_11_6_BADJACCMHVRATE_TRIPB "バッテリー温調消費電力割合_TripB
";
CM_ SG_ 1551 ENM60F_10_4_ACNACCMHVRATE_TRIPB "空調消費電力割合_TripB
";
CM_ SG_ 1551 ENM60F_9_2_MOTACCMHVRATE_TRIPB "運転消費電力割合_TripB
";
CM_ SG_ 1551 ENM60F_8_0_OTRACCMHVRATE_TRIPA "その他消費電力割合_TripA
";
CM_ SG_ 1551 ENM60F_6_6_ACOUTACCMRATE_TRIPA "車内コンセント使用量割合_TripA
";
CM_ SG_ 1551 ENM60F_5_4_BADJACCMHVRATE_TRIPA "バッテリー温調消費電力割合_TripA
";
CM_ SG_ 1551 ENM60F_4_2_ACNACCMHVRATE_TRIPA "空調消費電力割合_TripA
";
CM_ SG_ 1551 ENM60F_3_0_MOTACCMHVRATE_TRIPA "運転消費電力割合_TripA
";
CM_ SG_ 1551 ENM60F_2_0_E2E_COUNTER "E2Eカウンタ
";
CM_ SG_ 1551 ENM60F_0_0_E2E_CRC "CRC
";
CM_ SG_ 1550 ENM60E_28_0_DRNDISPREQ "排水表示要求
";
CM_ SG_ 1550 ENM60E_27_0_INJDISPREQ "注水表示要求
";
CM_ SG_ 1550 ENM60E_26_0_HVBTHMADJSTT "バッテリー温調状態
";
CM_ SG_ 1550 ENM60E_26_1_ACNOFFCMD "エアコン動作状態の表示要求
";
CM_ SG_ 1550 ENM60E_26_3_IJDRMDONOFF "注水排水モード有無
";
CM_ SG_ 1550 ENM60E_26_4_ACNHVDDRVADM "エアコン高圧デバイス駆動許可
";
CM_ SG_ 1550 ENM60E_26_5_ACNINHSIG "空調禁止信号
";
CM_ SG_ 1550 ENM60E_25_0_CNSPPWR_RATE "その他消費電力割合
";
CM_ SG_ 1550 ENM60E_24_0_V2LPWR_RATE "車内コンセント使用量割合
";
CM_ SG_ 1550 ENM60E_23_0_HVBCNSPPWR_RATE "バッテリー温調消費電力割合
";
CM_ SG_ 1550 ENM60E_22_0_ACNPWR_RATE "空調消費電力割合
";
CM_ SG_ 1550 ENM60E_21_0_DRVPWR_RATE "運転消費電力割合
";
CM_ SG_ 1550 ENM60E_20_0_AVECNSPPWR15 "車両平均電費15
";
CM_ SG_ 1550 ENM60E_19_0_AVECNSPPWR14 "車両平均電費14
";
CM_ SG_ 1550 ENM60E_18_0_AVECNSPPWR13 "車両平均電費13
";
CM_ SG_ 1550 ENM60E_17_0_AVECNSPPWR12 "車両平均電費12
";
CM_ SG_ 1550 ENM60E_16_0_AVECNSPPWR11 "車両平均電費11
";
CM_ SG_ 1550 ENM60E_15_0_AVECNSPPWR10 "車両平均電費10
";
CM_ SG_ 1550 ENM60E_14_0_AVECNSPPWR9 "車両平均電費9
";
CM_ SG_ 1550 ENM60E_13_0_AVECNSPPWR8 "車両平均電費8
";
CM_ SG_ 1550 ENM60E_12_0_AVECNSPPWR7 "車両平均電費7
";
CM_ SG_ 1550 ENM60E_11_0_AVECNSPPWR6 "車両平均電費6
";
CM_ SG_ 1550 ENM60E_10_0_AVECNSPPWR5 "車両平均電費5
";
CM_ SG_ 1550 ENM60E_9_0_AVECNSPPWR4 "車両平均電費4
";
CM_ SG_ 1550 ENM60E_8_0_AVECNSPPWR3 "車両平均電費３
";
CM_ SG_ 1550 ENM60E_7_0_AVECNSPPWR2 "車両平均電費２
";
CM_ SG_ 1550 ENM60E_6_0_AVECNSPPWR1 "車両平均電費1
";
CM_ SG_ 1550 ENM60E_5_0_HVBAVETEMP "平均セル温度
";
CM_ SG_ 1550 ENM60E_4_0_AUXCNSPPWR "補機消費電力
";
CM_ SG_ 1550 ENM60E_3_0_ACNCNSPPWR "空調消費電力
";
CM_ SG_ 1550 ENM60E_2_0_E2E_COUNTER "E2Eカウンタ
";
CM_ SG_ 1550 ENM60E_0_0_E2E_CRC "CRC
";
CM_ SG_ 1549 ENM60D_2_0_TOWMDSTS "トーイングステータス
";
CM_ SG_ 1549 ENM60D_1_0_MSG_COUNTER "メッセージカウンタ
";
CM_ SG_ 1549 ENM60D_0_0_CHECK_SUM "チェックサム
";
CM_ SG_ 1548 ENM60C_27_2_VEHPWRTRIPLOG "TRIP LOG用電力積算量
";
CM_ SG_ 1548 ENM60C_26_0_HVBWIN "Win現在値
";
CM_ SG_ 1548 ENM60C_24_6_THMADJPRDWIN "現在のWin見積り値
";
CM_ SG_ 1548 ENM60C_23_3_ACNOFF_DRVRANG "ACOFF時航続可能距離
";
CM_ SG_ 1548 ENM60C_22_0_ACNON_DRVRANG "ACON時航続可能距離
";
CM_ SG_ 1548 ENM60C_21_2_HVBTEMPSTT "表示用バッテリー温度状態
";
CM_ SG_ 1548 ENM60C_20_4_OUTLMTDISREQ "エネマネによる出力制限表示要求
";
CM_ SG_ 1548 ENM60C_20_7_CHGLMTDISREQ "エネマネによる充電制限表示要求
";
CM_ SG_ 1548 ENM60C_19_1_VEHPWREFF_TRIPB "TRIP_B電費
";
CM_ SG_ 1548 ENM60C_17_6_VEHPWREFF_TRIPA "TRIP_A電費
";
CM_ SG_ 1548 ENM60C_16_3_VEHPWREFF_ODO "TRIP_ODO電費
";
CM_ SG_ 1548 ENM60C_15_0_VEHPWREFF "瞬間電費
";
CM_ SG_ 1548 ENM60C_14_0_PRCNSTT "即時プレコン許可状態
";
CM_ SG_ 1548 ENM60C_14_2_PRCNSTTFBK "即時プレコンディショニング状態F/B
";
CM_ SG_ 1548 ENM60C_14_4_ACNLMTDISREQ "エネマネによる空調制限表示要求
";
CM_ SG_ 1548 ENM60C_13_0_STCTDISPREQ "即時プレコン通知表示要求
";
CM_ SG_ 1548 ENM60C_13_3_VEHPRDDIS_JDG "走行可能距離切替情報
";
CM_ SG_ 1548 ENM60C_13_6_PFOMDJDG "パフォーマンスモード判定
";
CM_ SG_ 1548 ENM60C_12_0_HVBTEMP "電池セル温度
";
CM_ SG_ 1548 ENM60C_11_0_HVBTGTTEMP "電池セル目標温度
";
CM_ SG_ 1548 ENM60C_10_0_PFOMDSTP "パフォーマンスモードキャンセル通知
";
CM_ SG_ 1548 ENM60C_10_3_HVBTHMADJSTT "表示用バッテリー温調状態
";
CM_ SG_ 1548 ENM60C_10_6_PFOMDCNTN "パフォーマンスモード継続推奨通知
";
CM_ SG_ 1548 THM60C_10_7_PWRMDJDG "パワーモード判定
";
CM_ SG_ 1548 ENM60C_9_0_ENHCHGTIM "表示用電池温調による充電時間効果
";
CM_ SG_ 1548 ENM60C_8_0_THMADJTIM_PRCNSW "プレコンSWによる電池温調所要時間
";
CM_ SG_ 1548 ENM60C_7_0_THMADJPRDSOC "電池温調予測消費(表示)SOC
";
CM_ SG_ 1548 ENM60C_6_0_HVBTHMADJPWR "表示用電池温調所要電力
";
CM_ SG_ 1548 ENM60C_5_0_THMADJTIM_PFOMD "パフォーマンスモードによる電池温調所要時間
";
CM_ SG_ 1548 ENM60C_4_0_HVBTHMADJTIM "表示用電池温調所要時間
";
CM_ SG_ 1548 ENM60C_3_1_TRLSTSDISREQ "トレーラー接続表示要求
";
CM_ SG_ 1548 ENM60C_3_3_TOWMDFAILDISREQ "トーイング異常時表示要求
";
CM_ SG_ 1548 ENM60C_3_6_CHGTIPDISPREQ "充電Tips通知要求
";
CM_ SG_ 1548 ENM60C_2_0_E2E_COUNTER "E2Eカウンタ
";
CM_ SG_ 1548 ENM60C_0_0_E2E_CRC "CRC
";
CM_ SG_ 857 THM359_5_1_HVBOUTLTEMPREL "電池出口水温センサ信頼性情報
";
CM_ SG_ 857 THM359_4_0_HVBOUTLTEMP "電池出口水温センサ温度
";
CM_ SG_ 857 THM359_3_1_HVBINLTEMPREL "電池入口水温センサ信頼性情報
";
CM_ SG_ 857 THM359_3_3_IJDRMDTRFREQ "注排水移行要求
";
CM_ SG_ 857 THM359_2_0_HVBINLTEMP "電池入口水温センサ温度
";
CM_ SG_ 857 THM359_1_0_MSG_COUNTER "メッセージカウンタ
";
CM_ SG_ 857 THM359_0_0_CHECK_SUM "チェックサム
";
CM_ SG_ 1485 CHR5CD_27_0_EVSE_ID_7_CHR "EVSE_ID_7_CHR
";
CM_ SG_ 1485 CHR5CD_23_0_EVSE_ID_6_CHR "EVSE_ID_6_CHR
";
CM_ SG_ 1485 CHR5CD_19_0_EVSE_ID_5_CHR "EVSE_ID_5_CHR
";
CM_ SG_ 1485 CHR5CD_15_0_EVSE_ID_4_CHR "EVSE_ID_4_CHR
";
CM_ SG_ 1485 CHR5CD_11_0_EVSE_ID_3_CHR "EVSE_ID_3_CHR
";
CM_ SG_ 1485 CHR5CD_7_0_EVSE_ID_2_CHR "EVSE_ID_2_CHR
";
CM_ SG_ 1485 CHR5CD_3_0_EVSE_ID_1_CHR "EVSE_ID_1_CHR
";
CM_ SG_ 1485 CHR5CD_2_0_E2E_COUNTER "E2Eカウンタ
";
CM_ SG_ 1485 CHR5CD_0_0_E2E_CRC "CRC
";
CM_ SG_ 1116 CHR45C_29_0_BYTE21 "開発用変数21
";
CM_ SG_ 1116 CHR45C_28_0_BYTE20 "開発用変数20
";
CM_ SG_ 1116 CHR45C_27_0_BYTE19 "開発用変数19
";
CM_ SG_ 1116 CHR45C_26_0_BYTE18 "開発用変数18
";
CM_ SG_ 1116 CHR45C_25_0_BYTE17 "開発用変数17
";
CM_ SG_ 1116 CHR45C_24_0_BYTE16 "開発用変数16
";
CM_ SG_ 1116 CHR45C_23_0_BYTE15 "開発用変数15
";
CM_ SG_ 1116 CHR45C_22_0_BYTE14 "開発用変数14
";
CM_ SG_ 1116 CHR45C_21_0_BYTE13 "開発用変数13
";
CM_ SG_ 1116 CHR45C_20_0_BYTE12 "開発用変数12
";
CM_ SG_ 1116 CHR45C_19_0_BYTE11 "開発用変数11
";
CM_ SG_ 1116 CHR45C_18_0_BYTE10 "開発用変数10
";
CM_ SG_ 1116 CHR45C_17_0_BYTE9 "開発用変数9
";
CM_ SG_ 1116 CHR45C_16_0_BYTE8 "開発用変数8
";
CM_ SG_ 1116 CHR45C_15_0_BYTE7 "開発用変数7
";
CM_ SG_ 1116 CHR45C_14_0_BYTE6 "開発用変数6
";
CM_ SG_ 1116 CHR45C_13_0_BYTE5 "開発用変数5
";
CM_ SG_ 1116 CHR45C_12_0_BYTE4 "開発用変数4
";
CM_ SG_ 1116 CHR45C_11_0_BYTE3 "開発用変数3
";
CM_ SG_ 1116 CHR45C_10_0_BYTE2 "開発用変数2
";
CM_ SG_ 1116 CHR45C_9_0_LIDLOCK_DISC_DT "リッドロック断線検知
";
CM_ SG_ 1116 CHR45C_9_2_LIDOP "リッド開閉情報
";
CM_ SG_ 1116 CHR45C_8_3_CHGSTARTSTOP "充電開始終了
";
CM_ SG_ 1116 CHR45C_8_2_LIDOP_BUZ_REQ "リッド開_ブザー吹鳴要求
";
CM_ SG_ 1116 CHR45C_8_1_LIDOP_WARDISP_REQ "リッド開_警告表示要求
";
CM_ SG_ 1116 CHR45C_8_0_CHG_CNRCNTSTT "充電コネクタ接続状態(表示用)
";
CM_ SG_ 1116 CHR45C_6_0_FEDPWR_DISP "給電電力（表示用）
";
CM_ SG_ 1116 CHR45C_4_0_CHGPWR_DISP "充電電力（表示用）
";
CM_ SG_ 1116 CHR45C_3_0_CHGFEDSTT "充給電状態
";
CM_ SG_ 1116 CHR45C_2_0_E2E_COUNTER "E2Eカウンタ
";
CM_ SG_ 1116 CHR45C_0_0_E2E_CRC "CRC
";
CM_ SG_ 1111 CHR457_31_0_BYTE29 "開発用変数29
";
CM_ SG_ 1111 CHR457_30_0_BYTE28 "開発用変数28
";
CM_ SG_ 1111 CHR457_29_0_BYTE27 "開発用変数27
";
CM_ SG_ 1111 CHR457_28_0_BYTE26 "開発用変数26
";
CM_ SG_ 1111 CHR457_27_0_BYTE25 "開発用変数25
";
CM_ SG_ 1111 CHR457_26_0_BYTE24 "開発用変数24
";
CM_ SG_ 1111 CHR457_25_0_BYTE23 "開発用変数23
";
CM_ SG_ 1111 CHR457_24_0_BYTE22 "開発用変数22
";
CM_ SG_ 1111 CHR457_23_0_BYTE21 "開発用変数21
";
CM_ SG_ 1111 CHR457_22_0_BYTE20 "開発用変数20
";
CM_ SG_ 1111 CHR457_21_0_BYTE19 "開発用変数19
";
CM_ SG_ 1111 CHR457_20_0_BYTE18 "開発用変数18
";
CM_ SG_ 1111 CHR457_19_0_BYTE17 "開発用変数17
";
CM_ SG_ 1111 CHR457_18_0_BYTE16 "開発用変数16
";
CM_ SG_ 1111 CHR457_17_0_BYTE15 "開発用変数15
";
CM_ SG_ 1111 CHR457_16_0_BYTE14 "開発用変数14
";
CM_ SG_ 1111 CHR457_15_0_BYTE13 "開発用変数13
";
CM_ SG_ 1111 CHR457_14_0_BYTE12 "開発用変数12
";
CM_ SG_ 1111 CHR457_13_0_BYTE11 "開発用変数11
";
CM_ SG_ 1111 CHR457_12_6_ENERGY_CHARGED_DISP "充電電力量(kWh)
";
CM_ SG_ 1111 CHR457_11_7_DLTSOCCALC_FIN "デルタSOC(充電完了後)_統合CU
";
CM_ SG_ 1111 CHR457_11_0_DLTSOCCALC_STRT "デルタSOC(充電開始時)_統合CU
";
CM_ SG_ 1111 CHR457_10_6_STLMT_TYPE "決済方式_統合CU
";
CM_ SG_ 1111 CHR457_10_4_ACDC_INFO "AC/DC 情報_統合CU
";
CM_ SG_ 1111 CHR457_9_0_CHGTIM "充電時間_統合CU
";
CM_ SG_ 1111 CHR457_8_0_BYTE6 "開発用変数6
";
CM_ SG_ 1111 CHR457_7_0_BYTE5 "開発用変数5
";
CM_ SG_ 1111 CHR457_6_4_DCPWRSUPSTOP_DISP "給電停止完了通知(表示用)
";
CM_ SG_ 1111 CHR457_6_0_DCPWRSUPSTRT_DISP "給電開始通知(表示用)
";
CM_ SG_ 1111 CHR457_5_0_CHGSTRTNTCE_DISP "充電開始通知(表示用)
";
CM_ SG_ 1111 CHR457_5_4_CHGENDNTCE_DISP "充電終了通知(表示用)
";
CM_ SG_ 1111 CHR457_4_0_FEDSTPRSN_DISP "給電停止要因
";
CM_ SG_ 1111 CHR457_3_0_CHGSTPRSN_DISP "充電停止要因
";
CM_ SG_ 1111 CHR457_2_0_E2E_COUNTER "E2Eカウンタ
";
CM_ SG_ 1111 CHR457_0_0_E2E_CRC "CRC
";
CM_ SG_ 1109 CHR455_31_3_CHGCNRLOCSTT_DISPREQ "充電コネクタロック状態表示要求
";
CM_ SG_ 1109 CHR455_28_4_VEH_CHGPWRUPLMT "車両受け入れ可能上限電力
";
CM_ SG_ 1109 CHR455_27_4_V2H_MODE "V2H充放電モード
";
CM_ SG_ 1109 CHR455_26_4_DCPWRSUPSTT "DC給電状態
";
CM_ SG_ 1109 CHR455_26_3_CHGMNTDISP_REQ "充電画面表示要求
";
CM_ SG_ 1109 CHR455_26_2_MNTLIT_REQ "画面点灯要求
";
CM_ SG_ 1109 CHR455_25_0_CHGVLT_DISP "充電電圧(表示用)
";
CM_ SG_ 1109 CHR455_23_0_CHGCUR_DISP "充電電流(表示用)
";
CM_ SG_ 1109 CHR455_22_1_CHGSTPCOMP "充電停止完了通知
";
CM_ SG_ 1109 CHR455_20_1_ENERGY_CHARGED_DISP "充電電力量(kWh)
";
CM_ SG_ 1109 CHR455_19_2_DLTSOCCALC_FIN "デルタSOC(充電完了後)_統合CU
";
CM_ SG_ 1109 CHR455_18_3_DLTSOCCALC_STRT "デルタSOC(充電開始時)_統合CU
";
CM_ SG_ 1109 CHR455_18_2_STLMT_TYPE "決済方式_統合CU
";
CM_ SG_ 1109 CHR455_18_1_ACDC_INFO "AC/DC 情報_統合CU
";
CM_ SG_ 1109 CHR455_16_6_EVSEOUTPWR "充電スタンド出力電力
";
CM_ SG_ 1109 CHR455_13_3_CHG_FINTIM "充電完了時間_統合CU
";
CM_ SG_ 1109 CHR455_12_0_CHGTIM "充電時間_統合CU
";
CM_ SG_ 1109 CHR455_10_7_DCPWRSUP_PWR_DISP "DC車両供給電力（表示用）
";
CM_ SG_ 1109 CHR455_8_7_CHGPWR_DISP "充電電力（表示用）
";
CM_ SG_ 1109 CHR455_7_1_DCPWRSUP_ADMTIM "DC給電可能時間
";
CM_ SG_ 1109 CHR455_6_1_CHGSTT "充電状態
";
CM_ SG_ 1109 CHR455_5_2_FED_LOLMT "給電量下限値
";
CM_ SG_ 1109 CHR455_4_6_DCCHG_PWRUPLMT "DC充電電力上限設定値
";
CM_ SG_ 1109 CHR455_4_2_ACCHG_CURUPLMT "AC充電電流上限設定値
";
CM_ SG_ 1109 CHR455_3_3_CHG_HILMT "充電量上限値
";
CM_ SG_ 1109 CHR455_3_1_CHG_CNRLOCSTT "充電コネクタロック状態（表示用）
";
CM_ SG_ 1109 CHR455_3_0_CHG_CNRCNTSTT "充電コネクタ接続状態(表示用)
";
CM_ SG_ 1109 CHR455_2_0_E2E_COUNTER "E2Eカウンタ
";
CM_ SG_ 1109 CHR455_0_0_E2E_CRC "CRC
";
BA_DEF_  "DBCConverterVersion" STRING ;
BA_DEF_  "Manufacturer" STRING ;
BA_DEF_  "BusType" STRING ;
BA_DEF_ BU_  "DiagNode" ENUM  "No","Yes";
BA_DEF_ BU_  "ILUsed" ENUM  "No","Yes";
BA_DEF_ BU_  "NodeLayerModules" STRING ;
BA_DEF_ SG_  "Fhi_SignalComment" STRING ;
BA_DEF_ SG_  "GenSigInactiveValue" INT 0 10000;
BA_DEF_ SG_  "GenSigStartValue" FLOAT 0 100000000000;
BA_DEF_ SG_  "GenSigSendType" ENUM  "Cyclic","OnWrite","OnWriteWithRepetition","OnChange","OnChangeWithRepetition","IfActive","IfActiveWithRepetition","NoSigSendType";
BA_DEF_ BO_  "MsgRoutingId" STRING ;
BA_DEF_ BO_  "DiagResponse" ENUM  "No","Yes";
BA_DEF_ BO_  "DiagRequest" ENUM  "No","Yes";
BA_DEF_ BO_  "DiagState" ENUM  "No","Yes";
BA_DEF_ BO_  "GenMsgILSupport" ENUM  "No","Yes";
BA_DEF_ BO_  "GenMsgNrOfRepetition" INT 0 999999;
BA_DEF_ BO_  "GenMsgDelayTime" INT 0 1000;
BA_DEF_ BO_  "GenMsgCycleTimeFast" INT 0 10000;
BA_DEF_ BO_  "GenMsgCycleTime" INT 0 10000;
BA_DEF_ BO_  "GenMsgSendType" ENUM  "Cyclic","NotUsed","NotUsed","NotUsed","NotUsed","Cyclic","NotUsed","IfActive","NoMsgSendType";
BA_DEF_ BO_  "CANFD_BRS" ENUM  "0","1";
BA_DEF_ BO_  "VFrameFormat" ENUM  "StandardCAN","ExtendedCAN","reserved","reserved","reserved","reserved","reserved","reserved","reserved","reserved","reserved","reserved","reserved","reserved","StandardCAN_FD","ExtendedCAN_FD";
BA_DEF_DEF_  "DBCConverterVersion" "2.0";
BA_DEF_DEF_  "Manufacturer" "FHI";
BA_DEF_DEF_  "BusType" "";
BA_DEF_DEF_  "DiagNode" "No";
BA_DEF_DEF_  "ILUsed" "Yes";
BA_DEF_DEF_  "NodeLayerModules" "CANoeILNLSubaru.dll";
BA_DEF_DEF_  "Fhi_SignalComment" "";
BA_DEF_DEF_  "GenSigInactiveValue" 0;
BA_DEF_DEF_  "GenSigStartValue" 0;
BA_DEF_DEF_  "GenSigSendType" "NoSigSendType";
BA_DEF_DEF_  "MsgRoutingId" "";
BA_DEF_DEF_  "DiagResponse" "No";
BA_DEF_DEF_  "DiagRequest" "No";
BA_DEF_DEF_  "DiagState" "No";
BA_DEF_DEF_  "GenMsgILSupport" "Yes";
BA_DEF_DEF_  "GenMsgNrOfRepetition" 0;
BA_DEF_DEF_  "GenMsgDelayTime" 0;
BA_DEF_DEF_  "GenMsgCycleTimeFast" 0;
BA_DEF_DEF_  "GenMsgCycleTime" 0;
BA_DEF_DEF_  "GenMsgSendType" "Cyclic";
BA_DEF_DEF_  "CANFD_BRS" "1";
BA_DEF_DEF_  "VFrameFormat" "StandardCAN";
BA_ "BusType" "CAN FD";
BA_ "DiagNode" BU_ DCM 1;
BA_ "DiagNode" BU_ CCU 1;
BA_ "DiagNode" BU_ C_ECU 1;
BA_ "DiagNode" BU_ C_ECU_GW 1;
BA_ "GenMsgCycleTime" BO_ 552 50;
BA_ "GenMsgDelayTime" BO_ 552 10;
BA_ "GenMsgNrOfRepetition" BO_ 552 1;
BA_ "MsgRoutingId" BO_ 552 "279 ";
BA_ "GenMsgILSupport" BO_ 552 0;
BA_ "VFrameFormat" BO_ 552 14;
BA_ "GenMsgCycleTime" BO_ 1606 1000;
BA_ "GenMsgDelayTime" BO_ 1606 50;
BA_ "GenMsgCycleTimeFast" BO_ 1606 50;
BA_ "GenMsgNrOfRepetition" BO_ 1606 2;
BA_ "MsgRoutingId" BO_ 1606 "278 ";
BA_ "GenMsgILSupport" BO_ 1606 0;
BA_ "VFrameFormat" BO_ 1606 14;
BA_ "GenMsgCycleTime" BO_ 965 100;
BA_ "GenMsgDelayTime" BO_ 965 50;
BA_ "GenMsgCycleTimeFast" BO_ 965 50;
BA_ "GenMsgNrOfRepetition" BO_ 965 2;
BA_ "MsgRoutingId" BO_ 965 "275 ";
BA_ "GenMsgILSupport" BO_ 965 0;
BA_ "VFrameFormat" BO_ 965 14;
BA_ "GenMsgCycleTime" BO_ 964 100;
BA_ "GenMsgDelayTime" BO_ 964 50;
BA_ "GenMsgCycleTimeFast" BO_ 964 50;
BA_ "GenMsgNrOfRepetition" BO_ 964 2;
BA_ "MsgRoutingId" BO_ 964 "274 ";
BA_ "GenMsgILSupport" BO_ 964 0;
BA_ "VFrameFormat" BO_ 964 14;
BA_ "GenMsgCycleTime" BO_ 805 100;
BA_ "GenMsgDelayTime" BO_ 805 20;
BA_ "GenMsgCycleTimeFast" BO_ 805 50;
BA_ "GenMsgNrOfRepetition" BO_ 805 2;
BA_ "MsgRoutingId" BO_ 805 "271 ";
BA_ "GenMsgILSupport" BO_ 805 0;
BA_ "VFrameFormat" BO_ 805 14;
BA_ "GenMsgCycleTime" BO_ 803 100;
BA_ "GenMsgDelayTime" BO_ 803 50;
BA_ "GenMsgCycleTimeFast" BO_ 803 50;
BA_ "GenMsgNrOfRepetition" BO_ 803 2;
BA_ "MsgRoutingId" BO_ 803 "269 ";
BA_ "GenMsgILSupport" BO_ 803 0;
BA_ "VFrameFormat" BO_ 803 14;
BA_ "GenMsgCycleTime" BO_ 802 100;
BA_ "GenMsgDelayTime" BO_ 802 50;
BA_ "GenMsgCycleTimeFast" BO_ 802 50;
BA_ "GenMsgNrOfRepetition" BO_ 802 2;
BA_ "MsgRoutingId" BO_ 802 "268 ";
BA_ "GenMsgILSupport" BO_ 802 0;
BA_ "VFrameFormat" BO_ 802 14;
BA_ "GenMsgCycleTime" BO_ 801 100;
BA_ "GenMsgDelayTime" BO_ 801 50;
BA_ "GenMsgCycleTimeFast" BO_ 801 50;
BA_ "GenMsgNrOfRepetition" BO_ 801 2;
BA_ "MsgRoutingId" BO_ 801 "267 ";
BA_ "GenMsgILSupport" BO_ 801 0;
BA_ "VFrameFormat" BO_ 801 14;
BA_ "GenMsgCycleTime" BO_ 1746 1000;
BA_ "MsgRoutingId" BO_ 1746 "264 ";
BA_ "GenMsgILSupport" BO_ 1746 0;
BA_ "VFrameFormat" BO_ 1746 14;
BA_ "GenMsgCycleTime" BO_ 845 100;
BA_ "MsgRoutingId" BO_ 845 "259 ";
BA_ "GenMsgILSupport" BO_ 845 0;
BA_ "VFrameFormat" BO_ 845 14;
BA_ "GenMsgCycleTime" BO_ 844 100;
BA_ "GenMsgDelayTime" BO_ 844 50;
BA_ "GenMsgCycleTimeFast" BO_ 844 50;
BA_ "GenMsgNrOfRepetition" BO_ 844 2;
BA_ "MsgRoutingId" BO_ 844 "258 ";
BA_ "GenMsgILSupport" BO_ 844 0;
BA_ "VFrameFormat" BO_ 844 14;
BA_ "GenMsgCycleTime" BO_ 843 100;
BA_ "GenMsgDelayTime" BO_ 843 50;
BA_ "GenMsgCycleTimeFast" BO_ 843 50;
BA_ "GenMsgNrOfRepetition" BO_ 843 2;
BA_ "MsgRoutingId" BO_ 843 "257 ";
BA_ "GenMsgILSupport" BO_ 843 0;
BA_ "VFrameFormat" BO_ 843 14;
BA_ "GenMsgCycleTime" BO_ 841 100;
BA_ "GenMsgDelayTime" BO_ 841 50;
BA_ "GenMsgCycleTimeFast" BO_ 841 50;
BA_ "GenMsgNrOfRepetition" BO_ 841 2;
BA_ "MsgRoutingId" BO_ 841 "256 ";
BA_ "GenMsgILSupport" BO_ 841 0;
BA_ "VFrameFormat" BO_ 841 14;
BA_ "GenMsgCycleTime" BO_ 1100 100;
BA_ "MsgRoutingId" BO_ 1100 "247 ";
BA_ "GenMsgILSupport" BO_ 1100 0;
BA_ "VFrameFormat" BO_ 1100 14;
BA_ "GenMsgCycleTime" BO_ 1099 100;
BA_ "MsgRoutingId" BO_ 1099 "246 ";
BA_ "GenMsgILSupport" BO_ 1099 0;
BA_ "VFrameFormat" BO_ 1099 14;
BA_ "GenMsgSendType" BO_ 1098 8;
BA_ "GenMsgCycleTimeFast" BO_ 1098 100;
BA_ "GenMsgNrOfRepetition" BO_ 1098 3;
BA_ "MsgRoutingId" BO_ 1098 "245 ";
BA_ "GenMsgILSupport" BO_ 1098 0;
BA_ "VFrameFormat" BO_ 1098 14;
BA_ "GenMsgCycleTime" BO_ 1097 100;
BA_ "MsgRoutingId" BO_ 1097 "244 ";
BA_ "GenMsgILSupport" BO_ 1097 0;
BA_ "VFrameFormat" BO_ 1097 14;
BA_ "GenMsgCycleTime" BO_ 1096 100;
BA_ "MsgRoutingId" BO_ 1096 "243 ";
BA_ "GenMsgILSupport" BO_ 1096 0;
BA_ "VFrameFormat" BO_ 1096 14;
BA_ "GenMsgCycleTime" BO_ 1095 100;
BA_ "GenMsgDelayTime" BO_ 1095 10;
BA_ "GenMsgNrOfRepetition" BO_ 1095 1;
BA_ "MsgRoutingId" BO_ 1095 "242 ";
BA_ "GenMsgILSupport" BO_ 1095 0;
BA_ "VFrameFormat" BO_ 1095 14;
BA_ "GenMsgCycleTime" BO_ 1093 100;
BA_ "GenMsgNrOfRepetition" BO_ 1093 1;
BA_ "MsgRoutingId" BO_ 1093 "240 ";
BA_ "GenMsgILSupport" BO_ 1093 0;
BA_ "VFrameFormat" BO_ 1093 14;
BA_ "GenMsgCycleTime" BO_ 1092 100;
BA_ "MsgRoutingId" BO_ 1092 "239 ";
BA_ "GenMsgILSupport" BO_ 1092 0;
BA_ "VFrameFormat" BO_ 1092 14;
BA_ "GenMsgCycleTime" BO_ 1551 1000;
BA_ "GenMsgDelayTime" BO_ 1551 10;
BA_ "GenMsgCycleTimeFast" BO_ 1551 20;
BA_ "GenMsgNrOfRepetition" BO_ 1551 3;
BA_ "MsgRoutingId" BO_ 1551 "238 ";
BA_ "GenMsgILSupport" BO_ 1551 0;
BA_ "VFrameFormat" BO_ 1551 14;
BA_ "GenMsgCycleTime" BO_ 1550 1000;
BA_ "GenMsgDelayTime" BO_ 1550 10;
BA_ "GenMsgCycleTimeFast" BO_ 1550 20;
BA_ "GenMsgNrOfRepetition" BO_ 1550 3;
BA_ "MsgRoutingId" BO_ 1550 "237 ";
BA_ "GenMsgILSupport" BO_ 1550 0;
BA_ "VFrameFormat" BO_ 1550 14;
BA_ "GenMsgCycleTime" BO_ 1549 1000;
BA_ "GenMsgDelayTime" BO_ 1549 10;
BA_ "GenMsgCycleTimeFast" BO_ 1549 20;
BA_ "GenMsgNrOfRepetition" BO_ 1549 3;
BA_ "MsgRoutingId" BO_ 1549 "236 ";
BA_ "GenMsgILSupport" BO_ 1549 0;
BA_ "VFrameFormat" BO_ 1549 14;
BA_ "GenMsgCycleTime" BO_ 1548 1000;
BA_ "GenMsgDelayTime" BO_ 1548 10;
BA_ "GenMsgCycleTimeFast" BO_ 1548 20;
BA_ "GenMsgNrOfRepetition" BO_ 1548 3;
BA_ "MsgRoutingId" BO_ 1548 "235 ";
BA_ "GenMsgILSupport" BO_ 1548 0;
BA_ "VFrameFormat" BO_ 1548 14;
BA_ "GenMsgCycleTime" BO_ 857 100;
BA_ "GenMsgDelayTime" BO_ 857 10;
BA_ "GenMsgCycleTimeFast" BO_ 857 20;
BA_ "GenMsgNrOfRepetition" BO_ 857 3;
BA_ "MsgRoutingId" BO_ 857 "234 ";
BA_ "GenMsgILSupport" BO_ 857 0;
BA_ "VFrameFormat" BO_ 857 14;
BA_ "GenMsgSendType" BO_ 1485 8;
BA_ "GenMsgCycleTimeFast" BO_ 1485 100;
BA_ "GenMsgNrOfRepetition" BO_ 1485 3;
BA_ "MsgRoutingId" BO_ 1485 "227 ";
BA_ "GenMsgILSupport" BO_ 1485 0;
BA_ "VFrameFormat" BO_ 1485 14;
BA_ "GenMsgCycleTime" BO_ 1116 100;
BA_ "MsgRoutingId" BO_ 1116 "226 ";
BA_ "GenMsgILSupport" BO_ 1116 0;
BA_ "VFrameFormat" BO_ 1116 14;
BA_ "GenMsgCycleTime" BO_ 1111 100;
BA_ "GenMsgNrOfRepetition" BO_ 1111 3;
BA_ "MsgRoutingId" BO_ 1111 "225 ";
BA_ "GenMsgILSupport" BO_ 1111 0;
BA_ "VFrameFormat" BO_ 1111 14;
BA_ "GenMsgCycleTime" BO_ 1109 100;
BA_ "MsgRoutingId" BO_ 1109 "224 ";
BA_ "GenMsgILSupport" BO_ 1109 0;
BA_ "VFrameFormat" BO_ 1109 14;
BA_ "GenSigStartValue" SG_ 552 RDR228_6_5_BLOCKAGE_STS 5;
BA_ "GenSigSendType" SG_ 552 RDR228_4_3_WARN_DOW_2ST_R 3;
BA_ "GenSigSendType" SG_ 552 RDR228_4_4_WARN_DOW_2ST_L 3;
BA_ "GenSigStartValue" SG_ 552 RDR228_3_0_WARN_BSD_LCA_R_2ND 1;
BA_ "Fhi_SignalComment" SG_ 552 RDR228_2_6_ON_OFF_RDRSYS "SW情報：ﾗｽﾄﾒﾓﾘ

";
BA_ "GenSigStartValue" SG_ 552 RDR228_1_4_BATT_OFF_CAUSE 1;
BA_ "GenSigStartValue" SG_ 805 EYE325_2_0_RAB_OFF 1;
BA_ "GenSigStartValue" SG_ 805 EYE325_2_1_SONAR_OFF 1;
BA_ "GenSigStartValue" SG_ 805 EYE325_2_6_RAB_DISABLE 1;
BA_ "GenSigStartValue" SG_ 805 EYE325_2_7_SONAR_DISABLE 1;
BA_ "GenSigStartValue" SG_ 805 EYE325_1_7_SONAR_NO_DISP 1;
BA_ "GenSigStartValue" SG_ 803 EYE323_7_0_ISA_OFFSET_CURR 10;
BA_ "GenSigStartValue" SG_ 803 EYE323_6_1_LDW_ON_OFF_SET 1;
BA_ "GenSigStartValue" SG_ 803 EYE323_5_3_FCW_ON_OFF_SET 1;
BA_ "GenSigStartValue" SG_ 801 EYE321_4_2_SRVD_LASTMEM_ST_REQ 1;
BA_ "GenSigStartValue" SG_ 801 EYE321_1_4_PRECRASH_BRAKE_OFF 1;
BA_ "GenSigStartValue" SG_ 801 EYE321_1_5_LANE_DEPARTURE_OFF 1;
BA_ "GenSigStartValue" SG_ 1746 LCT6D2_5_0_HDMAP_RELEASE_SEASON 15;
BA_ "GenSigStartValue" SG_ 1746 LCT6D2_5_4_HDMAP_RELEASE_REV 15;
BA_ "GenSigStartValue" SG_ 1746 LCT6D2_4_0_HDMAP_RELEASE_YEAR 255;
BA_ "GenSigStartValue" SG_ 1746 LCT6D2_3_0_ISAMAP_RELEASE_SEASON 15;
BA_ "GenSigStartValue" SG_ 1746 LCT6D2_3_4_ISAMAP_RELEASE_REV 15;
BA_ "GenSigStartValue" SG_ 1746 LCT6D2_2_0_ISAMAP_RELEASE_YEAR 255;
BA_ "GenSigStartValue" SG_ 845 ADAS34D_15_0_CSTM_SNR_CLEAR 1;
BA_ "GenSigStartValue" SG_ 845 ADAS34D_15_1_CSTM_RAB 1;
BA_ "GenSigStartValue" SG_ 845 ADAS34D_15_2_CSTM_RAB_PED 1;
BA_ "GenSigStartValue" SG_ 845 ADAS34D_5_2_TORQUE_LIM_VAL 63;
BA_ "GenSigStartValue" SG_ 844 ADAS34C_10_0_SLWF_OFFSET_OV50 10;
BA_ "GenSigStartValue" SG_ 844 ADAS34C_9_0_SLWF_OFFSET_U50 10;
BA_ "GenSigStartValue" SG_ 844 ADAS34C_8_0_ISA_IACC_OFFSET_OV50 10;
BA_ "GenSigStartValue" SG_ 844 ADAS34C_7_0_ISA_IACC_OFFSET_U50 10;
BA_ "GenSigStartValue" SG_ 843 ADAS34B_20_6_LDW_SOUND_ON_OFF_SW 1;
BA_ "GenSigStartValue" SG_ 843 ADAS34B_9_0_CSTM_P_CR 1;
BA_ "GenSigStartValue" SG_ 843 ADAS34B_9_1_FCW_SOUND_ON_OFF_SW 1;
BA_ "GenSigSendType" SG_ 1098 EVCC44A_3_0_PNC_CC_SAVE_RES_RSLT 4;
BA_ "GenSigStartValue" SG_ 1096 EVCC448_4_0_EVSECONFPAYOPT 1;
BA_ "GenSigSendType" SG_ 1095 EVCC447_3_4_CHGWAKE 3;
BA_ "GenSigSendType" SG_ 1095 EVCC447_3_0_CHGMODE 3;
BA_ "GenSigSendType" SG_ 1093 EVCC445_3_0_DISPREQ 3;
BA_ "GenSigStartValue" SG_ 1551 ENM60F_26_0_ACCMHVPWR_LC 131070;
BA_ "GenSigStartValue" SG_ 1551 ENM60F_23_7_ACCMHVPWR_TRIPB 131070;
BA_ "GenSigStartValue" SG_ 1551 ENM60F_21_6_ACCMHVPWR_TRIPA 131070;
BA_ "GenSigStartValue" SG_ 1551 ENM60F_20_4_OTRACCMHVRATE_LC 1022;
BA_ "GenSigStartValue" SG_ 1551 ENM60F_19_2_ACOUTACCMRATE_LC 1022;
BA_ "GenSigStartValue" SG_ 1551 ENM60F_18_0_BADJACCMHVRATE_LC 1022;
BA_ "GenSigStartValue" SG_ 1551 ENM60F_16_6_ACNACCMHVRATE_LC 1022;
BA_ "GenSigStartValue" SG_ 1551 ENM60F_15_4_MOTACCMHVRATE_LC 1022;
BA_ "GenSigStartValue" SG_ 1551 ENM60F_14_2_OTRACCMHVRATE_TRIPB 1022;
BA_ "GenSigStartValue" SG_ 1551 ENM60F_13_0_ACOUTACCMRATE_TRIPB 1022;
BA_ "GenSigStartValue" SG_ 1551 ENM60F_11_6_BADJACCMHVRATE_TRIPB 1022;
BA_ "GenSigStartValue" SG_ 1551 ENM60F_10_4_ACNACCMHVRATE_TRIPB 1022;
BA_ "GenSigStartValue" SG_ 1551 ENM60F_9_2_MOTACCMHVRATE_TRIPB 1022;
BA_ "GenSigStartValue" SG_ 1551 ENM60F_8_0_OTRACCMHVRATE_TRIPA 1022;
BA_ "GenSigStartValue" SG_ 1551 ENM60F_6_6_ACOUTACCMRATE_TRIPA 1022;
BA_ "GenSigStartValue" SG_ 1551 ENM60F_5_4_BADJACCMHVRATE_TRIPA 1022;
BA_ "GenSigStartValue" SG_ 1551 ENM60F_4_2_ACNACCMHVRATE_TRIPA 1022;
BA_ "GenSigStartValue" SG_ 1551 ENM60F_3_0_MOTACCMHVRATE_TRIPA 1022;
BA_ "GenSigStartValue" SG_ 1548 ENM60C_26_0_HVBWIN 1023;
BA_ "GenSigStartValue" SG_ 1548 ENM60C_24_6_THMADJPRDWIN 1023;
BA_ "GenSigStartValue" SG_ 1548 ENM60C_23_3_ACNOFF_DRVRANG 1022;
BA_ "GenSigStartValue" SG_ 1548 ENM60C_22_0_ACNON_DRVRANG 1022;
BA_ "GenSigStartValue" SG_ 1548 ENM60C_19_1_VEHPWREFF_TRIPB 2046;
BA_ "GenSigStartValue" SG_ 1548 ENM60C_17_6_VEHPWREFF_TRIPA 2046;
BA_ "GenSigStartValue" SG_ 1548 ENM60C_16_3_VEHPWREFF_ODO 2046;
BA_ "GenSigStartValue" SG_ 1548 ENM60C_15_0_VEHPWREFF 2046;
BA_ "GenSigStartValue" SG_ 1548 ENM60C_13_3_VEHPRDDIS_JDG 2;
BA_ "GenSigStartValue" SG_ 1548 ENM60C_12_0_HVBTEMP 130;
BA_ "GenSigStartValue" SG_ 1548 ENM60C_11_0_HVBTGTTEMP 130;
BA_ "GenSigStartValue" SG_ 1548 ENM60C_9_0_ENHCHGTIM 255;
BA_ "GenSigStartValue" SG_ 1548 ENM60C_8_0_THMADJTIM_PRCNSW 255;
BA_ "GenSigStartValue" SG_ 1548 ENM60C_7_0_THMADJPRDSOC 255;
BA_ "GenSigStartValue" SG_ 1548 ENM60C_6_0_HVBTHMADJPWR 255;
BA_ "GenSigStartValue" SG_ 1548 ENM60C_5_0_THMADJTIM_PFOMD 255;
BA_ "GenSigStartValue" SG_ 1548 ENM60C_4_0_HVBTHMADJTIM 255;
BA_ "GenSigStartValue" SG_ 857 THM359_2_0_HVBINLTEMP 130;
BA_ "GenSigSendType" SG_ 1485 CHR5CD_27_0_EVSE_ID_7_CHR 4;
BA_ "GenSigSendType" SG_ 1485 CHR5CD_23_0_EVSE_ID_6_CHR 4;
BA_ "GenSigSendType" SG_ 1485 CHR5CD_19_0_EVSE_ID_5_CHR 4;
BA_ "GenSigSendType" SG_ 1485 CHR5CD_15_0_EVSE_ID_4_CHR 4;
BA_ "GenSigSendType" SG_ 1485 CHR5CD_11_0_EVSE_ID_3_CHR 4;
BA_ "GenSigSendType" SG_ 1485 CHR5CD_7_0_EVSE_ID_2_CHR 4;
BA_ "GenSigSendType" SG_ 1485 CHR5CD_3_0_EVSE_ID_1_CHR 4;
BA_ "GenSigSendType" SG_ 1485 CHR5CD_2_0_E2E_COUNTER 4;
BA_ "GenSigSendType" SG_ 1485 CHR5CD_0_0_E2E_CRC 4;
BA_ "GenSigSendType" SG_ 1111 CHR457_12_6_ENERGY_CHARGED_DISP 3;
BA_ "GenSigSendType" SG_ 1111 CHR457_11_7_DLTSOCCALC_FIN 3;
BA_ "GenSigSendType" SG_ 1111 CHR457_11_0_DLTSOCCALC_STRT 3;
BA_ "GenSigSendType" SG_ 1111 CHR457_10_6_STLMT_TYPE 3;
BA_ "GenSigSendType" SG_ 1111 CHR457_10_4_ACDC_INFO 3;
BA_ "GenSigSendType" SG_ 1111 CHR457_9_0_CHGTIM 3;
BA_ "GenSigSendType" SG_ 1111 CHR457_6_4_DCPWRSUPSTOP_DISP 3;
BA_ "GenSigSendType" SG_ 1111 CHR457_6_0_DCPWRSUPSTRT_DISP 3;
BA_ "GenSigSendType" SG_ 1111 CHR457_5_0_CHGSTRTNTCE_DISP 3;
BA_ "GenSigSendType" SG_ 1111 CHR457_5_4_CHGENDNTCE_DISP 3;
BA_ "GenSigSendType" SG_ 1111 CHR457_4_0_FEDSTPRSN_DISP 3;
BA_ "GenSigSendType" SG_ 1111 CHR457_3_0_CHGSTPRSN_DISP 3;
BA_ "GenSigStartValue" SG_ 1109 CHR455_28_4_VEH_CHGPWRUPLMT 131070;
BA_ "GenSigStartValue" SG_ 1109 CHR455_25_0_CHGVLT_DISP 1022;
BA_ "GenSigStartValue" SG_ 1109 CHR455_23_0_CHGCUR_DISP 65534;
BA_ "GenSigStartValue" SG_ 1109 CHR455_19_2_DLTSOCCALC_FIN 126;
BA_ "GenSigStartValue" SG_ 1109 CHR455_18_3_DLTSOCCALC_STRT 126;
BA_ "GenSigStartValue" SG_ 1109 CHR455_16_6_EVSEOUTPWR 1022;
BA_ "GenSigStartValue" SG_ 1109 CHR455_13_3_CHG_FINTIM 137217726;
BA_ "GenSigStartValue" SG_ 1109 CHR455_10_7_DCPWRSUP_PWR_DISP 254;
BA_ "GenSigStartValue" SG_ 1109 CHR455_7_1_DCPWRSUP_ADMTIM 16382;
BA_ "GenSigStartValue" SG_ 1109 CHR455_6_1_CHGSTT 254;
BA_ "GenSigStartValue" SG_ 1109 CHR455_4_6_DCCHG_PWRUPLMT 14;
BA_ "GenSigStartValue" SG_ 1109 CHR455_4_2_ACCHG_CURUPLMT 14;
BA_ "GenSigStartValue" SG_ 1109 CHR455_3_3_CHG_HILMT 126;
VAL_ 552 RDR228_7_0_EYE_TIMEOUT_ERROR_FLG 1 "EYE Timeout or Error detect" 0 "Normal" ;
VAL_ 552 RDR228_7_1_BLOCKAGE_FORMING_2 1 "Blocakge2" 0 "Normal" ;
VAL_ 552 RDR228_7_2_WARN_LCA_R_1ST 1 "ON" 0 "OFF" ;
VAL_ 552 RDR228_7_3_WARN_LCA_L_1ST 1 "ON" 0 "OFF" ;
VAL_ 552 RDR228_7_4_WARN_LCA_R_2ND 1 "ON" 0 "OFF" ;
VAL_ 552 RDR228_7_5_WARN_LCA_L_2ND 1 "ON" 0 "OFF" ;
VAL_ 552 RDR228_7_6_WARN_RCTA_R 1 "ON" 0 "OFF" ;
VAL_ 552 RDR228_7_7_WARN_RCTA_L 1 "ON" 0 "OFF" ;
VAL_ 552 RDR228_6_0_WARN_BSD_R_1ST 1 "ON" 0 "OFF" ;
VAL_ 552 RDR228_6_1_WARN_BSD_L_1ST 1 "ON" 0 "OFF" ;
VAL_ 552 RDR228_6_2_WARN_BSD_R_2ND 1 "ON" 0 "OFF" ;
VAL_ 552 RDR228_6_3_WARN_BSD_L_2ND 1 "ON" 0 "OFF" ;
VAL_ 552 RDR228_6_5_BLOCKAGE_STS 5 "INVALID" 4 "BLIND" 3 "HIGH" 2 "MID" 1 "LOW" 0 "NONE" ;
VAL_ 552 RDR228_5_0_BSD_R_E 1 "ON" 0 "OFF" ;
VAL_ 552 RDR228_5_1_BSD_L_E 1 "ON" 0 "OFF" ;
VAL_ 552 RDR228_5_2_LCA_R_E 1 "ON" 0 "OFF" ;
VAL_ 552 RDR228_5_3_LCA_L_E 1 "ON" 0 "OFF" ;
VAL_ 552 RDR228_5_4_BSD_R_A 1 "ON" 0 "OFF" ;
VAL_ 552 RDR228_5_5_BSD_L_A 1 "ON" 0 "OFF" ;
VAL_ 552 RDR228_5_6_LCA_R_A 1 "ON" 0 "OFF" ;
VAL_ 552 RDR228_5_7_LCA_L_A 1 "ON" 0 "OFF" ;
VAL_ 552 RDR228_4_0_DOW_ACTIVELAMP 1 "ON" 0 "OFF" ;
VAL_ 552 RDR228_4_1_WARN_DOW_1ST_R 1 "ON" 0 "OFF" ;
VAL_ 552 RDR228_4_2_WARN_DOW_1ST_L 1 "ON" 0 "OFF" ;
VAL_ 552 RDR228_4_3_WARN_DOW_2ST_R 1 "ON" 0 "OFF" ;
VAL_ 552 RDR228_4_4_WARN_DOW_2ST_L 1 "ON" 0 "OFF" ;
VAL_ 552 RDR228_4_6_CSTM_STS_BSD_LCA_2ND 1 "ON" 0 "OFF" ;
VAL_ 552 RDR228_4_7_CSTM_STS_RCTA 1 "ON" 0 "OFF" ;
VAL_ 552 RDR228_3_0_WARN_BSD_LCA_R_2ND 1 "ON" 0 "OFF" ;
VAL_ 552 RDR228_3_1_WARN_BSD_LCA_L_2ND 1 "ON" 0 "OFF" ;
VAL_ 552 RDR228_3_2_CSTM_STS_DOW 1 "ON" 0 "OFF" ;
VAL_ 552 RDR228_3_3_CSTM_STS_DOW_SFT_POS 1 "ONLY_P" 0 "OTHER_THAN_R" ;
VAL_ 552 RDR228_3_6_CSTM_DSP_BSD_LCA_2ND 1 "ON" 0 "OFF" ;
VAL_ 552 RDR228_3_7_CSTM_DSP_RCTA 1 "ON" 0 "OFF" ;
VAL_ 552 RDR228_2_0_CSTM_DSP_DOW 1 "ON" 0 "OFF" ;
VAL_ 552 RDR228_2_1_EYE_LOCAL_BUS1_FAIL 1 "EYE LOCAL BUS1 FAIL" 0 "NORMAL" ;
VAL_ 552 RDR228_2_2_CSTM_DSP_DOW_SFT_POS 1 "ON" 0 "OFF" ;
VAL_ 552 RDR228_2_3_ELK_STOP_REQ_FLG 1 "ELK stop request flag" 0 "NORMAL" ;
VAL_ 552 RDR228_2_4_FAIL_RDRSYS 1 "FAIL" 0 "NORMAL" ;
VAL_ 552 RDR228_2_5_STOP_RDRSYS 1 "HALT" 0 "NORMAL" ;
VAL_ 552 RDR228_2_6_ON_OFF_RDRSYS 1 "ON" 0 "OFF" ;
VAL_ 552 RDR228_2_7_BLOCKAGE_FORMING 1 "BLOCKAGE" 0 "NORMAL" ;
VAL_ 552 RDR228_1_4_BATT_OFF_CAUSE 1 "OFF required" 0 "ON required" ;
VAL_ 552 RDR228_1_5_CSTM_GLO_1 1 "ON" 0 "OFF" ;
VAL_ 552 RDR228_1_6_CSTM_GLO_3 1 "ON" 0 "OFF" ;
VAL_ 552 RDR228_1_7_CSTM_GLO_2 1 "ON" 0 "OFF" ;
VAL_ 1606 EYE646_1_4_DEADMAN_NOTIFICATION 3 "予備" 2 "予備" 1 "発信要求" 0 "初期値" ;
VAL_ 965 EYE3C5_7_0_GSR_AEBS_FUNC_INFO 1 "Requirement" 0 "No requirement" ;
VAL_ 965 EYE3C5_7_1_CSTM_CRV_ADJUST 3 "HARD" 2 "NORMAL" 1 "SOFT" 0 "OFF" ;
VAL_ 965 EYE3C5_7_3_BRAKE_HAPTIC_CURR 3 "BUZZER OFF/BREAK OFF" 2 "BUZZER OFF/BREAK ON" 1 "BUZZER ON/BREAK OFF" 0 "BUZZER ON/BREAK ON" ;
VAL_ 965 EYE3C5_7_5_SAFETY_MODE_FUNC_INFO 1 "Requirement" 0 "No requirement" ;
VAL_ 965 EYE3C5_7_6_SAFETY_MODE_CURR 1 "enable" 0 "disable" ;
VAL_ 965 EYE3C5_7_7_GSR_DDAW_FUNC_INFO 1 "Requirement" 0 "No requirement" ;
VAL_ 965 EYE3C5_6_0_IND_SAFETY_MODE 1 "TURN_ON" 0 "TURN_OFF" ;
VAL_ 965 EYE3C5_6_1_ALC_ACTIVE_L 1 "TURN_ON" 0 "TURN_OFF" ;
VAL_ 965 EYE3C5_6_2_FLASHING_IND_SAFETY 1 "Blinking" 0 "Nomally indicate" ;
VAL_ 965 EYE3C5_6_3_OVERTAKE_FUNC_INFO 1 "Requirement" 0 "No requirement" ;
VAL_ 965 EYE3C5_6_4_CRV_ADJUST_FUNC_INFO 1 "Requirement" 0 "No requirement" ;
VAL_ 965 EYE3C5_6_5_STRG_TOUCHSENSOR_WRNG 1 "TURN_ON" 0 "TURN_OFF" ;
VAL_ 965 EYE3C5_6_6_ALC_ACTIVE_R 1 "TURN_ON" 0 "TURN_OFF" ;
VAL_ 965 EYE3C5_6_7_CSTM_GSR_ISA 1 "Requirement" 0 "No requirement" ;
VAL_ 965 EYE3C5_5_0_LANE_COLOR_R 3 "BLUE" 2 "No_Definition" 1 "GRAY" 0 "OFF" ;
VAL_ 965 EYE3C5_5_2_LINE_LANE_R 3 "No_Definition" 2 "WHITE" 1 "GRAY" 0 "OFF" ;
VAL_ 965 EYE3C5_5_4_LANE_COLOR_L 3 "BLUE" 2 "No_Definition" 1 "GRAY" 0 "OFF" ;
VAL_ 965 EYE3C5_5_6_LINE_LANE_L 3 "No_Definition" 2 "WHITE" 1 "GRAY" 0 "OFF" ;
VAL_ 965 EYE3C5_4_4_ROAD_SHAPE_DIRECTION 1 "LEFT" 0 "RIGHT" ;
VAL_ 965 EYE3C5_4_5_CSTM_GSR_ELKS 1 "Requirement" 0 "No requirement" ;
VAL_ 965 EYE3C5_4_6_MY_WAY_COLOR 3 "BLUE" 2 "No_Definition" 1 "GRAY" 0 "OFF" ;
VAL_ 965 EYE3C5_3_0_AD_DRV_ICON 3 "No_Definition" 2 "BLUE" 1 "WHITE" 0 "TURN_OFF" ;
VAL_ 965 EYE3C5_3_2_AUTO_HANDLE_ICON 3 "No_Definition" 2 "BLINK" 1 "TURN_ON" 0 "TURN_OFF" ;
VAL_ 965 EYE3C5_3_4_WITH_HANDS_ICON 1 "ON" 0 "OFF" ;
VAL_ 965 EYE3C5_3_5_STRG_HAPTIC_WRNG 1 "TURN_ON" 0 "TURN_OFF" ;
VAL_ 965 EYE3C5_3_6_BRK_HPTC_FUNC_INFO 1 "Requirement" 0 "No requirement" ;
VAL_ 965 EYE3C5_3_7_SPECIAL_DISP_INFO 1 "Requirement" 0 "No requirement" ;
VAL_ 965 EYE3C5_2_0_SLOWDWN_CURVE_ICON 7 "No_Definition" 6 "BLINK③" 5 "TURN_ON③" 4 "BLINK②" 3 "TURN_ON②" 2 "BLINK①" 1 "TURN_ON①" 0 "TURN_OFF" ;
VAL_ 965 EYE3C5_2_3_FLASHING_IND 1 "BLINK" 0 "TURN_ON" ;
VAL_ 965 EYE3C5_2_4_ATTENTION_TOLLGATE 3 "No_Definition" 2 "BLINK" 1 "TURN_ON" 0 "TURN_OFF" ;
VAL_ 965 EYE3C5_2_6_MAPLOCATOR_IND 3 "No_Definition" 2 "FAIL_ON" 1 "TURN_ON" 0 "TURN_OFF" ;
VAL_ 965 EYE3C5_1_4_ISA_FAIL_IND 1 "TURN_ON" 0 "TURN_OFF" ;
VAL_ 965 EYE3C5_1_5_SLWF_OFF_IND 1 "TURN_ON" 0 "TURN_OFF" ;
VAL_ 965 EYE3C5_1_6_CSTM_SLWF_SET 1 "ON" 0 "OFF" ;
VAL_ 965 EYE3C5_1_7_CSTM_TSR_SOUND_SET 1 "ON" 0 "OFF" ;
VAL_ 964 EYE3C4_7_0_PCR_FAIL_OFF_IND 3 "No_Definition" 2 "FAIL" 1 "HALT/Customize OFF" 0 "NORMAL" ;
VAL_ 964 EYE3C4_7_2_AES_FAIL_OFF_IND 3 "No_Definition" 2 "FAIL" 1 "HALT/Customize OFF" 0 "NORMAL" ;
VAL_ 964 EYE3C4_7_4_LDP_FAIL_OFF_IND 3 "No_Definition" 2 "FAIL" 1 "HALT/Customize OFF" 0 "NORMAL" ;
VAL_ 964 EYE3C4_7_6_ELK_FAIL_OFF_IND 3 "No_Definition" 2 "FAIL" 1 "HALT/Customize OFF" 0 "NORMAL" ;
VAL_ 964 EYE3C4_6_0_MCAM_SYS_FAIL_HALT 3 "No_Definition" 2 "FAIL" 1 "HALT" 0 "NORMAL" ;
VAL_ 964 EYE3C4_6_2_MCAM_FUNC_INFO 1 "ON" 0 "OFF" ;
VAL_ 964 EYE3C4_6_3_EYE_DRV_ACTION_REQ 7 "No_Definition" 6 "No_Definition" 5 "No_Definition" 4 "restriction2" 3 "restriction1" 2 "permission" 1 "Prohibition" 0 "No Requirement" ;
VAL_ 964 EYE3C4_6_6_LDW_SND_OFF_FAIL_IND 3 "No_Definition" 2 "FAIL" 1 "OFF" 0 "TURN OFF" ;
VAL_ 964 EYE3C4_5_0_EAM_GREEN 3 "PATTERN3" 2 "PATTERN2" 1 "PATTERN1" 0 "TURN_OFF" ;
VAL_ 964 EYE3C4_5_2_EAM_BLUE 3 "PATTERN3" 2 "PATTERN2" 1 "PATTERN1" 0 "TURN_OFF" ;
VAL_ 964 EYE3C4_5_4_EAM_GREEN_2 3 "No_Definition" 2 "BLINK" 1 "ON" 0 "OFF" ;
VAL_ 964 EYE3C4_5_6_FCW_SND_OFF_FAIL_IND 3 "No_Definition" 2 "FAIL" 1 "OFF" 0 "TURN OFF" ;
VAL_ 964 EYE3C4_4_0_EAM_YELLOW 15 "No Definition" 14 "No_Definition" 13 "No_Definition" 12 "No_Definition" 11 "No_Definition" 10 "No_Definition" 9 "No_Definition" 8 "No_Definition" 7 "PATTERN⑦" 6 "PATTERN⑥" 5 "PATTERN⑤" 4 "PATTERN④" 3 "PATTERN③" 2 "PATTERN②" 1 "PATTERN①" 0 "TURN_OFF" ;
VAL_ 964 EYE3C4_4_4_EAM_RED 15 "No Definition" 14 "No_Definition" 13 "No_Definition" 12 "No_Definition" 11 "No_Definition" 10 "No_Definition" 9 "No_Definition" 8 "No_Definition" 7 "PATTERN⑦" 6 "PATTERN⑥" 5 "PATTERN⑤" 4 "PATTERN④" 3 "PATTERN③" 2 "PATTERN②" 1 "PATTERN①" 0 "TURN_OFF" ;
VAL_ 964 EYE3C4_3_0_CODE_NO_BUZZER 255 "Pattern255" 90 "Pattern90" 89 "Pattern89" 88 "Pattern88" 87 "Pattern87" 86 "Pattern86" 84 "Pattern84" 83 "Pattern83" 82 "Pattern82" 81 "Pattern81" 80 "Pattern80" 79 "Pattern79" 78 "Pattern78" 77 "Pattern77" 76 "Pattern76" 75 "Pattern75" 74 "Pattern74" 73 "Pattern73" 72 "Pattern72" 71 "Pattern71" 70 "Pattern70" 69 "Pattern69" 68 "Pattern68" 67 "Pattern67" 66 "Pattern66" 65 "Pattern65" 64 "Pattern64" 63 "Pattern63" 62 "Pattern62" 61 "Pattern61" 60 "Pattern60" 59 "Pattern59" 49 "Pattern49" 48 "Pattern48" 47 "Pattern47" 46 "Pattern46" 45 "Pattern45" 44 "Pattern44" 43 "Pattern43" 42 "Pattern42" 41 "Pattern41" 40 "Pattern40" 39 "Pattern39" 38 "Pattern38" 37 "Pattern37" 36 "Pattern36" 35 "Pattern35" 34 "Pattern34" 33 "Pattern33" 32 "Pattern32" 31 "Pattern31" 30 "Pattern30" 29 "Pattern29" 28 "Pattern28" 27 "Pattern27" 26 "Pattern26" 25 "Pattern25" 24 "Pattern24" 23 "Pattern23" 22 "Pattern22" 21 "Pattern21" 20 "Pattern20" 19 "Pattern19" 18 "Pattern18" 17 "Pattern17" 16 "Pattern16" 15 "Pattern15" 14 "Pattern14" 13 "Pattern13" 12 "Pattern12" 11 "Pattern11" 10 "Pattern10" 9 "Pattern9" 8 "Pattern8" 7 "Pattern7" 6 "Pattern6" 5 "Pattern5" 4 "Pattern4" 3 "Pattern3" 2 "Pattern2" 1 "Pattern1" 0 "OFF" ;
VAL_ 964 EYE3C4_2_0_CODE_WARN 255 "Pattern255" 166 "Pattern166" 165 "Pattern165" 164 "Pattern164" 163 "Pattern163" 162 "Pattern162" 161 "Pattern161" 160 "Pattern160" 159 "Pattern159" 158 "Pattern158" 157 "Pattern157" 156 "Pattern156" 155 "Pattern155" 154 "Pattern154" 153 "Pattern153" 152 "Pattern152" 151 "Pattern151" 150 "Pattern150" 149 "Pattern149" 148 "Pattern148" 147 "Pattern147" 146 "Pattern146" 145 "Pattern145" 144 "Pattern144" 90 "Pattern90" 89 "Pattern89" 88 "Pattern88" 87 "Pattern87" 86 "Pattern86" 85 "Pattern85" 84 "Pattern84" 83 "Pattern83" 82 "Pattern82" 81 "Pattern81" 80 "Pattern80" 79 "Pattern79" 78 "Pattern78" 77 "Pattern77" 76 "Pattern76" 75 "Pattern75" 74 "Pattern74" 73 "Pattern73" 72 "Pattern72" 71 "Pattern71" 70 "Pattern70" 69 "Pattern69" 68 "Pattern68" 67 "Pattern67" 66 "Pattern66" 65 "Pattern65" 64 "Pattern64" 63 "Pattern63" 62 "Pattern62" 61 "Pattern61" 60 "Pattern60" 59 "Pattern59" 58 "Pattern58" 57 "Pattern57" 56 "Pattern56" 55 "Pattern55" 54 "Pattern54" 53 "Pattern53" 52 "Pattern52" 51 "Pattern51" 50 "Pattern50" 49 "Pattern49" 48 "Pattern48" 47 "Pattern47" 46 "Pattern46" 45 "Pattern45" 44 "Pattern44" 43 "Pattern43" 42 "Pattern42" 41 "Pattern41" 40 "Pattern40" 39 "Pattern39" 38 "Pattern38" 37 "Pattern37" 36 "Pattern36" 35 "Pattern35" 34 "Pattern34" 33 "Pattern33" 32 "Pattern32" 31 "Pattern31" 30 "Pattern30" 29 "Pattern29" 28 "Pattern28" 27 "Pattern27" 26 "Pattern26" 25 "Pattern25" 24 "Pattern24" 23 "Pattern23" 22 "Pattern22" 21 "Pattern21" 20 "Pattern20" 19 "Pattern19" 18 "Pattern18" 17 "Pattern17" 16 "Pattern16" 15 "Pattern15" 14 "Pattern14" 13 "Pattern13" 12 "Pattern12" 11 "Pattern11" 10 "Pattern10" 9 "Pattern9" 8 "Pattern8" 7 "Pattern7" 6 "Pattern6" 5 "Pattern5" 4 "Pattern4" 3 "Pattern3" 2 "Pattern2" 1 "Pattern1" 0 "OFF" ;
VAL_ 964 EYE3C4_1_5_SNR_DRV_ACTION_REQ 7 "No_Definition" 6 "No_Definition" 5 "No_Definition" 4 "Restriction2" 3 "Restriction1" 2 "Permission" 1 "Prohibition" 0 "No Requirement" ;
VAL_ 805 EYE325_6_5_SONAR_DISP_INT 1 "DISP_INT_ON" 0 "DISP_INT_OFF" ;
VAL_ 805 EYE325_5_0_SONAR_R_L_CORNER_4LVL 7 "No_Definition" 6 "No_Definition" 5 "No_Definition" 4 "MOST_NEAR" 3 "NEAR" 2 "MIDDLE" 1 "FAR" 0 "CLEAR" ;
VAL_ 805 EYE325_5_3_SONAR_R_R_CORNER_4LVL 7 "No_Definition" 6 "No_Definition" 5 "No_Definition" 4 "MOST_NEAR" 3 "NEAR" 2 "MIDDLE" 1 "FAR" 0 "CLEAR" ;
VAL_ 805 EYE325_4_0_SONAR_R_CENTER 7 "No_Definition" 6 "No_Definition" 5 "No_Definition" 4 "MOST_NEAR" 3 "NEAR" 2 "MIDDLE" 1 "FAR" 0 "CLEAR" ;
VAL_ 805 EYE325_4_3_SONAR_LEVEL 7 "No_Definition" 6 "FAR" 5 "FIRST_BRAKE" 4 "SECOND_BRAKE" 3 "MOST_NEAR" 2 "NEAR" 1 "MIDDLE" 0 "OFF" ;
VAL_ 805 EYE325_4_6_RAB_WARNING 3 "RAB_Interrupt_3" 2 "RAB_Interrupt_2" 1 "RAB_Interrupt_1" 0 "OFF" ;
VAL_ 805 EYE325_3_0_SONAR_R_L_CORNER 3 "NEAR" 2 "MIDDLE" 1 "FAR" 0 "CLEAR" ;
VAL_ 805 EYE325_3_2_SONAR_R_R_CORNER 3 "NEAR" 2 "MIDDLE" 1 "FAR" 0 "CLEAR" ;
VAL_ 805 EYE325_3_4_SONAR_R_L_SIDE 3 "NEAR" 2 "MIDDLE" 1 "FAR" 0 "CLEAR" ;
VAL_ 805 EYE325_3_6_SONAR_R_R_SIDE 3 "NEAR" 2 "MIDDLE" 1 "FAR" 0 "CLEAR" ;
VAL_ 805 EYE325_2_0_RAB_OFF 1 "RAB_OFF" 0 "RAB_ON" ;
VAL_ 805 EYE325_2_1_SONAR_OFF 1 "SONAR_OFF" 0 "SONAR_ON" ;
VAL_ 805 EYE325_2_2_SONAR_SYS_HALT 3 "No_Definition" 2 "HALT_2" 1 "HALT_1" 0 "NO_HALT" ;
VAL_ 805 EYE325_2_4_SONAR_SYS_FAIL 3 "No_Definition" 2 "FAIL_2" 1 "FAIL_1" 0 "NO_FAIL" ;
VAL_ 805 EYE325_2_6_RAB_DISABLE 1 "ON" 0 "OFF" ;
VAL_ 805 EYE325_2_7_SONAR_DISABLE 1 "ON" 0 "OFF" ;
VAL_ 805 EYE325_1_4_CSTM_RAB_SET 1 "ON" 0 "OFF" ;
VAL_ 805 EYE325_1_5_CSTM_CLR_SNR_SET 1 "ON" 0 "OFF" ;
VAL_ 805 EYE325_1_6_RAB 1 "ON" 0 "OFF" ;
VAL_ 805 EYE325_1_7_SONAR_NO_DISP 1 "ON" 0 "OFF" ;
VAL_ 803 EYE323_7_5_SLIF_FUNC_INFO 1 "Requirement" 0 "No requirement" ;
VAL_ 803 EYE323_7_6_ISA_FUNC_INFO 1 "Requirement" 0 "No requirement" ;
VAL_ 803 EYE323_7_7_ISA_CUSTOMIZE_CURR 1 "ISA enable" 0 "ISA disable" ;
VAL_ 803 EYE323_6_0_LDW_OFFSW_INFO 1 "requirement" 0 "No requirement" ;
VAL_ 803 EYE323_6_1_LDW_ON_OFF_SET 1 "enable" 0 "disable" ;
VAL_ 803 EYE323_6_2_CSTM_DDAW_WARN_SET 1 "ON" 0 "OFF" ;
VAL_ 803 EYE323_6_3_IACC_FUNC_INFO 1 "Requirement" 0 "No requirement" ;
VAL_ 803 EYE323_6_5_CSTM_LDW_TIMING_SET 1 "LATE" 0 "EARLY" ;
VAL_ 803 EYE323_6_6_CSTM_LDW_TIMING 1 "Requirement" 0 "No requirement" ;
VAL_ 803 EYE323_6_7_SLOWDOWNL_FUNC_INFO 1 "Requirement" 0 "No requirement" ;
VAL_ 803 EYE323_5_0_CNG_GRN_CONT_CURR 1 "enable" 0 "disable" ;
VAL_ 803 EYE323_5_1_TRAFFIC_FUNC_INFO 1 "Requirement" 0 "No requirement" ;
VAL_ 803 EYE323_5_2_FCW_OFFSW_INFO 1 "requirement" 0 "No requirement" ;
VAL_ 803 EYE323_5_3_FCW_ON_OFF_SET 1 "enable" 0 "disable" ;
VAL_ 803 EYE323_5_4_WARNING_SEL_CURR 1 "Vibration" 0 "Sound" ;
VAL_ 803 EYE323_5_5_HAPT_FUNC_INFO 1 "Requirement" 0 "No requirement" ;
VAL_ 803 EYE323_5_6_TOLLGATE_CONT_CURR 1 "enable" 0 "disable" ;
VAL_ 803 EYE323_5_7_CURVE_CONT_CURR 1 "enable" 0 "disable" ;
VAL_ 803 EYE323_4_0_FCTB_ICON_L 3 "No_Definition" 2 "BLINK" 1 "TURN_ON" 0 "TURN_OFF" ;
VAL_ 803 EYE323_4_2_FCTB_ICON_R 3 "No_Definition" 2 "BLINK" 1 "TURN_ON" 0 "TURN_OFF" ;
VAL_ 803 EYE323_4_4_FCW_CONT_CURR 3 "OFF" 2 "FAR" 1 "NEAR" 0 "ON/STD." ;
VAL_ 803 EYE323_4_6_FCW_DISPLAY_SEL 3 "FULL SELECT" 2 "ON/OFF SELECT" 1 "Distance SELECT" 0 "TURN OFF" ;
VAL_ 803 EYE323_3_0_AES_FUNC_INFO 1 "Requirement" 0 "No requirement" ;
VAL_ 803 EYE323_3_1_CSTM_TSR_NO_ENTRY_SET 1 "ON" 0 "OFF" ;
VAL_ 803 EYE323_3_2_CSTM_TSR_STOP_SET 1 "ON" 0 "OFF" ;
VAL_ 803 EYE323_3_3_CSTM_TSR_GIVE_WAY_SET 1 "ON" 0 "OFF" ;
VAL_ 803 EYE323_3_4_WILDERNESS 1 "WILDERNESS" 0 "NOT_WILDERNESS" ;
VAL_ 803 EYE323_3_5_AES_OFF 1 "TURN_ON" 0 "TURN_OFF" ;
VAL_ 803 EYE323_3_6_FCTB_IND 3 "No_Definition" 2 "FAIL_ON" 1 "TURN_ON" 0 "TURN_OFF" ;
VAL_ 803 EYE323_2_0_CSTM_LDW_ALK_B 3 "ALK-B ON /LDW ON" 2 "ALK-B ON /LDW OFF" 1 "ALK-B OFF/LDW ON" 0 "ALK-B OFF/LDW OFF" ;
VAL_ 803 EYE323_2_2_CSTM_P_CR 1 "ON" 0 "OFF" ;
VAL_ 803 EYE323_2_3_SLOWDOWN_FUNC_INFO2 1 "Requirement" 0 "No requirement" ;
VAL_ 803 EYE323_2_4_CID_CODE_WARN 15 "Drowsiness attention" 14 "Eyes on request(3rd/4th)" 13 "Eyes on request(2nd)" 12 "MRM Interruption Vehicle" 11 "MRM Interruption Steering" 10 "MRM Interruption Lane change" 9 "MRM Stop" 8 "Handle steering" 7 "MRM Lane change Left" 6 "MRM Lane change Right" 5 "MRM Road shoulder Evacuation" 4 "B1 no-opr. cancel alarm" 3 "B1 no-opr. warning(long)" 2 "MRM Operation Notice" 1 "PreCrashBreak(1st)/Brake incr. alarm" 0 "No alarm " ;
VAL_ 803 EYE323_1_4_DISP_FOLLOW_FORWARD 1 "ON" 0 "OFF" ;
VAL_ 803 EYE323_1_5_KEEP_LINE_SENTER_ACT 1 "ON" 0 "OFF" ;
VAL_ 803 EYE323_1_6_DDAW_FAIL_OFF 3 "No_Definition" 2 "OFF" 1 "FAIL" 0 "TURN_OFF" ;
VAL_ 802 EYE322_7_0_CSTM_ACC_CONT_SET 3 "Lv.4" 2 "Lv.3" 1 "Lv.2" 0 "Lv.1" ;
VAL_ 802 EYE322_7_2_ELK_OFF_IND 1 "ON" 0 "OFF" ;
VAL_ 802 EYE322_7_3_LIGHT_EAM_YELLOW 3 "TURN_ON" 2 "BLINK_FAST" 1 "NONE" 0 "NONE" ;
VAL_ 802 EYE322_7_5_BROKEN_LINE_L 1 "DASHEDLINE" 0 "SOLIDLINE" ;
VAL_ 802 EYE322_7_6_TJA_ACTIVE 1 "ON" 0 "OFF" ;
VAL_ 802 EYE322_7_7_BROKEN_LINE_R 1 "DASHEDLINE" 0 "SOLIDLINE" ;
VAL_ 802 EYE322_6_0_CSTM_MIS_AT_START 3 "ON(20km/h)/(15mph)" 2 "ON(15km/h)/(10mph)" 1 "ON(10km/h)/(5mph)" 0 "OFF" ;
VAL_ 802 EYE322_6_2_CSTM_ALK_TJA_SET 1 "ON" 0 "OFF" ;
VAL_ 802 EYE322_6_3_CSTM_LANE_SET 1 "LEFT" 0 "RIGHT" ;
VAL_ 802 EYE322_6_4_LDP_OFF_IND 1 "TURN_ON" 0 "TURN_OFF" ;
VAL_ 802 EYE322_6_5_INDICATOR_MODE_L 3 "NONE" 2 "BLINK" 1 "TURN_ON" 0 "TURN_OFF" ;
VAL_ 802 EYE322_6_7_CSTM_ELK_SET 1 "ON" 0 "OFF" ;
VAL_ 802 EYE322_5_0_CSTM_MIS_AT_BACK 1 "ACTIVE" 0 "NON_ACTIVE" ;
VAL_ 802 EYE322_5_1_CSTM_ALK_TJA 1 "ACTIVE" 0 "NON_ACTIVE" ;
VAL_ 802 EYE322_5_2_CSTM_SAS 1 "ACTIVE" 0 "NON_ACTIVE" ;
VAL_ 802 EYE322_5_3_CSTM_HBA 1 "ACTIVE" 0 "NON_ACTIVE" ;
VAL_ 802 EYE322_5_4_CSTM_ACC_CONT 1 "ACTIVE" 0 "NON_ACTIVE" ;
VAL_ 802 EYE322_5_5_CSTM_LANE 1 "ACTIVE" 0 "NON_ACTIVE" ;
VAL_ 802 EYE322_5_6_LDW_SOUND_OFF_IND 1 "TURN_ON" 0 "TURN_OFF" ;
VAL_ 802 EYE322_5_7_CSTM_ELK_SET 1 "CSTM_ELK_ON" 0 "CSTM_ELK_OFF" ;
VAL_ 802 EYE322_4_0_CODE_WARN 31 "No_Definition" 30 "WARN_ALK_No_Steering_CONT(Only_Buzzer)" 29 "No_Definition" 28 "WARN_LKSA(No_Steering_CONT_Long)" 27 "ALK_Cancel(Only_Buzzer)" 26 "ACC_Cancel(Only_Buzzer)" 25 "Catch/Lost_Buzzer" 24 "Buzzer(No_Display)" 23 "No_Definition" 22 "No_Definition" 21 "No_Definition" 20 "Long Intervention(ALKB)" 19 "Blue Traffic Light Alert" 18 "WARN_ALK_System_Limit" 17 "No_Definition" 16 "WARN_ELK_Left" 15 "WARN_ELK_Right" 14 "Forward_Start_INFO" 13 "WARN_Lane_Sway" 12 "WARN_Lane_Departure(LDW/LDP) Left" 11 "WARN_Lane_Departure(LDW/LDP) Right" 10 "No_Definition" 9 "PreCrash_BRK(Stop_Warning)" 8 "WARN_Red_Signal" 7 "No_Definition" 6 "No_Definition" 5 "AfterPreCrash_BRK(Stopping)" 4 "AT_Accidental_Backward_Start(FMW)" 3 "AT_Accidental_Backward_Start(Speed_Limit_Warning)" 2 "PreCrash_BRK(First)" 1 "PreCrash_BRK(Second)" 0 "No_Warning" ;
VAL_ 802 EYE322_4_5_CSTM_GSR 1 "Requirement" 0 "No Requirement" ;
VAL_ 802 EYE322_3_0_LANE_L 3 "No_Definition" 2 "BLINK" 1 "TURN_ON" 0 "TURN_OFF" ;
VAL_ 802 EYE322_3_2_LANE_R 3 "No_Definition" 2 "BLINK" 1 "TURN_ON" 0 "TURN_OFF" ;
VAL_ 802 EYE322_3_4_LANE_L_COLOR 3 "AMBER" 2 "OTHER" 1 "WHITE" 0 "SUB" ;
VAL_ 802 EYE322_3_6_LANE_R_COLOR 3 "AMBER" 2 "OTHER" 1 "WHITE" 0 "SUB" ;
VAL_ 802 EYE322_2_0_FCW_OFF_IND 1 "TURN_ON" 0 "TURN_OFF" ;
VAL_ 802 EYE322_2_1_MOV_EYESIGHT_SCREEN 1 "DISP_EYE" 0 "OFF" ;
VAL_ 802 EYE322_2_2_ALK_ICON 3 "BLINK_GREEN" 2 "TURN_ON_GREEN" 1 "TURN_ON_WHITE" 0 "TURN_OFF" ;
VAL_ 802 EYE322_2_4_INDICATOR_CTRL_REQ 1 "ON" 0 "OFF" ;
VAL_ 802 EYE322_2_5_INDICATOR_MODE_R 3 "NONE" 2 "BLINK" 1 "TURN_ON" 0 "TURN_OFF" ;
VAL_ 802 EYE322_2_7_LIMITER_BACK_SPEED 1 "ON" 0 "OFF" ;
VAL_ 802 EYE322_1_4_CODE_NO_BUZZER 7 "WARN_LKSA(No_Steering_CONT_Long)" 6 "AfterPreCrash_BRK(Running)" 5 "Driver_Over_Ride" 4 "MT_Put_In_Gear_Request" 3 "MT_Shift_Down_Request" 2 "MT_Shift_Up_Request" 1 "WARN_LKSA(No_Steering_CONT)" 0 "No_Warning" ;
VAL_ 802 EYE322_1_7_DISTWARN_DMS 1 "ON" 0 "OFF" ;
VAL_ 801 EYE321_7_0_INFO_DIST_FORWARD 15 "75 ≦ x" 14 "70 ≦ x < 75" 13 "65 ≦ x < 70" 12 "60 ≦ x < 65" 11 "55 ≦ x < 60" 10 "50 ≦ x < 55" 9 "45 ≦ x < 50" 8 "40 ≦ x < 45" 7 "35 ≦ x < 40" 6 "30 ≦ x < 35" 5 "25 ≦ x < 30" 4 "20 ≦ x < 25" 3 "15 ≦ x < 20" 2 "10 ≦ x < 15" 1 "5 ≦ x < 10" 0 "0 ≦ x < 5" ;
VAL_ 801 EYE321_7_4_INFO_KEEP_STOP 1 "TURN_ON" 0 "TURN_OFF" ;
VAL_ 801 EYE321_7_5_INFO_READY 1 "TURN_ON" 0 "TURN_OFF" ;
VAL_ 801 EYE321_7_6_INFO_SET_CC 1 "TURN_ON" 0 "TURN_OFF" ;
VAL_ 801 EYE321_7_7_INFO_OFF 1 "TURN_ON" 0 "TURN_OFF" ;
VAL_ 801 EYE321_6_0_FAIL_EYESIGHT 1 "FAIL" 0 "NORMAL" ;
VAL_ 801 EYE321_6_1_MOV_EYESIGHT_SCREEN 1 "DISP_EYE" 0 "OFF" ;
VAL_ 801 EYE321_6_2_IND_VEHICLE 1 "TURN_ON" 0 "TURN_OFF" ;
VAL_ 801 EYE321_6_3_BRAKELAMP_VEHICLE 1 "TURN_ON" 0 "TURN_OFF" ;
VAL_ 801 EYE321_6_4_IND_FORWARD_VECL 1 "TURN_ON" 0 "TURN_OFF" ;
VAL_ 801 EYE321_6_5_BRAKELAMP_FORWARD 1 "TURN_ON" 0 "TURN_OFF" ;
VAL_ 801 EYE321_6_6_CC_OR_LIM_SON 1 "SET" 0 "Non-SET" ;
VAL_ 801 EYE321_6_7_TEMP_OFF_STATE 1 "Temp OFF State" 0 "Normal State" ;
VAL_ 801 EYE321_4_0_ACC_MODE 3 "No_Definition" 2 "SAS" 1 "CC" 0 "ACC" ;
VAL_ 801 EYE321_4_2_SRVD_LASTMEM_ST_REQ 1 "LASTMEM_STARTUP_REQ" 0 "ON_STARTUP_REQ" ;
VAL_ 801 EYE321_4_3_INFO_MAIN_CC 3 "TURN_ON_BLUE or BLINK_GREEN" 2 "TURN_ON_GREEN" 1 "TURN_ON_WHITE" 0 "TURN_OFF" ;
VAL_ 801 EYE321_4_5_TRAFFIC_LIGHT 7 "No_Definition" 6 "No_Definition" 5 "BLINK_BLUE" 4 "TURN_ON_BLUE" 3 "BLINK_RED" 2 "TURN_ON_RED" 1 "TURN_ON_DISP" 0 "TURN_OFF" ;
VAL_ 801 EYE321_3_0_CODE_HALT 7 "HALT_NOTICE" 6 "No_Definition" 5 "No_Definition" 4 "HALT_E3" 3 "HALT_E2" 2 "HALT_E1-2" 1 "HALT_E1-1" 0 "No HALT" ;
VAL_ 801 EYE321_3_3_ELK_EQUIP 1 "EQUIP_ELK" 0 "NOT_EQUIP_ELK" ;
VAL_ 801 EYE321_3_4_SET_DIST 7 "No_Definition" 6 "No_Definition" 5 "No_Definition" 4 "Distance(4)" 3 "Distance(3)" 2 "Distance(2)" 1 "Distance(1)" 0 "No_Display" ;
VAL_ 801 EYE321_3_7_TJA 1 "ON" 0 "OFF" ;
VAL_ 801 EYE321_2_0_ACC_CANCEL_OR_CSTM 15 "No_Definition" 14 "No_Definition" 13 "No_Definition" 12 "No_Definition" 11 "Pattern11" 10 "Pattern10" 9 "Pattern9" 8 "Pattern8" 7 "Pattern7" 6 "Pattern6" 5 "Pattern5" 4 "Pattern4" 3 "Pattern3" 2 "Pattern2" 1 "Pattern1" 0 "OFF" ;
VAL_ 801 EYE321_2_4_ALK_CANCEL_OR_CSTM 7 "Lka_Cancel_DMS_Undetected" 6 "No_Definition" 5 "Lka_Cancel_Speed_High" 4 "Lka_Cancel_Speed_Low" 3 "Lka_Cancel_Other" 2 "Lka_Cancel_No_Steering_CONT" 1 "Lka_Cancel_Curve" 0 "No_Display" ;
VAL_ 801 EYE321_2_7_ALK_CANCEL_DISP_TYPE 1 "ALK-Bｷｬﾝｾﾙ時" 0 "ALK-Cｷｬﾝｾﾙ時" ;
VAL_ 801 EYE321_1_4_PRECRASH_BRAKE_OFF 1 "TURN_ON" 0 "TURN_OFF" ;
VAL_ 801 EYE321_1_5_LANE_DEPARTURE_OFF 1 "TURN_ON" 0 "TURN_OFF" ;
VAL_ 801 EYE321_1_6_MET_AD_DRV_ASS 1 "ON" 0 "OFF" ;
VAL_ 801 EYE321_1_7_ALC_EQUIP 1 "ON" 0 "OFF" ;
VAL_ 1746 LCT6D2_5_0_HDMAP_RELEASE_SEASON 4 "4" 3 "3" 2 "2" 1 "1" ;
VAL_ 1746 LCT6D2_1_5_ADASMAP_FLAG 1 "ON" 0 "OFF" ;
VAL_ 1746 LCT6D2_1_6_HDMAP_FLAG 1 "ON" 0 "OFF" ;
VAL_ 1746 LCT6D2_1_7_GSRISA_FLAG 1 "ON" 0 "OFF" ;
VAL_ 845 ADAS34D_16_0_CSTM_SNR_DSPREEQ 3 "No_Definition" 2 "Disp(Gray out)" 1 "Disp(Normal)" 0 "No Disp" ;
VAL_ 845 ADAS34D_16_2_CSTM_RAB_DSPREQ 3 "No_Definition" 2 "Disp(Gray out)" 1 "Disp(Normal)" 0 "No Disp" ;
VAL_ 845 ADAS34D_16_4_CSTM_PED_DSPREQ 3 "No_Definition" 2 "Disp(Gray out)" 1 "Disp(Normal)" 0 "No Disp" ;
VAL_ 845 ADAS34D_16_6_CSTM_PEDTIM_DSPREQ 3 "No_Definition" 2 "Disp(Gray out)" 1 "Disp(Normal)" 0 "No Disp" ;
VAL_ 845 ADAS34D_15_0_CSTM_SNR_CLEAR 1 "ON" 0 "OFF" ;
VAL_ 845 ADAS34D_15_1_CSTM_RAB 1 "ON" 0 "OFF" ;
VAL_ 845 ADAS34D_15_2_CSTM_RAB_PED 1 "ON" 0 "OFF" ;
VAL_ 845 ADAS34D_15_3_CSTM_RAB_PED_TIMING 3 "No_Definition" 2 "Far" 1 "Near" 0 "Middle" ;
VAL_ 845 ADAS34D_15_5_CSTM_TEMP_OFF 3 "未定義" 2 "OFF" 1 "ON" 0 "No Disp" ;
VAL_ 845 ADAS34D_15_7_TEMP_OFF_STATE 1 "Temp OFF State" 0 "Normal State" ;
VAL_ 845 ADAS34D_14_0_RAB_WARNING 7 "No_Definition" 6 "No_Definition" 5 "RAB_Interrupt_5" 4 "RAB_Interrupt_4" 3 "RAB_Interrupt_3" 2 "RAB_Interrupt_2" 1 "RAB_Interrupt_1" 0 "OFF" ;
VAL_ 845 ADAS34D_14_3_SONAR_LEVEL 8 "No_Definition" 7 "Pedestrian" 6 "FIRST_BRAKE" 5 "FAR" 4 "MIDDLE" 3 "NEAR" 2 "MOST_NEAR" 1 "SECOND_BRAKE" 0 "OFF" ;
VAL_ 845 ADAS34D_13_0_PED_WARN_CENTER 1 "ON" 0 "OFF" ;
VAL_ 845 ADAS34D_13_1_PED_WARN_LEFT 1 "ON" 0 "OFF" ;
VAL_ 845 ADAS34D_13_2_PED_WARN_RIGHT 1 "ON" 0 "OFF" ;
VAL_ 845 ADAS34D_13_3_RAB_TRIG_TYPE 3 "Cyclist" 2 "Pedestrian" 1 "USS" 0 "NoAct" ;
VAL_ 845 ADAS34D_9_0_SONAR_R_R_CORNER_4LV 7 "No_Definition" 6 "No_Definition" 5 "No_Definition" 4 "MOST_NEAR" 3 "NEAR" 2 "MIDDLE" 1 "FAR" 0 "CLEAR" ;
VAL_ 845 ADAS34D_8_0_SONAR_DISP_INT 1 "DISP_INT_ON" 0 "DISP_INT_OFF" ;
VAL_ 845 ADAS34D_8_1_SONAR_R_CENTER 7 "No_Definition" 6 "No_Definition" 5 "No_Definition" 4 "MOST_NEAR" 3 "NEAR" 2 "MIDDLE" 1 "FAR" 0 "CLEAR" ;
VAL_ 845 ADAS34D_8_4_SONAR_R_L_CORNER_4LV 7 "No_Definition" 6 "No_Definition" 5 "No_Definition" 4 "MOST_NEAR" 3 "NEAR" 2 "MIDDLE" 1 "FAR" 0 "CLEAR" ;
VAL_ 845 ADAS34D_7_0_SONAR_SYS_FAIL 3 "No_Definition" 2 "FAIL_2" 1 "FAIL_1" 0 "NO_FAIL" ;
VAL_ 845 ADAS34D_7_2_RAB_HALT 3 "No_Definition" 2 "HALT_2" 1 "HALT_1" 0 "NO_HALT" ;
VAL_ 845 ADAS34D_7_4_CAMERA_FAIL 3 "No_Definition" 2 "FAIL_2" 1 "FAIL_1" 0 "NO_FAIL" ;
VAL_ 845 ADAS34D_7_6_RAB_PED_HALT 3 "No_Definition" 2 "HALT_2" 1 "HALT_1" 0 "NO_HALT" ;
VAL_ 845 ADAS34D_6_0_REQ_ACT_EPB 1 "ON" 0 "OFF" ;
VAL_ 845 ADAS34D_6_1_STOP_HOJI_BUZ_ACT 1 "ON" 0 "OFF" ;
VAL_ 845 ADAS34D_6_2_RAB_OFF 1 "RAB_OFF" 0 "RAB_ON" ;
VAL_ 845 ADAS34D_6_3_SONAR_OFF 1 "SONAR_OFF" 0 "SONAR_ON" ;
VAL_ 845 ADAS34D_6_4_RAB_PED_OFF 1 "RAB_PED_OFF" 0 "RAB_PED_ON" ;
VAL_ 845 ADAS34D_6_5_SONAR_HALT 3 "No_Definition" 2 "HALT_2" 1 "HALT_1" 0 "NO_HALT" ;
VAL_ 845 ADAS34D_5_0_YOATSU_ACT 1 "ON" 0 "OFF" ;
VAL_ 845 ADAS34D_5_1_TORQUE_LIM_ACT 1 "ON" 0 "OFF" ;
VAL_ 845 ADAS34D_4_0_RAB_ACT 1 "ON" 0 "OFF" ;
VAL_ 845 ADAS34D_3_0_RAB 1 "ON" 0 "OFF" ;
VAL_ 845 ADAS34D_3_1_RAB_PED 1 "ON" 0 "OFF" ;
VAL_ 844 ADAS34C_25_0_CSTM_ADDON_DISP_CNT 1 "ON" 0 "OFF" ;
VAL_ 844 ADAS34C_25_1_CSTM_LANE_SET_CONT 1 "ON" 0 "OFF" ;
VAL_ 844 ADAS34C_24_0_CSTM_LSW 1 "ON" 0 "OFF" ;
VAL_ 844 ADAS34C_24_1_CSTM_GREEN_LIGHT 1 "ON" 0 "OFF" ;
VAL_ 844 ADAS34C_24_2_CSTM_LANE_SET 1 "LEFT" 0 "RIGHT" ;
VAL_ 844 ADAS34C_24_3_CSTM_PROPOSAL_HMI 1 "ON" 0 "OFF" ;
VAL_ 844 ADAS34C_24_4_CSTM_V2N 1 "ON" 0 "OFF" ;
VAL_ 844 ADAS34C_24_5_CSTM_DATA_COLLECT 1 "ON" 0 "OFF" ;
VAL_ 844 ADAS34C_24_6_CSTM_COLLECT_IMAGE 1 "ON" 0 "OFF" ;
VAL_ 844 ADAS34C_24_7_CSTM_COLLECT_LOC 1 "ON" 0 "OFF" ;
VAL_ 844 ADAS34C_22_0_DATA_COLLECT_DISP 3 "Grey_out" 2 "Disp(With_setting_parts)" 1 "Disp(No_setting_parts)" 0 "No_Disp" ;
VAL_ 844 ADAS34C_22_2_COLLECT_IMAGE_DISP 3 "Grey_out" 2 "Disp(With_setting_parts)" 1 "Disp(No_setting_parts)" 0 "No_Disp" ;
VAL_ 844 ADAS34C_22_4_COLLECT_LOC_DISP 3 "Grey_out" 2 "Disp(With_setting_parts)" 1 "Disp(No_setting_parts)" 0 "No_Disp" ;
VAL_ 844 ADAS34C_21_0_LSW_DISP_CONT 3 "Grey_out" 2 "Disp(With_setting_parts)" 1 "Disp(No_setting_parts)" 0 "No_Disp" ;
VAL_ 844 ADAS34C_21_2_GREEN_LIGHT_DISP 3 "Grey_out" 2 "Disp(With_setting_parts)" 1 "Disp(No_setting_parts)" 0 "No_Disp" ;
VAL_ 844 ADAS34C_21_4_LANE_SET_DISP_CONT 3 "Grey_out" 2 "Disp(With_setting_parts)" 1 "Disp(No_setting_parts)" 0 "No_Disp" ;
VAL_ 844 ADAS34C_21_6_PROPOSAL_HMI_DISP 3 "Grey_out" 2 "Disp(With_setting_parts)" 1 "Disp(No_setting_parts)" 0 "No_Disp" ;
VAL_ 844 ADAS34C_20_0_ADD_ON_DISP_CONT 3 "Grey_out" 2 "Disp(With_setting_parts)" 1 "Disp(No_setting_parts)" 0 "No_Disp" ;
VAL_ 844 ADAS34C_20_2_V2N_DISP_CONT 3 "Grey_out" 2 "Disp(With_setting_parts)" 1 "Disp(No_setting_parts)" 0 "No_Disp" ;
VAL_ 844 ADAS34C_20_4_LANE_SET_PTN_DISP 3 "Grey_out" 2 "Disp(With_setting_parts)" 1 "Disp(No_setting_parts)" 0 "No_Disp" ;
VAL_ 844 ADAS34C_18_0_CSTM_SUPPRESS_SPEED 1 "ON" 0 "OFF" ;
VAL_ 844 ADAS34C_18_1_SUPPRESS_SPD_LEVEL 3 "No_Definition" 2 "High" 1 "Low" 0 "Middle" ;
VAL_ 844 ADAS34C_18_3_ACTIVE_AVOIDANCE 1 "ON" 0 "OFF" ;
VAL_ 844 ADAS34C_18_4_ACTIVE_AVOIDANCE_LV 3 "No_Definition" 2 "High" 1 "Low" 0 "Middle" ;
VAL_ 844 ADAS34C_17_0_CSTM_PDA_CURR 1 "ON" 0 "OFF" ;
VAL_ 844 ADAS34C_17_1_TARGET_VEHICLE 1 "ON" 0 "OFF" ;
VAL_ 844 ADAS34C_17_2_TARGET_SURROUNDING 1 "ON" 0 "OFF" ;
VAL_ 844 ADAS34C_17_3_TARGET_SLOPE_DOWN 1 "ON" 0 "OFF" ;
VAL_ 844 ADAS34C_17_4_CUS_SUPPRESS_SPDTGT 1 "ON" 0 "OFF" ;
VAL_ 844 ADAS34C_15_0_A_AVOIDANCE_DISP 3 "Grey_out" 2 "Disp(With_setting_parts)" 1 "Disp(No_setting_parts)" 0 "No_Disp" ;
VAL_ 844 ADAS34C_15_2_A_AVOIDANCE_LV_DISP 3 "Grey_out" 2 "Disp(With_setting_parts)" 1 "Disp(No_setting_parts)" 0 "No_Disp" ;
VAL_ 844 ADAS34C_15_4_A_AVOIDANCE_LV_PTN 3 "Pattern④(Low/High)" 2 "Pattern③(Middle/High)" 1 "Pattern②(Low/Middle)" 0 "Pattern①(Low/Middle/High)" ;
VAL_ 844 ADAS34C_14_0_SUPPRESS_SPDTGT_DSP 3 "Grey_out" 2 "Disp(With_setting_parts)" 1 "Disp(No_setting_parts)" 0 "No_Disp" ;
VAL_ 844 ADAS34C_14_2_TARGET_VEHICLE_DISP 3 "Grey_out" 2 "Disp(With_setting_parts)" 1 "Disp(No_setting_parts)" 0 "No_Disp" ;
VAL_ 844 ADAS34C_14_4_TARGET_SURROUND_DSP 3 "Grey_out" 2 "Disp(With_setting_parts)" 1 "Disp(No_setting_parts)" 0 "No_Disp" ;
VAL_ 844 ADAS34C_14_6_TGT_SLOPE_DOWN_DSP 3 "Grey_out" 2 "Disp(With_setting_parts)" 1 "Disp(No_setting_parts)" 0 "No_Disp" ;
VAL_ 844 ADAS34C_13_0_PDA_DISP_CONT 3 "Grey_out" 2 "Disp(With_setting_parts)" 1 "Disp(No_setting_parts)" 0 "No_Disp" ;
VAL_ 844 ADAS34C_13_2_SUPPRESS_SPD_DISP 3 "Grey_out" 2 "Disp(With_setting_parts)" 1 "Disp(No_setting_parts)" 0 "No_Disp" ;
VAL_ 844 ADAS34C_13_4_SUPPRESS_SPDLV_DISP 3 "Grey_out" 2 "Disp(With_setting_parts)" 1 "Disp(No_setting_parts)" 0 "No_Disp" ;
VAL_ 844 ADAS34C_13_6_SUPPRESS_SPD_LV_PTN 3 "Pattern④(Low/High)" 2 "Pattern③(Middle/High)" 1 "Pattern②(Low/Middle)" 0 "Pattern①(Low/Middle/High)" ;
VAL_ 844 ADAS34C_11_0_ISA_OFS_U50_DISP 3 "Grey_out" 2 "Disp(With_setting_parts)" 1 "Disp(No_setting_parts)" 0 "No_Disp" ;
VAL_ 844 ADAS34C_11_2_ISA_OFS_OV50_DISP 3 "Grey_out" 2 "Disp(With_setting_parts)" 1 "Disp(No_setting_parts)" 0 "No_Disp" ;
VAL_ 844 ADAS34C_10_0_SLWF_OFFSET_OV50 31 "No_Definition" 30 "No_Definition" 29 "No_Definition" 28 "No_Definition" 27 "No_Definition" 26 "No_Definition" 25 "No_Definition" 24 "No_Definition" 23 "No_Definition" 22 "No_Definition" 21 "No_Definition" 20 "10" 19 "9" 18 "8" 17 "7" 16 "6" 15 "5" 14 "4" 13 "3" 12 "2" 11 "1" 10 "0" 9 "-1" 8 "-2" 7 "-3" 6 "-4" 5 "-5" 4 "-6" 3 "-7" 2 "-8" 1 "-9" 0 "-10" ;
VAL_ 844 ADAS34C_9_0_SLWF_OFFSET_U50 31 "No_Definition" 30 "No_Definition" 29 "No_Definition" 28 "No_Definition" 27 "No_Definition" 26 "No_Definition" 25 "No_Definition" 24 "No_Definition" 23 "No_Definition" 22 "No_Definition" 21 "No_Definition" 20 "10" 19 "9" 18 "8" 17 "7" 16 "6" 15 "5" 14 "4" 13 "3" 12 "2" 11 "1" 10 "0" 9 "-1" 8 "-2" 7 "-3" 6 "-4" 5 "-5" 4 "-6" 3 "-7" 2 "-8" 1 "-9" 0 "-10" ;
VAL_ 844 ADAS34C_9_5_CSTM_SLWF 1 "ON" 0 "OFF" ;
VAL_ 844 ADAS34C_9_6_CSTM_SLWF_OFS_CONT 1 "ON" 0 "OFF" ;
VAL_ 844 ADAS34C_9_7_ISA_IACC_OFS_CONT 1 "ON" 0 "OFF" ;
VAL_ 844 ADAS34C_8_0_ISA_IACC_OFFSET_OV50 31 "No_Definition" 30 "No_Definition" 29 "No_Definition" 28 "No_Definition" 27 "No_Definition" 26 "No_Definition" 25 "No_Definition" 24 "No_Definition" 23 "No_Definition" 22 "No_Definition" 21 "No_Definition" 20 "10" 19 "9" 18 "8" 17 "7" 16 "6" 15 "5" 14 "4" 13 "3" 12 "2" 11 "1" 10 "0" 9 "-1" 8 "-2" 7 "-3" 6 "-4" 5 "-5" 4 "-6" 3 "-7" 2 "-8" 1 "-9" 0 "-10" ;
VAL_ 844 ADAS34C_8_5_SIGN_SWITCH_SOUND 1 "ON" 0 "OFF" ;
VAL_ 844 ADAS34C_8_6_CSTM_LOADSIGNS_SYS 1 "ON" 0 "OFF" ;
VAL_ 844 ADAS34C_8_7_CSTM_ISA_IACC_CONT 1 "ON" 0 "OFF" ;
VAL_ 844 ADAS34C_7_0_ISA_IACC_OFFSET_U50 31 "No_Definition" 30 "No_Definition" 29 "No_Definition" 28 "No_Definition" 27 "No_Definition" 26 "No_Definition" 25 "No_Definition" 24 "No_Definition" 23 "No_Definition" 22 "No_Definition" 21 "No_Definition" 20 "10" 19 "9" 18 "8" 17 "7" 16 "6" 15 "5" 14 "4" 13 "3" 12 "2" 11 "1" 10 "0" 9 "-1" 8 "-2" 7 "-3" 6 "-4" 5 "-5" 4 "-6" 3 "-7" 2 "-8" 1 "-9" 0 "-10" ;
VAL_ 844 ADAS34C_7_5_CSTM_LOADSIGNS_ADD 1 "ON" 0 "OFF" ;
VAL_ 844 ADAS34C_7_6_CSTM_ISA_IACC_ACCEPT 3 "No_Definition" 2 "Accept" 1 "Intelligent" 0 "Manual" ;
VAL_ 844 ADAS34C_6_0_ISA_IACC_PTN_DISP 3 "Grey_out" 2 "Disp(With_setting_parts)" 1 "Disp(No_setting_parts)" 0 "No_Disp" ;
VAL_ 844 ADAS34C_6_2_SLWF_OFS_U50_DISP 3 "Grey_out" 2 "Disp(With_setting_parts)" 1 "Disp(No_setting_parts)" 0 "No_Disp" ;
VAL_ 844 ADAS34C_6_4_SLWF_OFS_OV50_DISP 3 "Grey_out" 2 "Disp(With_setting_parts)" 1 "Disp(No_setting_parts)" 0 "No_Disp" ;
VAL_ 844 ADAS34C_5_0_SLWF_DISP_CONT 3 "Grey_out" 2 "Disp(With_setting_parts)" 1 "Disp(No_setting_parts)" 0 "No_Disp" ;
VAL_ 844 ADAS34C_5_2_ISA_IACC_OFSET_DISP 3 "Grey_out" 2 "Disp(With_setting_parts)" 1 "Disp(No_setting_parts)" 0 "No_Disp" ;
VAL_ 844 ADAS34C_5_4_SLWF_OFSET_DISP 3 "Grey_out" 2 "Disp(With_setting_parts)" 1 "Disp(No_setting_parts)" 0 "No_Disp" ;
VAL_ 844 ADAS34C_5_6_SIGNSWITCH_SND_DISP 3 "Grey_out" 2 "Disp(With_setting_parts)" 1 "Disp(No_setting_parts)" 0 "No_Disp" ;
VAL_ 844 ADAS34C_4_0_LOADSIGN_DISP_CONT 3 "Grey_out" 2 "Disp(With_setting_parts)" 1 "Disp(No_setting_parts)" 0 "No_Disp" ;
VAL_ 844 ADAS34C_4_2_LOADSIGN_ADD_DISP 3 "Grey_out" 2 "Disp(With_setting_parts)" 1 "Disp(No_setting_parts)" 0 "No_Disp" ;
VAL_ 844 ADAS34C_4_4_ISA_IACC_ACCEPT_DISP 3 "Grey_out" 2 "Disp(With_setting_parts)" 1 "Disp(No_setting_parts)" 0 "No_Disp" ;
VAL_ 844 ADAS34C_4_6_ISA_IACC_ACCEPT_PTN 3 "No_Definition" 2 "No_Definition" 1 "Pattern②(Manual/Intelligent/Accept)" 0 "Pattern①(Manual/Intelligent)" ;
VAL_ 844 ADAS34C_3_0_EYE_VALID 1 "valid" 0 "invalid" ;
VAL_ 843 ADAS34B_31_0_CSTM_ACC_FUNC_CONT 1 "ON" 0 "OFF" ;
VAL_ 843 ADAS34B_30_0_CSTM_ACC_CONT_SET 3 "Lv.4(Dynamic)" 2 "Lv.3(Standard)" 1 "Lv.2(Comfort)" 0 "Lv.1(Eco)" ;
VAL_ 843 ADAS34B_30_2_CSTM_ACC_OVERTAKE 1 "ON" 0 "OFF" ;
VAL_ 843 ADAS34B_30_3_CSTM_ACC_TARGET_OPT 1 "ON" 0 "OFF" ;
VAL_ 843 ADAS34B_30_4_CSTM_ACC_STOP_CONT 1 "ON" 0 "OFF" ;
VAL_ 843 ADAS34B_30_5_CSTM_ACC_SLOWDOWN 1 "ON" 0 "OFF" ;
VAL_ 843 ADAS34B_30_6_CSTM_ACC_HIGHWAY 1 "ON" 0 "OFF" ;
VAL_ 843 ADAS34B_30_7_CSTM_ACC_SYS 1 "ON" 0 "OFF" ;
VAL_ 843 ADAS34B_28_0_ACC_TARGET_OPT_DISP 3 "Grey_out" 2 "Disp(With_setting_parts)" 1 "Disp(No_setting_parts)" 0 "No_Disp" ;
VAL_ 843 ADAS34B_28_2_ACC_STOP_DISP 3 "Grey_out" 2 "Disp(With_setting_parts)" 1 "Disp(No_setting_parts)" 0 "No_Disp" ;
VAL_ 843 ADAS34B_28_4_ACC_SLOWDOWN_DISP 3 "Grey_out" 2 "Disp(With_setting_parts)" 1 "Disp(No_setting_parts)" 0 "No_Disp" ;
VAL_ 843 ADAS34B_28_6_ACC_HIGHWAY_DISP 3 "Grey_out" 2 "Disp(With_setting_parts)" 1 "Disp(No_setting_parts)" 0 "No_Disp" ;
VAL_ 843 ADAS34B_27_0_ACC_DISP_CONT 3 "Grey_out" 2 "Disp(With_setting_parts)" 1 "Disp(No_setting_parts)" 0 "No_Disp" ;
VAL_ 843 ADAS34B_27_2_ACC_LEVEL_DISP_CONT 3 "Grey_out" 2 "Disp(With_setting_parts)" 1 "Disp(No_setting_parts)" 0 "No_Disp" ;
VAL_ 843 ADAS34B_27_4_ACC_OVERTAKE_DISP 3 "Grey_out" 2 "Disp(With_setting_parts)" 1 "Disp(No_setting_parts)" 0 "No_Disp" ;
VAL_ 843 ADAS34B_27_6_ACC_LEVEL_PTN_DISP 3 "Grey_out" 2 "Disp(With_setting_parts)" 1 "Disp(No_setting_parts)" 0 "No_Disp" ;
VAL_ 843 ADAS34B_25_0_CSTM_ACTIVE_LKS 1 "ON" 0 "OFF" ;
VAL_ 843 ADAS34B_25_1_CSTM_A_LKS_AUTOPASS 1 "ON" 0 "OFF" ;
VAL_ 843 ADAS34B_25_2_CSTM_A_LKS_NAVI 1 "ON" 0 "OFF" ;
VAL_ 843 ADAS34B_25_3_CSTM_A_LKS_OFFSET 1 "ON" 0 "OFF" ;
VAL_ 843 ADAS34B_25_4_CSTM_A_LKS_OPT_CONT 1 "ON" 0 "OFF" ;
VAL_ 843 ADAS34B_23_0_A_LKS_OPTION_DISP 3 "Grey_out" 2 "Disp(With_setting_parts)" 1 "Disp(No_setting_parts)" 0 "No_Disp" ;
VAL_ 843 ADAS34B_23_2_A_LKS_AUTOPASS_DISP 3 "Grey_out" 2 "Disp(With_setting_parts)" 1 "Disp(No_setting_parts)" 0 "No_Disp" ;
VAL_ 843 ADAS34B_23_4_A_LKS_NAVI_DISP 3 "Grey_out" 2 "Disp(With_setting_parts)" 1 "Disp(No_setting_parts)" 0 "No_Disp" ;
VAL_ 843 ADAS34B_23_6_A_LKS_OFFSET_DISP 3 "Grey_out" 2 "Disp(With_setting_parts)" 1 "Disp(No_setting_parts)" 0 "No_Disp" ;
VAL_ 843 ADAS34B_22_0_ACTIVE_LKS_DISP 3 "Grey_out" 2 "Disp(With_setting_parts)" 1 "Disp(No_setting_parts)" 0 "No_Disp" ;
VAL_ 843 ADAS34B_21_0_CSTM_LDW_TMG_CNT 1 "ON" 0 "OFF" ;
VAL_ 843 ADAS34B_21_1_CSTM_LDPTARGET_CONT 1 "ON" 0 "OFF" ;
VAL_ 843 ADAS34B_21_2_ELK_ASSISTTYPE_CONT 1 "ON" 0 "OFF" ;
VAL_ 843 ADAS34B_20_0_CSTM_ELK 1 "ON" 0 "OFF" ;
VAL_ 843 ADAS34B_20_1_CSTM_ELK_SOUND 1 "ON" 0 "OFF" ;
VAL_ 843 ADAS34B_20_2_CSTM_ELK_VIB 1 "ON" 0 "OFF" ;
VAL_ 843 ADAS34B_20_3_CSTM_ELK_CTRL 1 "ON" 0 "OFF" ;
VAL_ 843 ADAS34B_20_4_CSTM_LDW_TIMING 3 "No_Definition" 2 "Early" 1 "Late" 0 "Middle" ;
VAL_ 843 ADAS34B_20_6_LDW_SOUND_ON_OFF_SW 1 "ON" 0 "OFF" ;
VAL_ 843 ADAS34B_20_7_CSTM_LD_ASSISTTYPE 1 "ON" 0 "OFF" ;
VAL_ 843 ADAS34B_19_0_CSTM_LANE_DEPARTURE 1 "ON" 0 "OFF" ;
VAL_ 843 ADAS34B_19_1_CSTM_LDW_SOUND 1 "ON" 0 "OFF" ;
VAL_ 843 ADAS34B_19_2_CSTM_LDW_VIB 1 "ON" 0 "OFF" ;
VAL_ 843 ADAS34B_19_3_CSTM_LDP 1 "ON" 0 "OFF" ;
VAL_ 843 ADAS34B_19_4_LDP_TGT_SOLIDLINE 1 "ON" 0 "OFF" ;
VAL_ 843 ADAS34B_19_5_LDP_TGT_DASHLINE 1 "ON" 0 "OFF" ;
VAL_ 843 ADAS34B_19_6_LDP_TGT_SIDE_OBJ 1 "ON" 0 "OFF" ;
VAL_ 843 ADAS34B_19_7_LDP_TGT_SIDE_VHCL 1 "ON" 0 "OFF" ;
VAL_ 843 ADAS34B_17_0_ELK_ASSISTTYPE_DISP 3 "Grey_out" 2 "Disp(With_setting_parts)" 1 "Disp(No_setting_parts)" 0 "No_Disp" ;
VAL_ 843 ADAS34B_17_2_ELK_SOUND_DISP_CONT 3 "Grey_out" 2 "Disp(With_setting_parts)" 1 "Disp(No_setting_parts)" 0 "No_Disp" ;
VAL_ 843 ADAS34B_17_4_ELK_VIB_DISP_CONT 3 "Grey_out" 2 "Disp(With_setting_parts)" 1 "Disp(No_setting_parts)" 0 "No_Disp" ;
VAL_ 843 ADAS34B_17_6_ELK_CTRL_DISP_CONT 3 "Grey_out" 2 "Disp(With_setting_parts)" 1 "Disp(No_setting_parts)" 0 "No_Disp" ;
VAL_ 843 ADAS34B_16_0_LDW_TIMING_DISP 3 "Grey_out" 2 "Disp(With_setting_parts)" 1 "Disp(No_setting_parts)" 0 "No_Disp" ;
VAL_ 843 ADAS34B_16_2_LDW_TIMING_PTN 7 "No_Definition" 6 "No_Definition" 5 "No_Definition" 4 "Pattern⑤(Late/Middle/Early/Intelligent)" 3 "Pattern④(Late/Early)" 2 "Pattern③(Middle/Early)" 1 "Pattern②(Late/Middle)" 0 "Pattern①(Late/Middle/Early)" ;
VAL_ 843 ADAS34B_16_6_LDW_TIMING_PTN_DISP 3 "Grey_out" 2 "Disp(With_setting_parts)" 1 "Disp(No_setting_parts)" 0 "No_Disp" ;
VAL_ 843 ADAS34B_15_0_TGT_SOLIDLINE_DISP 3 "Grey_out" 2 "Disp(With_setting_parts)" 1 "Disp(No_setting_parts)" 0 "No_Disp" ;
VAL_ 843 ADAS34B_15_2_TGT_DASHLINE_DISP 3 "Grey_out" 2 "Disp(With_setting_parts)" 1 "Disp(No_setting_parts)" 0 "No_Disp" ;
VAL_ 843 ADAS34B_15_4_TGT_SIDE_OBJ_DISP 3 "Grey_out" 2 "Disp(With_setting_parts)" 1 "Disp(No_setting_parts)" 0 "No_Disp" ;
VAL_ 843 ADAS34B_15_6_TGT_SIDE_VHCL_DISP 3 "Grey_out" 2 "Disp(With_setting_parts)" 1 "Disp(No_setting_parts)" 0 "No_Disp" ;
VAL_ 843 ADAS34B_14_0_LD_ASSISTTYPE_DISP 3 "Grey_out" 2 "Disp(With_setting_parts)" 1 "Disp(No_setting_parts)" 0 "No_Disp" ;
VAL_ 843 ADAS34B_14_2_LDW_SOUND_DISP_CONT 3 "Grey_out" 2 "Disp(With_setting_parts)" 1 "Disp(No_setting_parts)" 0 "No_Disp" ;
VAL_ 843 ADAS34B_14_4_LDW_VIB_DISP_CONT 3 "Grey_out" 2 "Disp(With_setting_parts)" 1 "Disp(No_setting_parts)" 0 "No_Disp" ;
VAL_ 843 ADAS34B_14_6_LDP_DISP_CONT 3 "Grey_out" 2 "Disp(With_setting_parts)" 1 "Disp(No_setting_parts)" 0 "No_Disp" ;
VAL_ 843 ADAS34B_13_0_LANE_DEPARTURE_DISP 3 "Grey_out" 2 "Disp(With_setting_parts)" 1 "Disp(No_setting_parts)" 0 "No_Disp" ;
VAL_ 843 ADAS34B_13_2_LDPTARGET_DISP_CONT 3 "Grey_out" 2 "Disp(With_setting_parts)" 1 "Disp(No_setting_parts)" 0 "No_Disp" ;
VAL_ 843 ADAS34B_13_4_LDW_SOUND_SW_DISP 3 "Grey_out" 2 "Disp(With_setting_parts)" 1 "Disp(No_setting_parts)" 0 "No_Disp" ;
VAL_ 843 ADAS34B_13_6_ELK_DISP_CONT 3 "Grey_out" 2 "Disp(With_setting_parts)" 1 "Disp(No_setting_parts)" 0 "No_Disp" ;
VAL_ 843 ADAS34B_11_0_CSTM_MIS_AT_BACK 1 "ON" 0 "OFF" ;
VAL_ 843 ADAS34B_11_1_MIS_AT_BACK_SPD_LIM 3 "No_Definition" 2 "High(20km/h)/(15mph)" 1 "Middle(15km/h)/(10mph)" 0 "Low(10km/h)/(5mph)" ;
VAL_ 843 ADAS34B_11_3_CSTM_FCW_TYPE_CONT 1 "ON" 0 "OFF" ;
VAL_ 843 ADAS34B_11_4_FCTI_NOTICE_CONT 1 "ON" 0 "OFF" ;
VAL_ 843 ADAS34B_11_5_CSTM_SAFTY_MOD_SENS 1 "ON" 0 "OFF" ;
VAL_ 843 ADAS34B_11_6_MIS_AT_BACK_CONT 1 "ON" 0 "OFF" ;
VAL_ 843 ADAS34B_10_0_CSTM_FCTI_CONT 1 "ON" 0 "OFF" ;
VAL_ 843 ADAS34B_10_1_CSTM_FCTI_SOUND 1 "ON" 0 "OFF" ;
VAL_ 843 ADAS34B_10_2_CSTM_FCTI_PULSE 1 "ON" 0 "OFF" ;
VAL_ 843 ADAS34B_10_3_CSTM_SAFTY_MODE 1 "ON" 0 "OFF" ;
VAL_ 843 ADAS34B_10_4_CSTM_SAFTY_MODE_LV 3 "No_Definition" 2 "High" 1 "Low" 0 "Middle" ;
VAL_ 843 ADAS34B_10_6_CSTM_BRK_TIMING_CUR 1 "ON" 0 "OFF" ;
VAL_ 843 ADAS34B_10_7_CSTM_FCW_CONT_CUR 1 "ON" 0 "OFF" ;
VAL_ 843 ADAS34B_9_0_CSTM_P_CR 1 "ON" 0 "OFF" ;
VAL_ 843 ADAS34B_9_1_FCW_SOUND_ON_OFF_SW 1 "ON" 0 "OFF" ;
VAL_ 843 ADAS34B_9_2_CSTM_FCW_TIMING 3 "No_Definition" 2 "Far" 1 "Near" 0 "Middle" ;
VAL_ 843 ADAS34B_9_4_CSTM_FCW_TYPE_SOUND 1 "ON" 0 "OFF" ;
VAL_ 843 ADAS34B_9_5_CSTM_FCW_TYPE_PULSE 1 "ON" 0 "OFF" ;
VAL_ 843 ADAS34B_9_6_CSTM_BRAKE_TIMING 3 "No_Definition" 2 "No_Definition" 1 "Far" 0 "Middle" ;
VAL_ 843 ADAS34B_8_0_SAFTY_MODE_SENS_DISP 3 "Grey_out" 2 "Disp(With_setting_parts)" 1 "Disp(No_setting_parts)" 0 "No_Disp" ;
VAL_ 843 ADAS34B_8_2_MIS_AT_BACK_PTN_DISP 3 "Grey_out" 2 "Disp(With_setting_parts)" 1 "Disp(No_setting_parts)" 0 "No_Disp" ;
VAL_ 843 ADAS34B_7_0_MIS_AT_BACK_DISP 3 "Grey_out" 2 "Disp(With_setting_parts)" 1 "Disp(No_setting_parts)" 0 "No_Disp" ;
VAL_ 843 ADAS34B_7_2_MIS_AT_BACK_LIM_DISP 3 "Grey_out" 2 "Disp(With_setting_parts)" 1 "Disp(No_setting_parts)" 0 "No_Disp" ;
VAL_ 843 ADAS34B_7_4_BRK_TIMING_PTN_DISP 3 "Grey_out" 2 "Disp(With_setting_parts)" 1 "Disp(No_setting_parts)" 0 "No_Disp" ;
VAL_ 843 ADAS34B_7_6_FCW_TIMING_PTN_DISP 3 "Grey_out" 2 "Disp(With_setting_parts)" 1 "Disp(No_setting_parts)" 0 "No_Disp" ;
VAL_ 843 ADAS34B_6_0_SAFTY_MODE_DISP_CONT 3 "Grey_out" 2 "Disp(With_setting_parts)" 1 "Disp(No_setting_parts)" 0 "No_Disp" ;
VAL_ 843 ADAS34B_6_2_SAFTY_MODE_LV_DISP 3 "Grey_out" 2 "Disp(With_setting_parts)" 1 "Disp(No_setting_parts)" 0 "No_Disp" ;
VAL_ 843 ADAS34B_6_4_SAFTY_MODE_LV_PTN 7 "No_Definition" 6 "No_Definition" 5 "No_Definition" 4 "No_Definition" 3 "Pattern④(Low/High)" 2 "Pattern③(Low/Middle)" 1 "Pattern②(Middle/High)" 0 "Pattern①(Low/Middle/High)" ;
VAL_ 843 ADAS34B_5_0_FCTI_DISP_CONT 3 "Grey_out" 2 "Disp(With_setting_parts)" 1 "Disp(No_setting_parts)" 0 "No_Disp" ;
VAL_ 843 ADAS34B_5_2_FCTI_NOTICE_DISP 3 "Grey_out" 2 "Disp(With_setting_parts)" 1 "Disp(No_setting_parts)" 0 "No_Disp" ;
VAL_ 843 ADAS34B_5_4_FCTI_SOUND_DISP_CONT 3 "Grey_out" 2 "Disp(With_setting_parts)" 1 "Disp(No_setting_parts)" 0 "No_Disp" ;
VAL_ 843 ADAS34B_5_6_FCTI_PULSE_DISP_CONT 3 "Grey_out" 2 "Disp(With_setting_parts)" 1 "Disp(No_setting_parts)" 0 "No_Disp" ;
VAL_ 843 ADAS34B_4_0_FCW_TYPE_DISP_CONT 3 "Grey_out" 2 "Disp(With_setting_parts)" 1 "Disp(No_setting_parts)" 0 "No_Disp" ;
VAL_ 843 ADAS34B_4_2_FCW_TYPE_SOUND_DISP 3 "Grey_out" 2 "Disp(With_setting_parts)" 1 "Disp(No_setting_parts)" 0 "No_Disp" ;
VAL_ 843 ADAS34B_4_4_FCW_TYPE_PULSE_DISP 3 "Grey_out" 2 "Disp(With_setting_parts)" 1 "Disp(No_setting_parts)" 0 "No_Disp" ;
VAL_ 843 ADAS34B_4_6_FCW_SOUND_SW_DISP 3 "Grey_out" 2 "Disp(With_setting_parts)" 1 "Disp(No_setting_parts)" 0 "No_Disp" ;
VAL_ 843 ADAS34B_3_0_P_CR_DISP_CONT 3 "Grey_out" 2 "Disp(With_setting_parts)" 1 "Disp(No_setting_parts)" 0 "No_Disp" ;
VAL_ 843 ADAS34B_3_2_BRAKE_TIMING_DISP 3 "Grey_out" 2 "Disp(With_setting_parts)" 1 "Disp(No_setting_parts)" 0 "No_Disp" ;
VAL_ 843 ADAS34B_3_4_FCW_DISP_CONT 3 "Grey_out" 2 "Disp(With_setting_parts)" 1 "Disp(No_setting_parts)" 0 "No_Disp" ;
VAL_ 843 ADAS34B_3_6_FCW_TIMING_DISP_PTN 3 "Pattern④(Near/Far)" 2 "Pattern③(Middle/Far)" 1 "Pattern②(Near/Middle)" 0 "Pattern①(Near/Middle/Far)" ;
VAL_ 841 ADAS349_4_0_AAOS_AEB_STATE 4 "USER_OVERRIDE" 2 "ACTIVATED" 1 "ENABLED" 0 "OTHER" ;
VAL_ 841 ADAS349_3_0_CID_MRM_DISP 9 "No_Definition" 8 "Pattern8" 7 "Pattern7" 6 "Pattern6" 5 "Pattern5" 4 "Pattern4" 3 "Pattern3" 2 "Pattern2" 1 "Pattern1" 0 "OFF" ;
VAL_ 1098 EVCC44A_3_0_PNC_CC_SAVE_RES_RSLT 5 "Fail_(Not_Exist)" 4 "Fail_(Retry_to_SRV)" 3 "Fail_(Retry_to_CECU)" 2 "Fail_(No_Retry)" 1 "Success" 0 "Unknown" ;
VAL_ 1096 EVCC448_4_0_EVSECONFPAYOPT 2 "EIM" 1 "PnC" ;
VAL_ 1096 EVCC448_3_0_PNC_SW_RES_EVCC 8 "Fail" 5 "NG_(OFF_LOCK)_Failed_to_set_OFF_LOCK" 4 "NG_(New)_Failed_to_set_NEW" 3 "NG_(Lock)_Failed_to_set_lock" 2 "NG_(ON)_Failed_to_set_ON" 1 "NG_(OFF)_Failed_to_set_OFF" 0 "No_NG" ;
VAL_ 1096 EVCC448_3_4_PNC_SW_STS 7 "Fail" 4 "New_State" 3 "Lock_State" 2 "On_State" 1 "Off_State" 0 "Undefined" ;
VAL_ 1096 EVCC448_3_7_SW_STS_ACTIVE_FLG 1 "Change" 0 "No_Change" ;
VAL_ 1093 EVCC445_4_0_CHGCNRLOCSTT_DISPREQ 2 "Lock_Display_Request" 1 "Unlock_Display_Request" 0 "Hidden" ;
VAL_ 1093 EVCC445_3_0_DISPREQ 1 "Request" 0 "No_Request" ;
VAL_ 1093 EVCC445_3_1_CNCTCONSTT_DISP 1 "Connector_Connected" 0 "Connector_Not_Connected" ;
VAL_ 1093 EVCC445_3_2_LIDOPSHSTT_DISP 2 "Lid_Open" 1 "Lid_Closed" 0 "Indeterminate" ;
VAL_ 1093 EVCC445_3_5_CNCTLCKSTT_DISP 2 "Locked_State" 1 "Unlocked_State" 0 "Initial" ;
VAL_ 1092 EVCC444_3_0_CNTCPLTYP 1 "NACS_(including_AC,_DC)" 0 "Undetermined" ;
VAL_ 1092 EVCC444_3_2_CHGFRM_CCU 2 "DC_Charging" 1 "AC_Charging" 0 "Undetermined" ;
VAL_ 1550 ENM60E_28_0_DRNDISPREQ 31 "排水前提条件不成立" 30 "排水動作不良" 29 "キャンセル完了" 28 "キャンセル中" 27 "" 26 "" 25 "" 24 "" 23 "" 22 "" 21 "" 20 "" 19 "" 18 "" 17 "" 16 "" 15 "" 14 "" 13 "" 12 "" 11 "" 10 "" 9 "" 8 "" 7 "" 6 "" 5 "" 4 "注水終了完了" 3 "注水終了中" 2 "排水準備完了" 1 "排水準備中" 0 "排水表示要求なし" ;
VAL_ 1550 ENM60E_27_0_INJDISPREQ 31 "注水前提条件不成立" 30 "注水動作不良" 29 "キャンセル完了" 28 "キャンセル中" 27 "" 26 "" 25 "" 24 "" 23 "" 22 "" 21 "" 20 "" 19 "" 18 "" 17 "" 16 "" 15 "" 14 "" 13 "" 12 "注水終了完了" 11 "注水終了中" 10 "エア抜き4回目完了" 9 "エア抜き4回目中" 8 "エア抜き3回目完了" 7 "エア抜き3回目中" 6 "エア抜き2回目完了" 5 "エア抜き2回目中" 4 "エア抜き1回目完了" 3 "エア抜き1回目中" 2 "注水準備完了" 1 "注水準備中" 0 "注水表示要求なし" ;
VAL_ 1550 ENM60E_26_0_HVBTHMADJSTT 1 "バッテリー温調ON" 0 "バッテリー温調OFF" ;
VAL_ 1550 ENM60E_26_1_ACNOFFCMD 3 "Pattern3" 2 "Pattern2" 1 "Pattern1" 0 "OFF" ;
VAL_ 1550 ENM60E_26_3_IJDRMDONOFF 1 "注水排水モードあり" 0 "注水排水モードなし" ;
VAL_ 1550 ENM60E_26_4_ACNHVDDRVADM 1 "許可" 0 "非許可" ;
VAL_ 1550 ENM60E_26_5_ACNINHSIG 1 "許可" 0 "禁止" ;
VAL_ 1549 ENM60D_2_0_TOWMDSTS 1 "ON" 0 "OFF" ;
VAL_ 1548 ENM60C_21_2_HVBTEMPSTT 7 "RESERVED" 6 "RESERVED" 5 "RESERVED" 4 "XTHOT" 3 "HOT" 2 "COLD" 1 "XTCOLD" 0 "OFF" ;
VAL_ 1548 ENM60C_20_4_OUTLMTDISREQ 7 "RESERVED" 6 "RESERVED" 5 "RESERVED" 4 "LV4" 3 "LV3" 2 "LV2" 1 "LV1" 0 "OFF（初期値）" ;
VAL_ 1548 ENM60C_20_7_CHGLMTDISREQ 7 "RESERVED" 6 "RESERVED" 5 "RESERVED" 4 "LV4" 3 "LV3" 2 "LV2" 1 "LV1" 0 "OFF（初期値）" ;
VAL_ 1548 ENM60C_14_0_PRCNSTT 3 "Reserved" 2 "Reserved" 1 "ON" 0 "OFF" ;
VAL_ 1548 ENM60C_14_2_PRCNSTTFBK 3 "Reserved" 2 "ON（CoolDOWN）" 1 "ON（WarmUP）" 0 "OFF" ;
VAL_ 1548 ENM60C_14_4_ACNLMTDISREQ 7 "RESERVED" 6 "RESERVED" 5 "RESERVED" 4 "LV4" 3 "LV3" 2 "LV2" 1 "LV1" 0 "OFF（初期値）" ;
VAL_ 1548 ENM60C_13_0_STCTDISPREQ 7 "RESERVED" 6 "RESERVED" 5 "RESERVED" 4 "RESERVED" 3 "RESERVED" 2 "ON(HOT)" 1 "ON(COOL)" 0 "OFF" ;
VAL_ 1548 ENM60C_13_3_VEHPRDDIS_JDG 7 "バッファ" 6 "バッファ" 5 "バッファ" 4 "バッファ" 3 "バッファ" 2 "--" 1 "ACOFF" 0 "ACON" ;
VAL_ 1548 ENM60C_13_6_PFOMDJDG 3 "未定義" 2 "点滅" 1 "点灯" 0 "OFF" ;
VAL_ 1548 ENM60C_10_0_PFOMDSTP 7 "未定義" 6 "未定義" 5 "未定義" 4 "未定義" 3 "未定義" 2 "未定義" 1 "あり" 0 "なし" ;
VAL_ 1548 ENM60C_10_3_HVBTHMADJSTT 7 "RESERVE" 6 "EMERGENCY" 5 "IMPROVING" 4 "MAX WARM" 3 "WARM" 2 "COOL" 1 "MAX COOL" 0 "OFF" ;
VAL_ 1548 ENM60C_10_6_PFOMDCNTN 1 "あり" 0 "なし" ;
VAL_ 1548 THM60C_10_7_PWRMDJDG 1 "ON" 0 "OFF" ;
VAL_ 1548 ENM60C_3_1_TRLSTSDISREQ 3 "RESERVE" 2 "ON (DISCONNECT)" 1 "ON (CONNECT)" 0 "OFF" ;
VAL_ 1548 ENM60C_3_3_TOWMDFAILDISREQ 1 "ON " 0 "OFF" ;
VAL_ 1548 ENM60C_3_6_CHGTIPDISPREQ 3 "RESERVE" 2 "ON (STOP)" 1 "ON" 0 "OFF" ;
VAL_ 857 THM359_5_1_HVBOUTLTEMPREL 3 "正常" 2 "異常" 1 "仮異常" 0 "未確定" ;
VAL_ 857 THM359_3_1_HVBINLTEMPREL 3 "正常" 2 "異常" 1 "仮異常" 0 "未確定" ;
VAL_ 857 THM359_3_3_IJDRMDTRFREQ 1 "注排水移行要求あり" 0 "注排水移行要求なし" ;
VAL_ 1116 CHR45C_9_0_LIDLOCK_DISC_DT 3 "Reserve" 2 "Normal" 1 "Error" 0 "Undetermined" ;
VAL_ 1116 CHR45C_9_2_LIDOP 3 "Reserve" 2 "Lid_Open" 1 "Lid_Closed" 0 "Indeterminate" ;
VAL_ 1116 CHR45C_8_2_LIDOP_BUZ_REQ 1 "HornRequest" 0 "NoHornRequest" ;
VAL_ 1116 CHR45C_8_1_LIDOP_WARDISP_REQ 1 "TextA" 0 "Norequest" ;
VAL_ 1116 CHR45C_8_0_CHG_CNRCNTSTT 1 "嵌合" 0 "未接続" ;
VAL_ 1116 CHR45C_3_0_CHGFEDSTT 6 "文言F" 5 "文言E" 4 "文言D" 3 "文言C" 2 "文言B" 1 "文言A" 0 "要求なし" ;
VAL_ 1111 CHR457_10_6_STLMT_TYPE 2 "Other_EIMPnC" 1 "PnC" 0 "EIM" ;
VAL_ 1111 CHR457_10_4_ACDC_INFO 2 "Other_ACDC" 1 "DC" 0 "AC" ;
VAL_ 1111 CHR457_6_4_DCPWRSUPSTOP_DISP 1 "Power_Supply_Stop_ON" 0 "Power_Supply_Stop_OFF" ;
VAL_ 1111 CHR457_6_0_DCPWRSUPSTRT_DISP 1 "Power_Supply_Start_ON" 0 "Power_Supply_Start_OFF" ;
VAL_ 1111 CHR457_5_0_CHGSTRTNTCE_DISP 1 "Start_Notification_Request_Present" 0 "No_Request" ;
VAL_ 1111 CHR457_5_4_CHGENDNTCE_DISP 1 "End_Notification_Request_Present" 0 "No_Request" ;
VAL_ 1111 CHR457_4_0_FEDSTPRSN_DISP 255 "Fail" 254 "Initial" 26 "Power_Supply_Error_Notification_Message_Display" 25 "Power_Supply_Error_Notification_Message_Display" 17 "Power_Supply_Error_Caution_Message_Display" 16 "Power_Supply_Error_Caution_Message_Display" 15 "Power_Supply_Error_Caution_Message_Display" 14 "Power_Supply_Error_Caution_Message_Display" 5 "Power_Supply_Error_Warning_Message_Display" 4 "Power_Supply_Error_Warning_Message_Display" 3 "Power_Supply_Error_Warning_Message_Display" 2 "Power_Supply_Error_Warning_Message_Display" 1 "Power_Supply_Error_Warning_Message_Display" ;
VAL_ 1111 CHR457_3_0_CHGSTPRSN_DISP 255 "Fail" 254 "Initial" 27 "Charging_Error_Notification_Message_Display" 26 "Charging_Error_Notification_Message_Display" 25 "Charging_Error_Notification_Message_Display" 18 "Charging_Error_Caution_Message_Display" 17 "Charging_Error_Caution_Message_Display" 16 "Charging_Error_Caution_Message_Display" 15 "Charging_Error_Caution_Message_Display" 14 "Charging_Error_Caution_Message_Display" 5 "Charging_Error_Warning_Message_Display" 4 "Charging_Error_Warning_Message_Display" 3 "Charging_Error_Warning_Message_Display" 2 "Charging_Error_Warning_Message_Display" 1 "Charging_Error_Warning_Message_Display" ;
VAL_ 1109 CHR455_31_3_CHGCNRLOCSTT_DISPREQ 2 "Lock_Display_Request" 1 "Unlock_Display_Request" 0 "Hidden" ;
VAL_ 1109 CHR455_27_4_V2H_MODE 1 "ON_(Charge/Discharge_Possible)" 0 "OFF" ;
VAL_ 1109 CHR455_26_4_DCPWRSUPSTT 255 "Not_Connected_or_Out_of_Range" 7 "Power_Supply_Abnormality" 6 "Connector_Fault" 5 "Power_Supply_Stopped" 4 "Power_Supplying" 3 "Communicating" 2 "Before_Power_Supply" 1 "Before_Connection" 0 "Non_Power_Supply" ;
VAL_ 1109 CHR455_26_3_CHGMNTDISP_REQ 1 "Request" 0 "No_Request" ;
VAL_ 1109 CHR455_26_2_MNTLIT_REQ 1 "Request" 0 "No_Request" ;
VAL_ 1109 CHR455_22_1_CHGSTPCOMP 1 "通知あり" 0 "通知なし" ;
VAL_ 1109 CHR455_18_2_STLMT_TYPE 1 "PnC" 0 "EIM" ;
VAL_ 1109 CHR455_18_1_ACDC_INFO 1 "DC" 0 "AC" ;
VAL_ 1109 CHR455_6_1_CHGSTT 255 "Not_Connected_or_Out_of_Range" 254 "Initial_Value" 9 "Warming_Up" 8 "Charging_Abnormality" 7 "Connector_Fault" 6 "Charging_Reservation_Standby" 5 "Charging_Complete" 4 "Charging" 3 "Communicating" 2 "Before_Charging" 1 "Before_Connection" 0 "Non_Charging" ;
VAL_ 1109 CHR455_4_6_DCCHG_PWRUPLMT 15 "Fail" 14 "Initial" 8 "50kW" 7 "75kW" 6 "100kW" 5 "125kW" 4 "150kW" 3 "175kW" 2 "200kW" 1 "225kW" 0 "Norequest" ;
VAL_ 1109 CHR455_4_2_ACCHG_CURUPLMT 15 "Fail" 14 "Initial" 6 "8A" 5 "12A" 4 "16A" 3 "24A" 2 "32A" 1 "40A" 0 "MAX" ;
VAL_ 1109 CHR455_3_1_CHG_CNRLOCSTT 3 "Undefined" 2 "LockState" 1 "UnlockState" 0 "Initial" ;
VAL_ 1109 CHR455_3_0_CHG_CNRCNTSTT 1 "Connector_Connected" 0 "Connector_Not_Connected" ;
